VERSION ""

NS_ :

BS_:

BU_: VDM CMR_DSMC SOBDMC_HPCM_FD1 IPMA_ADAS PSCM ABS_ESC TCCM TCM_DSL PCM_HEV PCM ECM_Diesel GENERIC_GWMWakeup GWM _delete TSTR
VAL_TABLE_ DcacRdy_D_Stat 7 "NotUsed_2" 6 "NotUsed_1" 5 "Faulted" 4 "ProtectionTempearture" 3 "ProtectionOverload" 2 "ProtectionGfci" 1 "Active" 0 "Idle" ;
VAL_TABLE_ HvacCmprLim_D_Stat 7 "NotUsed_2" 6 "NotUsed_1" 5 "CompressorHeadPressure" 4 "AvailableTorque" 3 "PedalPosition" 2 "RPM" 1 "ECT" 0 "NoLimit" ;
VAL_TABLE_ AdvStrt_D_Stat 15 "NotUsed_15" 14 "NotUsed_14" 13 "NotUsed_13" 12 "NotUsed_12" 11 "NotUsed_11" 10 "NotUsed_10" 9 "NotUsed_9" 8 "NotUsed_8" 7 "NotUsed_7" 6 "NotUsed_6" 5 "NotUsed_5" 4 "NotUsed_4" 3 "NotUsed_3" 2 "NotUsed_2" 1 "NotUsed_1" 0 "NoAction" ;
VAL_TABLE_ VehOnSrc_D_Stat 15 "NotUsed_11" 14 "NotUsed_10" 13 "NotUsed_9" 12 "NotUsed_8" 11 "NotUsed_7" 10 "NotUsed_6" 9 "NotUsed_5" 8 "NotUsed_4" 7 "NotUsed_3" 6 "NotUsed_2" 5 "NotUsed_1" 4 "OverTheAir" 3 "RemoteParkAssist" 2 "RemoteStart" 1 "Manual" 0 "Off" ;
VAL_TABLE_ NoMessage_Msg1_63 31 "Message31" 30 "Message30" 29 "Message29" 28 "Message28" 27 "Message27" 26 "Message26" 25 "Message25" 24 "Message24" 23 "Message23" 22 "Message22" 21 "Message21" 20 "Message20" 19 "Message19" 18 "Message18" 17 "Message17" 16 "Message16" 15 "Message15" 14 "Message14" 13 "Message13" 12 "Message12" 11 "Message11" 10 "Message10" 9 "Message9" 8 "Message8" 7 "Message7" 6 "Message6" 5 "Message5" 4 "Message4" 3 "Message3" 2 "Message2" 1 "Message1" 0 "NoMessage" ;
VAL_TABLE_ TrlrRvrseEnbl_D2_Stat 7 "NotUsed" 6 "TbaActiveExpertActive" 5 "TbaActiveExpertAvail" 4 "TbaOffTrgActive" 3 "TbaOffTrgSetup" 2 "TbaSetup" 1 "TbaActive" 0 "Inactive" ;
VAL_TABLE_ Off_On_FlashChime 7 "NotUsed_5" 6 "NotUsed_4" 5 "NotUsed_3" 4 "NotUsed_2" 3 "NotUsed_1" 2 "FlashChime" 1 "On" 0 "Off" ;
VAL_TABLE_ DieslPrtcWarn_D_Rq 15 "NotUsed_4" 14 "NotUsed_3" 13 "NotUsed_2" 12 "NotUsed_1" 11 "OCR_ExhFilterClean_Stopped" 10 "OCR_ExhFilterCleaned" 9 "RgnOff_AtLimit" 8 "RgnOff_OverLoaded" 7 "RgnOff_Loaded" 6 "Exhaust_Filter_Full" 5 "DPF_OverLimit" 4 "DPF_AtLimit" 3 "ExhFilter_Drive_Completed" 2 "Cleaning_Exhaust_Filter" 1 "DPF_OverLoaded" 0 "DPF_Normal_Operation" ;
VAL_TABLE_ StrtrMtrCtlMsgTxt_D2_Rq 3 "NotUsed" 2 "ShiftToNeutralToStart" 1 "ShiftToParkToStart" 0 "NoRequest" ;
VAL_TABLE_ PaakMyKey_D_Rq 3 "NotUsed" 2 "ConfirmNewPaakMyKey" 1 "RequestNewPaakMyKey" 0 "None" ;
VAL_TABLE_ PaakMyKeySearch_D_Stat 7 "PhoneErased" 6 "LockButtonTimeOut" 5 "PressLockButton" 4 "ConfirmHmi" 3 "MyKeyPaakFound" 2 "StandardPaakFound" 1 "NoValidPaakFound" 0 "Null" ;
VAL_TABLE_ TrlrIdType_D_Stat 3 "Gooseneck" 2 "FifthWheel" 1 "Conventional" 0 "Null" ;
VAL_TABLE_ TrlrAidSetup_D2_Rq 15 "NotUsed_9" 14 "NotUsed_8" 13 "NotUsed_7" 12 "NotUsed_6" 11 "NotUsed_5" 10 "NotUsed_4" 9 "NotUsed_3" 8 "NotUsed_2" 7 "NotUsed_1" 6 "CompleteSetup" 5 "ReturnToSetup" 4 "StickerNotCircled" 3 "ConfirmSetup" 2 "EndSetup" 1 "BeginSetup" 0 "Inactive" ;
VAL_TABLE_ TrlrAidEnbl_D2_Rq 7 "NotUsed_4" 6 "NotUsed_3" 5 "NotUsed_2" 4 "NotUsed_1" 3 "Deactivate" 2 "ActivateTrg" 1 "ActivateTba" 0 "Inactive" ;
VAL_TABLE_ BattChrgMde_D_Actl 3 "NotUsed" 2 "ConstantCurrent" 1 "ConstantVoltage" 0 "NotCharging" ;
VAL_TABLE_ LcwaLeft_D_Stat 7 "Faulty" 6 "NotUsed_3" 5 "NotUsed_2" 4 "NotUsed_1" 3 "Disabled" 2 "TemporaryUnavailable" 1 "SensorBlocked" 0 "Available" ;
VAL_TABLE_ LcwaMsgTxt_D_Stat 3 "SodXFaulty" 2 "SodXBlocked" 1 "TrailerConnected" 0 "NoMessage" ;
VAL_TABLE_ Level_0_3 3 "Level_3" 2 "Level_2" 1 "Level_1" 0 "Level_0" ;
VAL_TABLE_ SteWhlSwtchMde_D_Stat 3 "NotUsed_2" 2 "NotUsed_1" 1 "Dialog" 0 "Domain" ;
VAL_TABLE_ TrlrRvrse_D_Stat 3 "Faulty" 2 "TrailerReverseGuidanceLite" 1 "On" 0 "Off" ;
VAL_TABLE_ TrlrAid_D2_Stat 15 "Faulty" 14 "NotUsed_4" 13 "NotUsed_3" 12 "NotUsed_2" 11 "NotUsed_1" 10 "DirtyCamera" 9 "IncorrectLighting" 8 "TrackingLost" 7 "TrackingUnknownConfidence" 6 "TrackingHighConfidence" 5 "TrackingMediumConfidence" 4 "TrackingLowConfidence" 3 "TurnRequested" 2 "DriveStraighRequested" 1 "Initializing" 0 "NotTracking" ;
VAL_TABLE_ AwdDrvMde_D2 15 "Faulty" 14 "NotUsed_7" 13 "NotUsed_6" 12 "NotUsed_5" 11 "NotUsed_4" 10 "NotUsed_3" 9 "NotUsed_2" 8 "NotUsed_1" 7 "NotAvailable" 6 "TowHaul" 5 "RockCrawl" 4 "Baja" 3 "MudAndSand" 2 "Weather" 1 "Sport" 0 "Normal" ;
VAL_TABLE_ TrlrAidSetup_D2_Stat 7 "NotUsed_2" 6 "NotUsed_1" 5 "SetupAcquisitionSuccess" 4 "TbaTadMonitor" 3 "SetupStartAcquisition" 2 "SetupPrepForAcquisition" 1 "TbaActive" 0 "Null" ;
VAL_TABLE_ CamraRearOn_D2_Stat2 7 "Faulty" 6 "NotUsed_3" 5 "NotUsed_2" 4 "NotUsed_1" 3 "Decommission" 2 "Activate" 1 "Deactivate" 0 "Null" ;
VAL_TABLE_ AirCondClu_D_Stat 7 "NotUsed" 6 "FetLifeLimitReached" 5 "FetOpenCircuit" 4 "FetOutputShortToPower" 3 "FetOutputShortToGround" 2 "FetNotControlled" 1 "OnPowerToLoad" 0 "OffNoPowerToLoad" ;
VAL_TABLE_ BattChrgTrgtSoC_D_Rq 7 "Percent_50" 6 "Percent_60" 5 "Percent_70" 4 "Percent_80" 3 "Percent_85" 2 "Percent_90" 1 "Percent_95" 0 "Percent_100" ;
VAL_TABLE_ OffNormalSoft 3 "NotUsed" 2 "Soft" 1 "Normal" 0 "Off" ;
VAL_TABLE_ OffOnDisabledInhibited 3 "Inhibited" 2 "Disabled" 1 "On" 0 "Off" ;
VAL_TABLE_ DgtlCommGtwyMde_D_Rq 15 "NotUsed_10" 14 "NotUsed_9" 13 "NotUsed_8" 12 "NotUsed_7" 11 "NotUsed_6" 10 "NotUsed_5" 9 "NotUsed_4" 8 "NotUsed_3" 7 "NotUsed_2" 6 "NotUsed_1" 5 "AcPnC" 4 "AcEIM" 3 "DcPnC" 2 "DcEIM" 1 "AttemptDgtlComm" 0 "NoDgtlComm" ;
VAL_TABLE_ BattDcCnnct_D_Cmd 7 "NotUsed_3" 6 "NotUsed_2" 5 "NotUsed_1" 4 "WeldCheck" 3 "OkToDischarge" 2 "Closed" 1 "Precharge" 0 "Open" ;
VAL_TABLE_ Null_NoFault_Fault 3 "NotUsed" 2 "Fault" 1 "NoFault" 0 "Null" ;
VAL_TABLE_ ModemReset_D_Rq 15 "NotUsed_11" 14 "NotUsed_10" 13 "NotUsed_9" 12 "NotUsed_8" 11 "NotUsed_7" 10 "NotUsed_6" 9 "NotUsed_5" 8 "NotUsed_4" 7 "NotUsed_3" 6 "BrandConnectReset2" 5 "BrandConnectReset1" 4 "CcsReset" 3 "OnlineTrafficReset" 2 "PaakReset" 1 "WifiHotspotReset" 0 "Null" ;
VAL_TABLE_ PrkAsstSlotId_D_Stat 7 "Faulty" 6 "Slot6" 5 "Slot5" 4 "Slot4" 3 "Slot3" 2 "Slot2" 1 "Slot1" 0 "NoSlotFound" ;
VAL_TABLE_ RstrnOnPsngr_D_RqMnu 15 "Faulty" 14 "NotUsed_11" 13 "NotUsed_10" 12 "ConfiguredOff" 11 "NotUsed_9" 10 "On" 9 "NotUsed_8" 8 "NotUsed_7" 7 "NotUsed_6" 6 "NotUsed_5" 5 "Off" 4 "NotUsed_4" 3 "NotUsed_3" 2 "NotUsed_2" 1 "NotUsed_1" 0 "NoAction" ;
VAL_TABLE_ BalrInnrLeft_D_Stat 3 "Reporting" 2 "NotReporting" 1 "SystemStandby" 0 "Initialization" ;
VAL_TABLE_ Zero_1_2_4 3 "Four" 2 "Two" 1 "One" 0 "Zero" ;
VAL_TABLE_ NoReq_AutoUp_Stop 3 "NotUsed" 2 "Stop" 1 "AutoUp" 0 "NoRequest" ;
VAL_TABLE_ BalrSnsLeft_D_Falt 3 "Invalid" 2 "SystemFailure" 1 "Blocked" 0 "Clear" ;
VAL_TABLE_ Null_Low_Med_High 3 "High" 2 "Medium" 1 "Low" 0 "Null" ;
VAL_TABLE_ Null_NotPressed_Pressed 3 "NotUsed" 2 "Pressed" 1 "NotPressed" 0 "Null" ;
VAL_TABLE_ Low_Med_High 3 "NotUsed" 2 "High" 1 "Medium" 0 "Low" ;
VAL_TABLE_ Null_NotAvail_Avail 3 "NotUsed" 2 "Available" 1 "NotAvailable" 0 "Null" ;
VAL_TABLE_ ChrgGoTMnte_D_Stat 15 "NotUsed_4" 14 "NotUsed_3" 13 "NotUsed_2" 12 "NotUsed_1" 11 "Minute_55" 10 "Minute_50" 9 "Minute_45" 8 "Minute_40" 7 "Minute_35" 6 "Minute_30" 5 "Minute_25" 4 "Minute_20" 3 "Minute_15" 2 "Minute_10" 1 "Minute_5" 0 "Minute_0" ;
VAL_TABLE_ NoData_Faulty_1E_1F 31 "Faulty" 30 "NoDataExists" ;
VAL_TABLE_ PwFlwBatt_D_Dsply 15 "NotUsed_8" 14 "NotUsed_7" 13 "NotUsed_6" 12 "NotUsed_5" 11 "NotUsed_4" 10 "NotUsed_3" 9 "NotUsed_2" 8 "NotUsed_1" 7 "FlwFromWallToBatt" 6 "FlwFromAllWhlsToBatt" 5 "FlwFromBattToAllWhls" 4 "FlwFromFrontWhlsToBatt" 3 "FlwFromBattToFrontWhls" 2 "FlwFromRearWhlsToBatt" 1 "FlwFromBattToRearWhls" 0 "NoFlow" ;
VAL_TABLE_ PwFlwFuelDrv_D_Dsply 7 "NotUsed_4" 6 "NotUsed_3" 5 "NotUsed_2" 4 "NotUsed_1" 3 "FlwFromFuelToAllWhls" 2 "FlwFromFuelToFrontWhls" 1 "FlwFromFuelToRearWhls" 0 "NoFlow" ;
VAL_TABLE_ TrlrAidMsgTxt_D2_Rq 63 "Message63" 62 "Message62" 61 "Message61" 60 "Message60" 55 "Message55" 50 "Message50" 45 "Message45" 40 "Message40" 35 "Message35" 31 "Message31" 30 "Message30" 29 "Message29" 28 "Message28" 27 "Message27" 26 "Message26" 25 "Message25" 24 "Message24" 23 "Message23" 22 "Message22" 21 "Message21" 20 "Message20" 19 "Message19" 18 "Message18" 17 "Message17" 16 "Message16" 15 "Message15" 14 "Message14" 13 "Message13" 12 "Message12" 11 "Message11" 10 "Message10" 9 "Message9" 8 "Message8" 7 "Message7" 6 "Message6" 5 "Message5" 4 "Message4" 3 "Message3" 2 "Message2" 1 "Message1" 0 "NoMessage" ;
VAL_TABLE_ TrlrAidEnbl_D2_Stat 7 "NotUsed_1" 6 "TbaActiveExpertActive" 5 "TbaActiveExpertAvail" 4 "TbaOffTrgActive" 3 "TbaOffTrgSetup" 2 "TbaSetup" 1 "TbaActive" 0 "Inactive" ;
VAL_TABLE_ RbaCta_D_Stat 7 "Faulty" 6 "NotUsed_2" 5 "NotUsed_1" 4 "Invalid" 3 "Disabled" 2 "On" 1 "Trailer_Tow_Off" 0 "Off" ;
VAL_TABLE_ NoRequest_Mode1_2_3 3 "Mode_3" 2 "Mode_2" 1 "Mode_1" 0 "NoRequest" ;
VAL_TABLE_ RvltnMatchAllw_D_Stat 3 "RevolutionMatchDisabled" 2 "RevolutionMatchEnabled" 1 "ChangeWithDriveMode" 0 "NoSelection" ;
VAL_TABLE_ BattTracCnnct_D_Cmd 7 "NotUsed_3" 6 "NotUsed_2" 5 "NotUsed_1" 4 "WeldCheck" 3 "OkToDischarge" 2 "Closed" 1 "Precharge" 0 "Open" ;
VAL_TABLE_ NotDiagnose_FailPass 3 "NotUsed" 2 "Pass" 1 "Fail" 0 "Not_Diagnose_Yet" ;
VAL_TABLE_ Null_Off_UnavailFaulty 3 "Faulty" 2 "Unavailable" 1 "Off" 0 "Null" ;
VAL_TABLE_ OffOnDisabledNotUsed 3 "NotUsed" 2 "Disabled" 1 "On" 0 "Off" ;
VAL_TABLE_ OffGraphicTextBoth 3 "Both" 2 "Text" 1 "Graphic" 0 "Off" ;
VAL_TABLE_ NoneInactiveActive_NotUsed 3 "NotUsed" 2 "Active" 1 "Inactive" 0 "None" ;
VAL_TABLE_ Off_On_NotUsed 3 "NotUsed_2" 2 "NotUsed_1" 1 "On" 0 "Off" ;
VAL_TABLE_ RbaSys_D_Stat 3 "Faulty" 2 "Available" 1 "Suspended" 0 "Disabled" ;
VAL_TABLE_ BrkAppl_D_RqPt 3 "BrakesSlowRelease" 2 "BrakesFastRelease" 1 "BrakesEngage" 0 "NotActive" ;
VAL_TABLE_ Mtr2State_D_ActlMntr 7 "Faulty" 6 "NoDataExists" 5 "NotUsed_1" 4 "ReadinessState" 3 "DeactivationState" 2 "PowerGeneration" 1 "PowerConsumption" 0 "Null" ;
VAL_TABLE_ HybVehMde_D_ActlMntr 7 "Faulty" 6 "NoDataExists" 5 "NotUsed_2" 4 "NotUsed_1" 3 "Fuel" 2 "HybridElectric" 1 "AllElectric" 0 "Null" ;
VAL_TABLE_ ChrgStat_D_ActlMntr 7 "Faulty" 6 "NoDataExists" 5 "NotUsed" 4 "ChargingCompleted" 3 "NotCharging" 2 "ChargingInDrivingState" 1 "ChargingInParkingState" 0 "Null" ;
VAL_TABLE_ Null_HiPower_Low_Med 3 "MediumPower" 2 "LowPower" 1 "HighPower" 0 "Null" ;
VAL_TABLE_ Inactive_Enable_Disable_NotUsed 0 "Inactive" 2 "Disable" 1 "Enable" ;
VAL_TABLE_ Inactive_OffOn_NotUsed 0 "Inactive" 1 "On" 2 "Off" 3 "NotUsed" ;
VAL_TABLE_ Null_NotPressed_Faulty 3 "Faulty" 2 "Pressed" 1 "NotPressed" 0 "Null" ;
VAL_TABLE_ TrailCtl_D_Stat 7 "Faulty" 6 "DescentOnly" 5 "EnabledDeny" 4 "StandbyOverThreshold" 3 "StandbyOverride" 2 "Active" 1 "EnabledDescent" 0 "Off" ;
VAL_TABLE_ Faulty_3F 63 "Faulty" ;
VAL_TABLE_ ChrgOvrdExitScrn_D_Rq 3 "NotUsed_1" 2 "Request_override" 1 "Do_not_request_override" 0 "Inactive" ;
VAL_TABLE_ Quality_Data_Faulty 3 "OK" 2 "Not_Within_Specifications" 1 "Eval_In_Progress" 0 "Faulty" ;
VAL_TABLE_ TrlrHitchYaw_D_Stat 15 "Faulty" 14 "NotUsed_4" 13 "NotUsed_3" 12 "NotUsed_2" 11 "NotUsed_1" 10 "FaultyYrsuConnection" 9 "FaultyYrsu" 8 "HiConfdLrndAngle" 7 "LowConfdLrndAngle" 6 "HiConfdAngleMem" 5 "LowConfdAngleMem" 4 "InitNoTadAngle" 3 "InitInputs" 2 "TadTrlrDataOutOfRange" 1 "TadNotWithinSpecification" 0 "NoConnectionWithYrsu" ;
VAL_TABLE_ NoData_Faulty_FFFFFFFFFFFE_FF -1 "Faulty_FFFFFFFFFFFF" -2 "NoDataExists_FFFFFFFFFFFE" ;
VAL_TABLE_ NoFault_Fault 1 "Fault" 0 "No_Fault" ;
VAL_TABLE_ OtaTrg_D_Stat 3 "NotUsed_1" 2 "Accepted" 1 "NotAccepted" 0 "Null" ;
VAL_TABLE_ EdmMsgTxt_D_Rq 15 "NotUsed_4" 14 "NotUsed_3" 13 "NotUsed_2" 12 "NotUsed_1" 11 "OverallGoodScore" 10 "WorkOnCompliance" 9 "GoodCompliance" 8 "WorkOnGearShifting" 7 "GoodGearShifting" 6 "WorkOnEfficientSpeed" 5 "GoodEfficientSpeed" 4 "WorkOnDeceleration" 3 "GoodDeceleration" 2 "WorkOnAcceleration" 1 "GoodAcceleration" 0 "NoMessage" ;
VAL_TABLE_ EdmLamp_D_Dsply 15 "NotUsed_7" 14 "NotUsed_6" 13 "NotUsed_5" 12 "NotUsed_4" 11 "NotUsed_3" 10 "NotUsed_2" 9 "NotUsed_1" 8 "CoastingEngineBrake" 7 "CoastingShiftToNeutral" 6 "FreewayJunction" 5 "Curve2" 4 "Curve1" 3 "SpeedLimit" 2 "Crossing" 1 "FreewayExit" 0 "NoRecommendation" ;
VAL_TABLE_ AwdCnnct_D_Stat 3 "Connecting" 2 "Disconnecting" 1 "Connected" 0 "Disconnected" ;
VAL_TABLE_ EngAirFiltMsgTxt_D_Rq 7 "NotUsed_2" 6 "NotUsed_1" 5 "EngineAirFilterMonitorFalt" 4 "ResetComplete" 3 "Clogged" 2 "ReplaceNow" 1 "ReplaceSoon" 0 "NoMessage" ;
VAL_TABLE_ ElPwPoint_D_Rq 3 "On" 2 "Off2" 1 "Off1" 0 "Null" ;
VAL_TABLE_ EngExhMdeQuiet_D2_Rq 7 "NotUsed_3" 6 "NotUsed_2" 5 "NotUsed_1" 4 "Track" 3 "Sport" 2 "Normal" 1 "Stealth" 0 "Null" ;
VAL_TABLE_ RearDiffThrml_D_Stat 3 "NotUsed_1" 2 "AboveThermalLimit" 1 "ThermalLimit" 0 "Normal" ;
VAL_TABLE_ NoInhibit_Inhibit 1 "Inhibit" 0 "NoInhibit" ;
VAL_TABLE_ PersRecallSrc_D_Actl 7 "NotUsed_3" 6 "NotUsed_2" 5 "NotUsed_1" 4 "MemorySwitch" 3 "RemoteStart" 2 "KeyFob" 1 "CenterStack" 0 "Null" ;
VAL_TABLE_ BattTracChiller_D_Stat 3 "NotUsed" 2 "ChillerNotAvailable" 1 "ChillerBrieflyAvailable" 0 "ChillerAvailable" ;
VAL_TABLE_ SelDrvMdeChassis2_D_Rq 31 "Faulty" 30 "NotUsed17" 29 "NotUsed16" 28 "NotUsed15" 27 "NotUsed14" 26 "NotUsed13" 25 "NotUsed12" 24 "NotUsed11" 23 "NotUsed10" 22 "NotUsed9" 21 "NotUsed8" 20 "NotUsed7" 19 "NotUsed6" 18 "NotUsed5" 17 "NotUsed4" 16 "NotUsed3" 15 "NotUsed2" 14 "RoughRoadMode" 13 "TrackMode" 12 "HighSpeedDesertMode" 11 "TowHaulMode" 10 "RockCrawlMode" 9 "SandMode" 8 "MudAndRutsMode" 7 "LowMuMode" 6 "ComfortAdaptiveMode" 5 "ComfortMode" 4 "SportAdaptiveMode" 3 "SportMode" 2 "EconomyMode" 1 "NormalAdaptiveMode" 0 "NormalMode" ;
VAL_TABLE_ TrnFaltOpenClu_B_Stat 1 "MayOpenClutch" 0 "Normal" ;
VAL_TABLE_ UrbanAreaDetct_D_Stat 3 "NotUsed_1" 2 "City" 1 "Subdivision" 0 "None" ;
VAL_TABLE_ Closed_Open 1 "Open" 0 "Closed" ;
VAL_TABLE_ AdbBrdrDist 15 "DistGreater800m" 14 "Dist700mTo800m" 13 "Dist600mTo700m" 12 "Dist500mTo600m" 11 "Dist400mTo500m" 10 "Dist300mTo400m" 9 "Dist200mTo300m" 8 "Dist175mTo200m" 7 "Dist150mTo175m" 6 "Dist125mTo150m" 5 "Dist100mTo125m" 4 "Dist75mTo100m" 3 "Dist50mTo75m" 2 "Dist25mTo50m" 1 "Dist15mTo25m" 0 "Dist0mTo15m" ;
VAL_TABLE_ TCU_ESN_D_Rq 3 "NotUsed" 2 "TCU_ESN_Request" 1 "NoRequest" 0 "Inactive" ;
VAL_TABLE_ FactoryReset_Rq 1 "ResetFactoryDefaults" 0 "Inactive" ;
VAL_TABLE_ TCU_Init_Actvtn_St 3 "NotUsed" 2 "InitialActivateDeny" 1 "InitialActivateAccept" 0 "Invalid" ;
VAL_TABLE_ TCU_Final_Actvtn_St 3 "NotUsed" 2 "FinalActivateDeny" 1 "FinalActivateAccept" 0 "Invalid" ;
VAL_TABLE_ WaitToStartLamp_D_Falt 3 "NotUsed" 2 "Wait_to_start_lamp_failed" 1 "Diagnosis_not_ready" 0 "Wait_to_start_lamp_OK" ;
VAL_TABLE_ BattTracCoolLvl_D_Rq 7 "Faulty" 6 "NotUsed" 5 "ChillerCoolingBattFirst" 4 "ChillerCoolingCabinFirst" 3 "ForcedCoolingRadiator" 2 "OpportunisticCoolingRad" 1 "CoolantFlowBypassLine" 0 "Off" ;
VAL_TABLE_ BattClntVlvOvrrd_D_Rq 3 "NotUsed" 2 "OverrideTbcvToChiller" 1 "OverrideTbcvToRadiator" 0 "NoOverrideToTbcvCLogic" ;
VAL_TABLE_ NonMagnetic_Magnetic 1 "Magnetic" 0 "NonMagnetic" ;
VAL_TABLE_ RideHghtMde_D_Stat 15 "Faulty" 14 "NotUsed_5" 13 "NotUsed_4" 12 "NotUsed_3" 11 "NotUsed_2" 10 "NotUsed_1" 9 "AdjUpAero" 8 "AdjUpOffRoad" 7 "AdjUpNormal" 6 "AdjDownKneel" 5 "AdjDownAero" 4 "AdjDownNormal" 3 "OffRoad" 2 "Kneel" 1 "Aero" 0 "Normal" ;
VAL_TABLE_ AutoTowAllw_D_StatMnu 3 "TowHaulCommandedOn" 2 "AutoTowHaulEnabled" 1 "AutoTowHaulDisabled" 0 "NoSelection" ;
VAL_TABLE_ SrpEventRight_D_Stat 3 "Faulty" 2 "Bump" 1 "Pothole" 0 "NoEvent" ;
VAL_TABLE_ RearDiff_D_Stat 15 "NotUsed_7" 14 "NotUsed_6" 13 "NotUsed_5" 12 "NotUsed_4" 11 "NotUsed_3" 10 "NotUsed_2" 9 "NotUsed_1" 8 "TorqueReqNotHonored" 7 "MissingSignal" 6 "ModuleFault" 5 "HydroTempSensorFault" 4 "ClutchPressSensorFault" 3 "AccumPressSensorFault" 2 "ControlValveFault" 1 "MotorFault" 0 "Normal" ;
VAL_TABLE_ NotAllowed_Allowed 1 "Allowed" 0 "NotAllowed" ;
VAL_TABLE_ EngTrlrCnnct_D_Stat 3 "NotUsed_1" 2 "UnverifiedTrailer" 1 "HeavyTrailer" 0 "NoTrailer" ;
VAL_TABLE_ Faulty_FFFF 65535 "Faulty" ;
VAL_TABLE_ NoData_Faulty_3FFE_3FFF 16383 "Faulty" 16382 "NoDataExists" ;
VAL_TABLE_ Faulty_3FFF 16383 "Faulty" ;
VAL_TABLE_ NotExceeded_Exceeded 1 "Exceeded" 0 "NotExceeded" ;
VAL_TABLE_ EmgcyCall_D_Stat 7 "NotUsed_3" 6 "NotUsed_2" 5 "NotUsed_1" 4 "ManualEmergencyCall" 3 "AutoEmergencyCall" 2 "NoEvent" 1 "EmergencyCallNotSupported" 0 "Null" ;
VAL_TABLE_ NotAsserted_Asserted 1 "Asserted" 0 "NotAsserted" ;
VAL_TABLE_ AirSprngRate_D_Stat 3 "Faulty" 2 "Firm" 1 "Medium" 0 "Soft" ;
VAL_TABLE_ AirSprngRate_D_Rq 3 "NoRequest" 2 "Firm" 1 "Medium" 0 "Soft" ;
VAL_TABLE_ GearLvr_D_ActlDrv 15 "Fault" 14 "Unknown_Position" 13 "NotUsed_2" 12 "NotUsed_1" 11 "Range6" 10 "Range5" 9 "Range4" 8 "Range3_M3_L3" 7 "Range2_M2_L2" 6 "Range1_M1_L1" 5 "Low" 4 "Sport_DriveSport_Mposition" 3 "Drive" 2 "Neutral" 1 "Reverse" 0 "Park" ;
VAL_TABLE_ ChrgrInPwMde_D_Actl 15 "NotUsed_9" 14 "NotUsed_8" 13 "NotUsed_7" 12 "NotUsed_6" 11 "NotUsed_5" 10 "NotUsed_4" 9 "NotUsed_3" 8 "EvseFault" 7 "EvseNotCompatible" 6 "IcCharging" 5 "DcCharging" 4 "AcDigital" 3 "AcBasic" 2 "DigitalCommDetected" 1 "EvsePaused" 0 "EvseNotDetected" ;
VAL_TABLE_ ChrgCordLck_D_Stat 7 "Faulty" 6 "LockFail" 5 "UnlockFail" 4 "LockInProgress" 3 "UnlockInProgress" 2 "Lock" 1 "Unlock" 0 "Retain" ;
VAL_TABLE_ LkaActvStats_D2_Req 7 "NotUsed" 6 "LkaIncrIntervRight" 5 "LkaSupprRight" 4 "LkaStandIntervRight" 3 "LkaSupprLeft" 2 "LkaStandIntervLeft" 1 "LkaIncrIntervLeft" 0 "LkaNoInterv" ;
VAL_TABLE_ OffOnNoDataFaulty 3 "Faulty" 2 "No_Data_Exists" 1 "On" 0 "Off" ;
VAL_TABLE_ NoMessage_Msg1_3 3 "Message3" 2 "Message2" 1 "Message1" 0 "NoMessage" ;
VAL_TABLE_ TrnRng_D_RqGsm 15 "Fault" 14 "UnknownPosition" 13 "Undefined_2" 12 "Undefined_1" 11 "_6" 10 "_5" 9 "_4" 8 "_3" 7 "_2" 6 "_1" 5 "Low" 4 "Sport_DriveSport" 3 "Drive" 2 "Neutral" 1 "Reverse" 0 "Park" ;
VAL_TABLE_ PrkBrkActv_D_RqGsmGear 3 "NotUsed" 2 "RequestParkBrakeEngage" 1 "NoRequest" 0 "Null" ;
VAL_TABLE_ TrnPrkSys_D_Actl 15 "Faulty" 14 "NotUsed_5" 13 "NotUsed_4" 12 "NotUsed_3" 11 "NotUsed_2" 10 "NotUsed_1" 9 "FrequencyError" 8 "OutOfRangeHigh" 7 "OutOfRangeLow" 6 "Override" 5 "OutOfPark" 4 "TransitionCloseToOutOfPark" 3 "AtNoSpring" 2 "TransitionCloseToPark" 1 "Park" 0 "NotKnown" ;
VAL_TABLE_ OKLowUnknownInvalid 3 "Invalid" 2 "Unknown" 1 "Low" 0 "OK" ;
VAL_TABLE_ Dsp_RotAddrBtnEv_St 15 "NotUsed_1" 14 "Pos_7Steps" 13 "Pos_6Steps" 12 "Pos_5Steps" 11 "Pos_4Steps" 10 "Pos_3Steps" 9 "Pos_2Steps" 8 "Pos_1Step" 7 "NotPressed" 6 "Neg_1Steps" 5 "Neg_2Steps" 4 "Neg_3Steps" 3 "Neg_4Steps" 2 "Neg_5Steps" 1 "Neg_6Steps" 0 "Neg_7Steps" ;
VAL_TABLE_ PrkAidDrvDir_D_Stat 7 "NotUsed_2" 6 "NotUsed_1" 5 "BackwardNegative" 4 "ForwardNegative" 3 "BackwardPositive" 2 "ForwardPositive" 1 "NoMotion" 0 "DirectionNotKnown" ;
VAL_TABLE_ EngExhMdeQuiet_D2_Stat 7 "Faulty" 6 "NotUsed_2" 5 "NotUsed_1" 4 "Track" 3 "Sport" 2 "Normal" 1 "Stealth" 0 "Null" ;
VAL_TABLE_ GasPrtc_D_RqDsply 7 "NotUsed_5" 6 "NotUsed_4" 5 "NotUsed_3" 4 "NotUsed_2" 3 "NotUsed_1" 2 "GpfOverLimit" 1 "GpfAtLimit" 0 "NormalOperation" ;
VAL_TABLE_ TjaWarn_D_Rq 7 "NotUsed_4" 6 "NotUsed_3" 5 "NotUsed_2" 4 "NotUsed_1" 3 "HardTakeOverLevel2" 2 "HardTakeOverLevel1" 1 "TrafficJamAssistCancel" 0 "NoWarning" ;
VAL_TABLE_ Faulty_7FF 2047 "Faulty" ;
VAL_TABLE_ Tja_D_Stat 7 "NotUsed_1" 6 "ActiveWarningRight" 5 "ActiveWarningLeft" 4 "ActiveInterventionRight" 3 "ActiveInterventionLeft" 2 "Active" 1 "Standby" 0 "Off" ;
VAL_TABLE_ TjaMsgTxt_D_Dsply 7 "NotUsed_4" 6 "NotUsed_3" 5 "NotUsed_2" 4 "NotUsed_1" 3 "TurnOnAdaptCruiseControl" 2 "TrafficJamAssistSelected" 1 "TrafficJamAssistUnavailabl" 0 "NoMessage" ;
VAL_TABLE_ PwSrcULowMde_D_Actl 3 "NotUsed_1" 2 "ReverseBoost" 1 "ForwardBuck" 0 "Standby" ;
VAL_TABLE_ ApaTrgtDist_D_Stat 15 "Step15" 14 "Step14" 13 "Step13" 12 "Step12" 11 "Step11" 10 "Step10" 9 "Step9" 8 "Step8" 7 "Step7" 6 "Step6" 5 "Step5" 4 "Step4" 3 "Step3" 2 "Step2" 1 "Step1" 0 "Off" ;
VAL_TABLE_ Memory_2_SwPsngr_Stat 1 "Pressed" 0 "Null" ;
VAL_TABLE_ Pers3Key_D_Stat 3 "NotUsed_1" 2 "KeyUnAssociated" 1 "KeyAssociated" 0 "Null" ;
VAL_TABLE_ PwSrcULoMde_D_Rq 3 "NotUsed_1" 2 "ReverseBoost" 1 "ForwardBuck" 0 "Standby" ;
VAL_TABLE_ AccMsgTxt_D2_Rq 15 "NotUsed_1" 14 "NCC_Enabled_Warning" 13 "IACC_TJA_Selected" 12 "ACC_TJA_Selected" 11 "IACC_Selected" 10 "Press_Brake_To_Hold" 9 "Only_Following_In_Low_Spd" 8 "TJA_Unavailable" 7 "Shift_Down" 6 "IACC_Unavailable" 5 "ACC_Selected" 4 "ACC_Overridden" 3 "Brake_Capacity_Warning" 2 "ACC_Cancelled" 1 "ACC_Unavailable" 0 "No_Text" ;
VAL_TABLE_ WakeAlarm0_B_Typ 1 "CanAndEcuDriveCircuit" 0 "CanOnly" ;
VAL_TABLE_ WakeAlarm0_D_Stat 3 "PublisherReset" 2 "Wake" 1 "AlarmRunning" 0 "AlarmOff" ;
VAL_TABLE_ EmPrflNo_D_Rq 7 "NotUsed_3" 6 "NotUsed_2" 5 "NotUsed_1" 4 "Pers4" 3 "Pers3" 2 "Pers2" 1 "Pers1" 0 "Null" ;
VAL_TABLE_ EmPrflKeyAssoc_D_Rq 7 "NotUsed_3" 6 "DisassociatePhone" 5 "EnterPhoneAssociation" 4 "OverwriteKey" 3 "DisassociateKey" 2 "ExitKeyAssociation" 1 "EnterKeyAssociation" 0 "Null" ;
VAL_TABLE_ Em_D_Stat 3 "NotSupported" 2 "ProfilesOff" 1 "ProfilesOn" 0 "Null" ;
VAL_TABLE_ EmPrflButtnAssoc_D_Rq 3 "NotUsed" 2 "ExitButtonAssociation" 1 "EnterButtonAssociation" 0 "Null" ;
VAL_TABLE_ EmPrflNo_D_Stat 7 "NotUsed_3" 6 "NotUsed_2" 5 "NotUsed_1" 4 "Pers4" 3 "Pers3" 2 "Pers2" 1 "Pers1" 0 "Null" ;
VAL_TABLE_ EmPrflKeyAssoc_D_Stat 7 "WrongDevice" 6 "KeyAssociateFailed" 5 "KeyAssociateSuccess" 4 "KeyAlreadyInUse" 3 "KeyDisassociated" 2 "KeyAssociationExited" 1 "KeyAssociationEntered" 0 "Null" ;
VAL_TABLE_ EsaEnbl_D2_Rq 3 "NotConfigured" 2 "Enabled" 1 "Pending" 0 "Disabled" ;
VAL_TABLE_ PersNo_D_Actl 7 "Unused_3" 6 "Unused_2" 5 "NotDetermined" 4 "Vehicle" 3 "PERS_4" 2 "PERS_3" 1 "PERS_2" 0 "PERS_1" ;
VAL_TABLE_ WiprFront_D_Stat2 15 "NO_DATA_EXISTS" 14 "STALLED" 13 "NotUsed" 12 "AUTO_ADJUST" 11 "COURTESYWIPE" 10 "AUTO_HIGH" 9 "AUTO_LOW" 8 "WASH" 7 "MIST_FLICK" 6 "MAN_HIGH" 5 "MAN_LOW" 4 "MAN_INT_ON" 3 "MAN_INT_OFF" 2 "OFF_MOVING" 1 "AUTO_OFF" 0 "OFF" ;
VAL_TABLE_ TurnLghtSwtch_D_Stat2 3 "NotUsed" 2 "Right" 1 "Left" 0 "Off" ;
VAL_TABLE_ CcButtnOnOffCnclPress3 1 "Pressed" 0 "Not pressed" ;
VAL_TABLE_ SelDrvMdePos01_B_Avail 1 "Available" 0 "NotAvailable" ;
VAL_TABLE_ SelDrvMdePos01_D_Stat 31 "Faulty" 30 "SelDrvMde31" 29 "SelDrvMde30" 28 "SelDrvMde29" 27 "SelDrvMde28" 26 "SelDrvMde27" 25 "SelDrvMde26" 24 "SelDrvMde25" 23 "SelDrvMde24" 22 "SelDrvMde23" 21 "SelDrvMde22" 20 "SelDrvMde21" 19 "SelDrvMde20" 18 "SelDrvMde19" 17 "SelDrvMde18" 16 "SelDrvMde17" 15 "SelDrvMde16" 14 "SelDrvMde15" 13 "SelDrvMde14" 12 "SelDrvMde13" 11 "SelDrvMde12" 10 "SelDrvMde11" 9 "SelDrvMde10" 8 "SelDrvMde09" 7 "SelDrvMde08" 6 "SelDrvMde07" 5 "SelDrvMde06" 4 "SelDrvMde05" 3 "SelDrvMde04" 2 "SelDrvMde03" 1 "SelDrvMde02" 0 "SelDrvMde01" ;
VAL_TABLE_ ImmedFastMediumSlow 3 "Slow" 2 "Medium" 1 "Fast" 0 "Immediately" ;
VAL_TABLE_ AdbHiBeamKeepOff_D_Rq 3 "KeepBothOff" 2 "KeepLeftOff" 1 "KeepRightOff" 0 "BothFreeRunning" ;
VAL_TABLE_ AdbLampOnOff_D_Rq 3 "BothOn" 2 "LeftOnRightOff" 1 "RightOnLeftOff" 0 "BothOff" ;
VAL_TABLE_ AdbMde1_D_Rq 3 "MarkerLightFlashing" 2 "MarkerLightConstant" 1 "Spot" 0 "None" ;
VAL_TABLE_ Closed_Open_Active_Denied 3 "Denied" 2 "Active" 1 "Open" 0 "Closed" ;
VAL_TABLE_ OffLowMedMax 3 "Maximum" 2 "Medium" 1 "Low" 0 "Off" ;
VAL_TABLE_ IaccLamp_D_Rq 3 "NotUsed_2" 2 "NotUsed_1" 1 "DisplayIaccIcon" 0 "DoNotDisplayIaccIcon" ;
VAL_TABLE_ Low_High_Confidence 1 "High_Confidence" 0 "Low_Confidence" ;
VAL_TABLE_ Fault_Occupied_Empty_Un 3 "Unknown" 2 "Empty" 1 "Occupied" 0 "Fault" ;
VAL_TABLE_ Off_On_Flash_Triggered 3 "Triggered" 2 "Flash" 1 "On" 0 "Off" ;
VAL_TABLE_ IaccVLim_D_Rq 252 "NotUsed_2" 250 "LimitSpeed_250" 240 "LimitSpeed_240" 230 "LimitSpeed_230" 220 "LimitSpeed_220" 210 "LimitSpeed_210" 200 "LimitSpeed_200" 190 "LimitSpeed_190" 150 "LimitSpeed_150" 140 "LimitSpeed_140" 130 "LimitSpeed_130" 120 "LimitSpeed_120" 110 "LimitSpeed_110" 100 "LimitSpeed_100" 90 "LimitSpeed_90" 80 "LimitSpeed_80" 70 "LimitSpeed_70" 60 "LimitSpeed_60" 50 "LimitSpeed_50" 40 "LimitSpeed_40" 30 "LimitSpeed_30" 20 "LimtSpeed_20" 251 "NotUsed_1" 255 "Faulty" 254 "NoDataExists" 253 "NotUsed_3" 180 "LimitSpeed_180" 179 "LimitSpeed_179" 178 "LimitSpeed_178" 177 "LimitSpeed_177" 176 "LimitSpeed_176" 175 "LimitSpeed_175" 174 "LimitSpeed_174" 173 "LimitSpeed_173" 172 "LimitSpeed_172" 171 "LimitSpeed_171" 170 "LimitSpeed_170" 169 "LimitSpeed_169" 168 "LimitSpeed_168" 167 "LimitSpeed_167" 166 "LimitSpeed_166" 165 "LimitSpeed_165" 164 "LimitSpeed_164" 163 "LimitSpeed_163" 162 "LimitSpeed_162" 161 "LimitSpeed_161" 160 "LimitSpeed_160" 15 "LimitSpeed_15" 14 "LimitSpeed_14" 13 "LimitSpeed_13" 12 "LimitSpeed_12" 11 "LimitSpeed_11" 10 "LimitSpeed_10" 9 "LimitSpeed_9" 8 "LimitSpeed_8" 7 "LimitSpeed_7" 6 "LimitSpeed_6" 5 "LimitSpeed_5" 4 "LimitSpeed_4" 3 "LimitSpeed_3" 2 "LimitSpeed_2" 1 "LimitSpeed_1" 0 "LimitSpeed_0" ;
VAL_TABLE_ IaccVLimUnit_D_Rq 3 "NoDataExists" 2 "Mph" 1 "Kph" 0 "Null" ;
VAL_TABLE_ SelDrvMdeAwd_D_Rq 31 "Faulty" 30 "NotUsed_17" 29 "NotUsed_16" 28 "NotUsed_15" 27 "NotUsed_14" 26 "NotUsed_13" 25 "NotUsed_12" 24 "NotUsed_11" 23 "NotUsed_10" 22 "NotUsed_9" 21 "NotUsed_8" 20 "NotUsed_7" 19 "NotUsed_6" 18 "NotUsed_5" 17 "EvLaterChargeMode" 16 "EvNowMode" 15 "TrackMode" 14 "RoughRoadMode" 13 "NotAvailable" 12 "HighSpeedDesertMode_Baja" 11 "SportAdaptiveMode" 10 "RockCrawlMode" 9 "MudRutsMode" 8 "SandMode" 7 "EconomyMode" 6 "GrassGravelSnow" 5 "TowHaulMode" 4 "SportMode" 3 "Normal_4L" 2 "Normal_4A" 1 "Normal_2H" 0 "NormalMode" ;
VAL_TABLE_ SelDrvMdeAwd_D_Stat 0 "NotAvailable" 1 "Available" 2 "TemporarilyNotAvailable" 3 "Faulty" ;
VAL_TABLE_ SelDrvMdeAwd2_D_Stat 31 "Faulty" 30 "NotUsed_17" 29 "NotUsed_16" 28 "NotUsed_15" 27 "NotUsed_14" 26 "NotUsed_13" 25 "NotUsed_12" 24 "NotUsed_11" 23 "NotUsed_10" 22 "NotUsed_9" 21 "NotUsed_8" 20 "NotUsed_7" 19 "NotUsed_6" 18 "NotUsed_5" 17 "EvLaterChargeMode" 16 "EvNowMode" 15 "TrackMode" 14 "RoughRoadMode" 13 "NotAvailable" 12 "HighSpeedDesertMode_Baja" 11 "SportAdaptiveMode" 10 "RockCrawlMode" 9 "MudRutsMode" 8 "SandMode" 7 "EconomyMode" 6 "GrassGravelSnow" 5 "TowHaulMode" 4 "SportMode" 3 "Normal_4L" 2 "Normal_4A" 1 "Normal_2H" 0 "NormalMode" ;
VAL_TABLE_ RearDiffLckMsg2_D_Rq 15 "NotUsed_3" 14 "NotUsed_2" 13 "NotUsed_1" 12 "ElsdReduced" 11 "LockingFeatureNotAvailable" 10 "EsldOff" 9 "ElsdRestored" 8 "ElsdOverheated" 7 "Locker_Disabled" 6 "Locker_Enabled" 5 "LockerSpeed5" 4 "LockerSpeed4" 3 "LockerSpeed3" 2 "LockerSpeed2" 1 "LockerSpeed1" 0 "NormalNoMessage " ;
VAL_TABLE_ Counts_ZeroToSeven 4 "FourCounts" 3 "ThreeCounts" 2 "TwoCounts" 1 "OneCount" 0 "ZeroCounts" 7 "SevenOrMoreCounts" 6 "SixCounts" 5 "FiveCounts" ;
VAL_TABLE_ HeadLghtHiPrmsn_D_Stat 3 "CancelAndSuppress" 2 "Cancel" 1 "Hold" 0 "AllowChange" ;
VAL_TABLE_ SelDrvMdeSwtch 3 "Faulty" 2 "SwitchState2" 1 "SwitchState1" 0 "NotPressed" ;
VAL_TABLE_ NotAvail_Temp_Faulty 3 "Faulty" 2 "TemporarilyNotAvailable" 1 "Available" 0 "NotAvailable" ;
VAL_TABLE_ AwdDrvMde 7 "Faulty" 6 "NotAvailable" 5 "RockCrawl" 4 "Baja" 3 "MudAndSand" 2 "Weather" 1 "Sport" 0 "Normal" ;
VAL_TABLE_ SelDrvMdePt_D_Rq 31 "Faulty" 30 "NotUsed15" 29 "NotUsed14" 28 "NotUsed13" 27 "NotUsed12" 26 "NotUsed11" 25 "NotUsed10" 24 "NotUsed9" 23 "NotUsed8" 22 "NotUsed7" 21 "NotUsed6" 20 "NotUsed5" 19 "NotUsed4" 18 "EvLaterChargerMode" 17 "EvNowMode" 16 "DragMode" 15 "HighSpeedDesertMode_Baja" 14 "SportAdaptiveMode" 13 "NotAvailable_13" 12 "NotAvailable_12" 11 "NotAvailable_11" 10 "NotAvailable_10" 9 "RockCrawlMode" 8 "MudRutsMode" 7 "SandMode" 6 "EconomyMode" 5 "GrassGravelSnow" 4 "NotAvailable_04" 3 "TowHaulMode" 2 "NotAvailable_02" 1 "SportMode" 0 "NormalMode" ;
VAL_TABLE_ SelDrvMde_D_Stat 3 "NotUsed" 2 "DriveModeChangeRequest" 1 "DriveModeChangeSelection" 0 "NoDriveModeChangeRequest" ;
VAL_TABLE_ NoMessage_Msg1_15 15 "Message15" 14 "Message14" 13 "Message13" 12 "Message12" 11 "Message11" 10 "Message10" 9 "Message9" 8 "Message8" 7 "Message7" 6 "Message6" 5 "Message5" 4 "Message4" 3 "Message3" 2 "Message2" 1 "Message1" 0 "NoMessage" ;
VAL_TABLE_ SelDrvMdeChassis_D_Rq 31 "Faulty" 30 "NotUsed17" 29 "NotUsed16" 28 "NotUsed15" 27 "NotUsed14" 26 "NotUsed13" 25 "NotUsed12" 24 "NotUsed11" 23 "NotUsed10" 22 "NotUsed9" 21 "NotUsed8" 20 "NotUsed7" 19 "NotUsed6" 18 "NotUsed5" 17 "NotUsed4" 16 "NotUsed3" 15 "NotUsed2" 14 "NotUsed1" 13 "TrackMode" 12 "HighSpeedDesertMode" 11 "TowHaulMode" 10 "RockCrawlMode" 9 "SandMode" 8 "MudAndRutsMode" 7 "LowMuMode" 6 "ComfortAdaptiveMode" 5 "ComfortMode" 4 "SportAdaptiveMode" 3 "SportMode" 2 "EconomyMode" 1 "NormalAdaptiveMode" 0 "NormalMode" ;
VAL_TABLE_ NotAvailable_Available 1 "Available" 0 "NotAvailable" ;
VAL_TABLE_ PwStep_D_Stat 3 "PositionNotKnown" 2 "StepsNotStowed" 1 "StepsStowed" 0 "Off" ;
VAL_TABLE_ PwStep_D_DrvInhbt 3 "NotUsed" 2 "DriveInhibitMalfunction" 1 "DriveInhibited" 0 "DriveNotInhibited" ;
VAL_TABLE_ NoMessage_Msg1_31 31 "Message31" 30 "Message30" 29 "Message29" 28 "Message28" 27 "Message27" 26 "Message26" 25 "Message25" 24 "Message24" 23 "Message23" 22 "Message22" 21 "Message21" 20 "Message20" 19 "Message19" 18 "Message18" 17 "Message17" 16 "Message16" 15 "Message15" 14 "Message14" 13 "Message13" 12 "Message12" 11 "Message11" 10 "Message10" 9 "Message9" 8 "Message8" 7 "Message7" 6 "Message6" 5 "Message5" 4 "Message4" 3 "Message3" 2 "Message2" 1 "Message1" 0 "NoMessage" ;
VAL_TABLE_ VehTrvlDir_D_Stat 7 "Faulty" 6 "NoDataExists" 5 "NotUsed2" 4 "NotUsed1" 3 "Reverse" 2 "LikelyReverse" 1 "Forward" 0 "LikelyForward" ;
VAL_TABLE_ TrnRng_D_RqFap 7 "NotUsed3" 6 "NotUsed2" 5 "NotUsed1" 4 "Backwards" 3 "Forwards" 2 "NoMotion" 1 "Immobilize" 0 "NoRequest" ;
VAL_TABLE_ SelDrvMdeSusp_D_Stat 3 "Faulty" 2 "TemporarilyNotAvailable" 1 "Available" 0 "NotAvailable" ;
VAL_TABLE_ OffOnNoReqFaulty 3 "Faulty" 2 "NoRequest" 1 "On" 0 "Off" ;
VAL_TABLE_ LatCtl_D_Rq 7 "NotUsed4" 6 "NotUsed3" 5 "NotUsed2" 4 "NotUsed1" 3 "InterventionRight" 2 "InterventionLeft" 1 "ContinuousPathFollowing" 0 "NoLateralControl" ;
VAL_TABLE_ LatCtlSte_D_Stat 7 "NotUsed3" 6 "NotUsed2" 5 "NotUsed1" 4 "Denied" 3 "RampOut" 2 "ContLatControlInProgress" 1 "Available" 0 "Unavailable" ;
VAL_TABLE_ SlowMedFastImmed 3 "Immediately" 2 "Fast" 1 "Medium" 0 "Slow" ;
VAL_TABLE_ ComfortablePreciseNotUsed 3 "NotUsed2" 2 "NotUsed1" 1 "Precise" 0 "Comfortable" ;
VAL_TABLE_ LatCtlLim_D_Stat 3 "LimitWithDriverActive" 2 "LimitReached" 1 "LimitClose" 0 "LimitNotReached" ;
VAL_TABLE_ FuelLvlWarn_D_ActlEng 7 "DteLevel5Lowest" 6 "DteLevel4" 5 "DteLevel3" 4 "DteLevel2NonMyKey" 3 "DteLevel1MyKey" 2 "VeryLow" 1 "Low" 0 "OK" ;
VAL_TABLE_ AwdMde_D_RqDrv 7 "Faulty" 6 "NotUsed2" 5 "NoRequest" 4 "Neutral" 3 "FourByFourLow" 2 "FourByFourHigh" 1 "FourByFourAuto" 0 "FourByTwo" ;
VAL_TABLE_ ApaBrk_D_Stat 3 "Denied" 2 "Active" 1 "Open" 0 "Closed" ;
VAL_TABLE_ AdptDrvMdePt_D_Rq 7 "Faulty" 6 "NotUsed3" 5 "NotUsed2" 4 "NotUsed1" 3 "Powertrain2Sport" 2 "Powertrain2Normal" 1 "Powertrain2Comfort" 0 "AdaptiveNotActive" ;
VAL_TABLE_ AdptDrvMdeChassis_D_Rq 7 "Faulty" 6 "NotUsed3" 5 "NotUsed2" 4 "NotUsed1" 3 "Chassis2Sport" 2 "Chassis2Normal" 1 "Chassis2Comfort" 0 "AdaptiveNotActive" ;
VAL_TABLE_ PwStepMsgTxt_D_Rq 1 "DriveInhibited" 0 "NoMessage" 3 "NotUsed" 2 "Malfunction" ;
VAL_TABLE_ OffLowMedHigh 3 "High" 2 "Medium" 1 "Low" 0 "Off" ;
VAL_TABLE_ NotDeterminedLowMedHigh 3 "High" 2 "Medium" 1 "Low" 0 "NotDetermined" ;
VAL_TABLE_ CmbbObjClass_D_Stat 15 "NotUsed_9" 14 "NotUsed_8" 13 "NotUsed_7" 12 "NotUsed_6" 11 "NotUsed_5" 10 "NotUsed_4" 9 "NotUsed_3" 8 "NotUsed_2" 7 "NotUsed_1" 6 "Unclassified_Vehicle" 5 "Bicycle" 4 "Pedestrian" 3 "Truck" 2 "Motorcycle" 1 "Vehicle" 0 "Undetermined" ;
VAL_TABLE_ HeadLghtHiCtrl_D_RqAhb 7 "NotUsed2" 6 "NotUsed1" 5 "Auto_HiBeam" 4 "Auto_LoBeam" 3 "Flash" 2 "Man_HiBeam" 1 "Man_LoBeam" 0 "Null" ;
VAL_TABLE_ AhbHiBeam_D_Rq 3 "NotUsed" 2 "HighBeamRecommended" 1 "LowBeamRecommended" 0 "DeactivatedUnavailable" ;
VAL_TABLE_ AhbStatGfhbFdbk_D_Actl 3 "GfhbHighBeamFullyOn" 2 "GfhbHighBeamPartlyOn" 1 "GfhbHighBeamOff" 0 "GfhbUnavailable" ;
VAL_TABLE_ AhbcRampingV_D_Rq 3 "Slow" 2 "Medium" 1 "Fast" 0 "Immediately" ;
VAL_TABLE_ ApaGearShif_D_RqDrv 7 "NotUSed2" 6 "NotUsed1" 5 "ShiftToP" 4 "ShiftToN" 3 "ShiftToD" 2 "ShiftToR" 1 "NoRequest" 0 "Null" ;
VAL_TABLE_ ApaLongCtl_D_RqDrv 7 "NotUsed3" 6 "NotUsed2" 5 "ReleaseBrake" 4 "DriveBackward" 3 "DriveForward" 2 "Stop" 1 "NoRequest" 0 "Null" ;
VAL_TABLE_ ApaActvSide2_D_Stat 3 "NoSide" 2 "Right" 1 "Left" 0 "Null" ;
VAL_TABLE_ ApaScan_D_Stat 3 "ParkSlotReady" 2 "ParkSlotFound" 1 "NoParkSlot" 0 "Null" ;
VAL_TABLE_ ApaSelSapp_D_Stat 3 "NotConfigured" 2 "NotSelectable" 1 "Selectable" 0 "Null" ;
VAL_TABLE_ ApaSys_D_Stat 7 "Faulty" 6 "Finished" 5 "NotAccessible" 4 "ApaCancelled" 3 "Overspeed" 2 "On" 1 "Off" 0 "Null" ;
VAL_TABLE_ ApaSteScanMde_D_Stat 3 "Steering" 2 "Scanning" 1 "NotScanning" 0 "Null" ;
VAL_TABLE_ ApaAcsy_D_RqDrv 7 "CloseDoor" 6 "SelectSideRight" 5 "SelectSideLeft" 4 "CheckForObject" 3 "PressApaButton" 2 "SelectSide" 1 "NoRequest" 0 "Null" ;
VAL_TABLE_ ApaSteWhl_D_RqDrv 3 "TakeControl" 2 "RemoveHands" 1 "NoRequest" 0 "Null" ;
VAL_TABLE_ WiprFrontSwtch_D_Stat 15 "NotUsed6" 14 "NotUsed5" 13 "NotUsed4" 12 "NotUsed3" 11 "NotUsed2" 10 "NotUsed1" 9 "PositionNotDetermined" 8 "High" 7 "Low" 6 "Position6" 5 "Position5" 4 "Position4" 3 "Position3" 2 "Position2" 1 "Position1" 0 "Off" ;
VAL_TABLE_ Off_On_Unknown_Invalid 3 "Invalid" 2 "Unknown" 1 "On" 0 "Off" ;
VAL_TABLE_ Unknown_7FFE_Invalid_7FFF 32767 "Invalid" 32766 "Unknown" ;
VAL_TABLE_ OffOnNotUsedFaulty 3 "Faulty" 2 "NotUsed" 1 "On" 0 "Off" ;
VAL_TABLE_ BrkBstrVac_D_Stat 3 "NotUsed" 2 "BoosterVacEstimator" 1 "BoosterVacSensor" 0 "NoBoosterVacuumMonitor" ;
VAL_TABLE_ AwdMde_D_RqArb 7 "Faulty" 6 "NotUsed2" 5 "NoRequest" 4 "Neutral" 3 "FourByFourLow" 2 "FourByFourHigh" 1 "FourByFourAuto" 0 "FourByTwo" ;
VAL_TABLE_ CtaAlrt2_D_Stat 7 "NotUsed3" 6 "NotUsed2" 5 "NotUsed1" 4 "AlertZone4" 3 "AlertZone3" 2 "AlertZone2" 1 "AlertZone1" 0 "Off" ;
VAL_TABLE_ BttRightLeft_D_Stat 7 "NotUsed" 6 "Disabled" 5 "Off" 4 "OffTemp" 3 "NotConnected" 2 "Pending" 1 "Connected" 0 "NotDetermined" ;
VAL_TABLE_ Null_NoRequest_Request 3 "NotUsed" 2 "Request" 1 "NoRequest" 0 "Null" ;
VAL_TABLE_ PoliceIdlMde_D_Stat 15 "NotUsed_7" 14 "NotUsed_6" 13 "NotUsed_5" 12 "NotUsed_4" 11 "NotUsed_3" 10 "NotUsed_2" 9 "PepsActive" 8 "Decommissioned" 7 "ActiveFault" 6 "ArmFault" 5 "PrearmedFault" 4 "OffFault" 3 "Active" 2 "Arm" 1 "Prearmed" 0 "Off" ;
VAL_TABLE_ TripComputerMetricImperial 0 "TripComputer_metric" 1 "TripComputer_imperial" ;
VAL_TABLE_ GrdAsstAllw_D_DsplyPt 3 "NotUsed" 2 "On" 1 "Off" 0 "NoModeSelected" ;
VAL_TABLE_ PrkBrkMsgTxt_D_Rq 15 "Message15" 14 "Message14" 13 "Message13" 12 "Message12" 11 "Message11" 10 "Message10" 9 "Message9" 8 "Message8" 7 "Message7" 6 "Message6" 5 "Message5" 4 "Message4" 3 "Message3" 2 "Message2" 1 "Message1" 0 "No_Message" ;
VAL_TABLE_ AutoHoldMsgTxt_D_Rq 15 "Message15" 14 "Message14" 13 "Message13" 12 "Message12" 11 "Message11" 10 "Message10" 9 "Message9" 8 "Message8" 7 "Message7" 6 "Message6" 5 "Message5" 4 "Message4" 3 "Message3" 2 "Message2" 1 "Message1" 0 "NoMessage" ;
VAL_TABLE_ AutoHoldMde_D_Ind 3 "Indication_3" 2 "Indication_2" 1 "Indication_1" 0 "Off" ;
VAL_TABLE_ AutoRgenTxt_B_RqDsply 1 "AutExhFilterCleanOFF" 0 "AutExhFilterCleanON" ;
VAL_TABLE_ TrnMsgTxt2_D_Rq 7 "NotUsed3" 6 "NotUsed2" 5 "NotUsed1" 4 "TransTooHot_LoudChime" 3 "PressBrake_LoudChime" 2 "PressBrake_SoftChime" 1 "PressBrake_NoChime" 0 "NoText_NoChime" ;
VAL_TABLE_ TrnGearMsgTxt_D_Rq 15 "Message_15" 14 "Message_14" 13 "Message_13" 12 "Message_12" 11 "Message_11" 10 "Message_10" 9 "Message_9" 8 "Message_8" 7 "Message_7" 6 "Message_6" 5 "Message_5" 4 "Message_4" 3 "Message_3" 2 "Message_2" 1 "Message_1" 0 "NoMessage" ;
VAL_TABLE_ ChargeProfIDPref_Rq 3 "NotUsed" 2 "Value" 1 "ChargeNow" 0 "Inactive" ;
VAL_TABLE_ EngExhMdeQuiet_D_Stat 3 "Faulty" 2 "QuietExhaust" 1 "LoudExhaust" 0 "Null" ;
VAL_TABLE_ ConsAvgTrip_No_Dsply 4095 "Faulty" 4094 "No_Data_Exists" ;
VAL_TABLE_ ElTrip_L_Dsply 65535 "Fault" 65534 "No_Data_Exists" ;
VAL_TABLE_ ElLongTerm_L_Dsply 16777215 "Fault" 16777214 "No_Data_Exists" ;
VAL_TABLE_ GearSelLck_D_Rq 3 "PreventionBlocker" 2 "Unlock" 1 "Lock" 0 "Null" ;
VAL_TABLE_ BrkPadMsgTxt_D_Rq 3 "Faulty" 2 "PadsOk" 1 "ReplacePads" 0 "Null" ;
VAL_TABLE_ BrkAutoHold_D_Stat 7 "Faulty" 6 "NotUsed" 5 "Releasing" 4 "HeldSecondary" 3 "HeldSecure" 2 "Held" 1 "Inactive" 0 "Off" ;
VAL_TABLE_ SuspDrvMde_D_Rq 7 "Faulty" 6 "NotUsed2" 5 "NotUsed1" 4 "Drag" 3 "Track" 2 "Snow_Wet" 1 "Sport" 0 "Normal" ;
VAL_TABLE_ NotPressed_PressedNotUsed 3 "NotUsed2" 2 "NotUsed1" 1 "Pressed" 0 "Not_Pressed" ;
VAL_TABLE_ WhlRearDual_D_Stat 3 "NotUsed" 2 "Dual" 1 "Single" 0 "NoDataExists" ;
VAL_TABLE_ TracKeyMde_D_Stat 3 "NotUsed" 2 "NotActive" 1 "Active" 0 "ModeNotDetermined" ;
VAL_TABLE_ HudMde_D_Stat 7 "NotUsed3" 6 "NotUsed2" 5 "NotUsed1" 4 "Manual" 3 "Drag" 2 "RoadCourse" 1 "Tach" 0 "Off" ;
VAL_TABLE_ TrnManShifGear_D_IndDrv 7 "Indicate_Reverse_Gear" 6 "Indicate_Gear6" 5 "Indicate_Gear5" 4 "Indicate_Gear4" 3 "Indicate_Gear3" 2 "Indicate_Gear2" 1 "Indicate_Gear1" 0 "No_Indication" ;
VAL_TABLE_ TrnStrtStop_D_Stat 3 "NotUsed_2" 2 "NotUsed_1" 1 "LowTransmissionTemperature" 0 "NoDriverIndicationRequired" ;
VAL_TABLE_ LsmcBrkDecel_D_Stat 7 "NotUsed_3" 6 "NotUsed_2" 5 "NotUsed_1" 4 "Denied" 3 "FaultDegraded" 2 "FaultExt" 1 "On" 0 "Off" ;
VAL_TABLE_ StePinOffst_D_Stat 3 "FineOffset" 2 "CoarseOffset" 1 "StoredOffset" 0 "OffsetNotCalculated" ;
VAL_TABLE_ NoMessage_Override_Faulty 3 "NotUsed" 2 "Faulty" 1 "Override" 0 "NoMessage" ;
VAL_TABLE_ TrnIpcDsplyRng2_D_Actl 15 "No_Range_Selected" 14 "Range_14" 13 "Range_13" 12 "Range_12" 11 "Range_11" 10 "Range_10" 9 "Range_9" 8 "Range_8" 7 "Range_7" 6 "Range_6" 5 "Range_5" 4 "Range_4" 3 "Range_3" 2 "Range_2" 1 "Range_1" 0 "NotUsed" ;
VAL_TABLE_ OffOn_RampUpDown 3 "Ramp_Down" 2 "Ramp_Up" 1 "On" 0 "Off" ;
VAL_TABLE_ DieslMsgTxt_D_Rq 3 "NotUsed2" 2 "NotUsed1" 1 "ReducedEnginePower" 0 "NoMessage" ;
VAL_TABLE_ NoMessage_Msg1_7 7 "Message7" 6 "Message6" 5 "Message5" 4 "Message4" 3 "Message3" 2 "Message2" 1 "Message1" 0 "NoMessage" ;
VAL_TABLE_ TrnAltShifMde_D_Rdy 3 "Faulty" 2 "NotUsed" 1 "UnavailDueToDynCond" 0 "ModeChangeAvailable" ;
VAL_TABLE_ LnchCtl 3 "NotUsed2" 2 "NotUsed1" 1 "LC_On" 0 "LC_Off" ;
VAL_TABLE_ BrkLineLck_D_Rq 3 "Off" 2 "Engage" 1 "Initiate" 0 "NoRequest" ;
VAL_TABLE_ BrkLineLck_D_Stat 7 "NotUsed_3" 6 "NotUsed_2" 5 "NotUsed_1" 4 "NotAvailable" 3 "Off" 2 "Engaged" 1 "Initiated" 0 "Available" ;
VAL_TABLE_ LnchCtlSys_D_Stat 7 "NotUsed3" 6 "NotUsed2" 5 "NotUsed1" 4 "On_LC_Unavailable_TC_On" 3 "On_LC_Unavailable" 2 "On_LC_Available" 1 "On_LC_Active" 0 "LC_OFF" ;
VAL_TABLE_ ActvFrontSteLck_D_Stat 3 "Test_passed" 2 "Test_failed" 1 "Test_cannot_run" 0 "Test_incomplete" ;
VAL_TABLE_ Rght_Lefthand_Traffic 1 "Left_Hand_Traffic" 0 "Right_Hand_Traffic" ;
VAL_TABLE_ NotPressed_Pressed_Faulty 3 "Faulty" 2 "NotUsed" 1 "Pressed" 0 "Not_Pressed" ;
VAL_TABLE_ TrlrTrgtAcquire_D_Rq 7 "NotUsed_2" 6 "NotUsed_1" 5 "ActivateRVCforTBA" 4 "CancelAcquisition" 3 "RetryAcquisition" 2 "AcquisitionSuccessful" 1 "StartAcquisition" 0 "Inactive" ;
VAL_TABLE_ TrlrTrgtAcquire_D_Stat 7 "Faulty" 6 "NotUsed_2" 5 "NotUsed_1" 4 "RVCforTBA_Activated" 3 "Processing" 2 "TargetNotAcquired" 1 "TargetAcquired" 0 "Null" ;
VAL_TABLE_ TrlrAidSetup_D_Rq 3 "ConfirmSetup" 2 "EndSetup" 1 "BeginSetup" 0 "Inactive" ;
VAL_TABLE_ TrlBrkInitOut 3 "Heavy" 2 "Medium" 1 "Light" 0 "Null" ;
VAL_TABLE_ IsaOffst_D_Stat 15 "Faulty" 14 "Null" 13 "Thirteen" 12 "Twelve" 11 "Eleven" 10 "Ten" 9 "Nine" 8 "Eight" 7 "Seven" 6 "Six" 5 "Five" 4 "Four" 3 "Three" 2 "Two" 1 "One" 0 "Zero" ;
VAL_TABLE_ IsaVLimUnit_D_Rq 3 "NoDataExists" 2 "Mph" 1 "Kph" 0 "Null" ;
VAL_TABLE_ ApaChime_D_Rq 7 "NotUsed2" 6 "NotUsed1" 5 "Warning_Chime" 4 "Finish_Chime" 3 "Stop_Now_Chime" 2 "Spot_Ready_Chime" 1 "Spot_Found_Chime" 0 "No_Chime" ;
VAL_TABLE_ SlMde_D_RqDsply 3 "NotUsed" 2 "ManualSpeed_LimiterSymbol" 1 "AutoSpeed_LimiterSymbol" 0 "NoSpeed_LimiterSymbol" ;
VAL_TABLE_ SlMde_D_Rq 3 "IsaNotConfigured" 2 "Manual_Mode" 1 "Auto_Mode" 0 "Null" ;
VAL_TABLE_ NotSupported_Supported 1 "Supported" 0 "NotSupported" ;
VAL_TABLE_ OffOn_NotUsed_NoData 3 "No_Data_Present" 2 "NotUsed" 1 "On" 0 "Off" ;
VAL_TABLE_ Faulty_FF 255 "Faulty" ;
VAL_TABLE_ BrkDrvMde_D_Rq 7 "Faulty" 6 "RockCrawl" 5 "Baja" 4 "DragOrMudAndSand" 3 "Track" 2 "Snow_Wet" 1 "Sport" 0 "Normal" ;
VAL_TABLE_ TrnIpcDsplyRng_D_Stat 3 "NotUsed" 2 "Flash" 1 "On" 0 "Blank_No_Display" ;
VAL_TABLE_ NoYesNoDataFaulty 3 "Faulty" 2 "NoDataExists" 1 "Yes" 0 "No" ;
VAL_TABLE_ SidePrkSnsR4_D_Stat 15 "NotUsed" 14 "NotFullyScannedYet" 13 "NoObjectInSector" 12 "Zone12" 11 "Zone11" 10 "Zone10" 9 "Zone9" 8 "Zone8" 7 "Zone7" 6 "Zone6" 5 "Zone5" 4 "Zone4" 3 "Zone3" 2 "Zone2" 1 "Zone1" 0 "Off" ;
VAL_TABLE_ TsrVlPrmntMsgTxt_D_Rq 3 "NotUsed" 2 "ShowPermanentlyWithSupp" 1 "ShowPermanentlyWithoutSupp" 0 "DoNotShowSignPermanent" ;
VAL_TABLE_ TsrVl1RstrcMsgTxt2_D_Rq 7 "NotUsed" 6 "Time" 5 "Trailer" 4 "Snow" 3 "RainWet" 2 "NoRecognizableRestrictn" 1 "NoSpeedLimitRestrictn" 0 "Null" ;
VAL_TABLE_ PtDrvMde_D_Rq 15 "Faulty" 14 "NotUsed11" 13 "NotUsed10" 12 "NotUsed9" 11 "NotUsed8" 10 "NotUsed7" 9 "NotUsed6" 8 "NotUsed5" 7 "Drag" 6 "Rock" 5 "Baja" 4 "Sand" 3 "TowHaulGradeAssist" 2 "SnowWet" 1 "Sport" 0 "Normal" ;
VAL_TABLE_ SteEffort_D_Stat 7 "NotUsed_3" 6 "NotUsed_2" 5 "NotUsed_1" 4 "SpecialMode_2" 3 "SpecialMode_1" 2 "Comfort" 1 "Sport" 0 "Normal" ;
VAL_TABLE_ TsrOvtkMsgTxt2_D_Rq 15 "NotUsed5" 14 "NotUsed4" 13 "NotUsed3" 12 "NotUsed2" 11 "NotUsed1" 10 "LimForTrucksCancelled" 9 "LimForTrucksWoQlfdRstrc" 8 "LimForTrucksWithoutRstrc" 7 "LimAllCancelled" 6 "LimAllWithRstrcTime" 5 "LimAllWithRstrcTrailer" 4 "LimAllWithRstrcSnow" 3 "LimAllWithRstrcRain" 2 "LimAllWithoutQlfdRstrc" 1 "LimAllWithoutRestriction" 0 "OvertakingAllowed" ;
VAL_TABLE_ TrlrAnOffstDir 3 "NotUSed" 2 "Right" 1 "Left_or_Center" 0 "Null" ;
VAL_TABLE_ Null_Off_On 3 "NotUsed" 2 "On" 1 "Off" 0 "Null" ;
VAL_TABLE_ TrlrBrkMde_D_Rq 1 "ElectricOverHydraulic" 0 "Electric" ;
VAL_TABLE_ TrlrAidSetup_D_Stat 7 "Faulty" 6 "NotUsed_3" 5 "NotUsed_2" 4 "NotUsed_1" 3 "EnterParameters" 2 "EndSetup" 1 "BeginSetup" 0 "Null" ;
VAL_TABLE_ TrlrAidMsgTxt_D_Rq 31 "Message31" 30 "Message30" 29 "Message29" 28 "Message28" 27 "Message27" 26 "Message26" 25 "Message25" 24 "Message24" 23 "Message23" 22 "Message22" 21 "Message21" 20 "Message20" 19 "Message19" 18 "Message18" 17 "Message17" 16 "Message16" 15 "Message15" 14 "Message14" 13 "Message13" 12 "Message12" 11 "Message11" 10 "Message10" 9 "Message9" 8 "Message8" 7 "Message7" 6 "Message6" 5 "Message5" 4 "Message4" 3 "Message3" 2 "Message2" 1 "Message1" 0 "NoMessage" ;
VAL_TABLE_ Invalid_7F 127 "Invalid" ;
VAL_TABLE_ Faulty_1FFF 8191 "Faulty" ;
VAL_TABLE_ VehStab_D_Stat 15 "Faulty" 14 "No_Data_Exists" 13 "NotUsed6" 12 "NotUsed5" 11 "NotUsed4" 10 "NotUsed3" 9 "NotUsed2" 8 "NotUsed1" 7 "High_SSRA_no_OS" 6 "Straight" 5 "Post_Oversteer" 4 "Post_Transition" 3 "Countersteer" 2 "Understeer" 1 "Oversteer" 0 "Linear" ;
VAL_TABLE_ NoData_Faulty_1FF_1FE 511 "Faulty" 510 "NoDataExists" ;
VAL_TABLE_ TrlrAidEnbl_D_Rq 3 "NotAvailable" 2 "DeactivateTba" 1 "ActivateTba" 0 "Inactive" ;
VAL_TABLE_ FohEng_D_Rq 3 "AutoEnable_ParkEnable" 2 "AutoDisable_ParkEnable" 1 "AutoEnable_ParkDisable" 0 "Disable_Stop" ;
VAL_TABLE_ Null_Hi_NotUsed_Low 3 "Low" 2 "Not_Used" 1 "High" 0 "Null" ;
VAL_TABLE_ Current_Color 15 "NotUsed7" 14 "NotUsed6" 13 "NotUsed5" 12 "NotUsed4" 11 "NotUsed3" 10 "NotUsed2" 9 "NotUsed1" 8 "Null" 7 "Color7" 6 "Color6" 5 "Color5" 4 "Color4" 3 "Color3" 2 "Color2" 1 "Color1" 0 "Off" ;
VAL_TABLE_ Blended_Color 15 "NotUsed10" 14 "NotUsed9" 13 "NotUsed8" 12 "NotUsed7" 11 "NotUsed6" 10 "NotUsed5" 9 "NotUsed4" 8 "NotUsed3" 7 "NotUsed2" 6 "NotUsed1" 5 "_5" 4 "_4" 3 "_3" 2 "_2" 1 "_1" 0 "Null" ;
VAL_TABLE_ OffOn_Null_NotUsed 3 "NotUsed" 2 "Null" 1 "On" 0 "Off" ;
VAL_TABLE_ DieslPrtc2_D_RqDsply 15 "NotUsed4" 14 "NotUsed3" 13 "NotUsed2" 12 "NotUsed1" 11 "OCR_ExhFilterClean_Stopped" 10 "OCR_ExhFilterCleaned" 9 "RgnOff_AtLimit" 8 "RgnOff_Overloaded" 7 "RgnOff_Loaded" 6 "Exhaust_Filter_Full" 5 "DPF_Overlimit" 4 "DPF_AtLimit" 3 "ExhFilter_Drive_Completed" 2 "Cleaning_Exhaust_Filter" 1 "DPF_Overloaded" 0 "DPF_Normal_Operation" ;
VAL_TABLE_ Null_Pers1_4_Vehicle 7 "Unused_2" 6 "Unused_1" 5 "Vehicle" 4 "PERS_4" 3 "PERS_3" 2 "PERS_2" 1 "PERS_1" 0 "Null" ;
VAL_TABLE_ PrkLckCtlEnbl_D_RqIpc 3 "Rq_Towing" 2 "Rq_Enable" 1 "Rq_Disable" 0 "Null" ;
VAL_TABLE_ PrkLckCtlUnlck_D_Stat 3 "Trans_And_Steer_Unlckd" 2 "Steering_Unlckd" 1 "Transmission_Unlckd" 0 "Null" ;
VAL_TABLE_ VehKeyActv_D_Stat 15 "NotUsed7" 14 "NotUsed6" 13 "NotUsed5" 12 "NotUsed4" 11 "NotUsed3" 10 "NotUsed2" 9 "NotUsed1" 8 "Key8Active" 7 "Key7Active" 6 "Key6Active" 5 "Key5Active" 4 "Key4Active" 3 "Key3Active" 2 "Key2Active" 1 "Key1Active" 0 "NoKeyActive" ;
VAL_TABLE_ VehLckInd_D_Rq 3 "NotUsed" 2 "On_Day" 1 "On_Night" 0 "Off" ;
VAL_TABLE_ PrkBrkDynmc_D_Allw 3 "NotUsed" 2 "EPB_ECD_NotPossible" 1 "EPB_ECD_Possible" 0 "Used_at_Start_Up" ;
VAL_TABLE_ TowBarMsgTxt_D_Rq 7 "NotUsed3" 6 "NotUsed2" 5 "NotUsed1" 4 "TowBar_Ext_No_Trlr" 3 "Error_Dealer_Fix" 2 "Start_Engine_Swivel" 1 "Check_Tow_Bar" 0 "Null" ;
VAL_TABLE_ PrkBrk_D_Stat 7 "Gen_Faults_or_Maint_Mode" 6 "ECD_by_Brake_ECU_Active" 5 "EPB_Limphome_Active" 4 "Rear_Caliper_Open" 3 "RWU_by_EPB_Active" 2 "Rear_Caliper_Transition" 1 "Rear_Caliper_Closed" 0 "Not_Supported" ;
VAL_TABLE_ NoData_Faulty_3E_3F 63 "Faulty" 62 "NoDataExists" ;
VAL_TABLE_ Unknown_Invalid_1FE_1FF 511 "Invalid" 510 "Unknown" ;
VAL_TABLE_ Invalid_0x0 0 "Invalid" ;
VAL_TABLE_ Unknown_Invalid_3E_3F 63 "Invalid" 62 "Unknown" ;
VAL_TABLE_ Faulty_1FF 511 "Faulty" ;
VAL_TABLE_ NoData_Faulty_1FFF_1FFE 8191 "Faulty" 8190 "NoDataExists" ;
VAL_TABLE_ Null_Off_On_Faulty 3 "Faulty" 2 "On" 1 "Off" 0 "Null" ;
VAL_TABLE_ EngOilSrvcMsgTxt_D_Rq 7 "NotUsed3" 6 "NotUsed2" 5 "NotUsed1" 4 "ResetComplete" 3 "ResetInProgress" 2 "ChangeOilNow" 1 "ChangeOilSoon" 0 "NoText" ;
VAL_TABLE_ AirSusp_D_RqDrv 3 "NotUsed" 2 "On" 1 "Off" 0 "NoModeSelected" ;
VAL_TABLE_ AwdSys_D_Stat 3 "Faulty" 2 "NotUsed" 1 "_4x4_L_H_Active" 0 "_4x4_L_H_Inactive" ;
VAL_TABLE_ EmotiveType_D_Dsply 3 "EmotiveDisplay_3" 2 "EmotiveDisplay_2" 1 "EmotiveDisplay_1" 0 "Null" ;
VAL_TABLE_ AutoRgen_D_Rq 3 "NotUsed" 2 "AutExhFilterCleanOFF" 1 "AutExhFilterCleanON" 0 "No_Mode_Selected" ;
VAL_TABLE_ TrnSrvcRqd_B_Rq 1 "On" 0 "Off" ;
VAL_TABLE_ PlgOvrrdStrt_D_Cmd 3 "NotUsed" 2 "Override_Plug_Status" 1 "Dont_Override_Plug_Status" 0 "Null_State" ;
VAL_TABLE_ immoSecureIdleMode 3 "NotUsed2" 2 "NotUsed1" 1 "Active" 0 "Inactive" ;
VAL_TABLE_ SteWhlOffstRq_D_Stat 3 "Faulty" 2 "NoDataExists" 1 "Allow_External_Angle_Req" 0 "Deny_External_Angle_Req" ;
VAL_TABLE_ SteMdule_D_Stat 7 "NotUsed" 6 "EPAS_Failure3" 5 "EPAS_Failure2" 4 "System_Failure" 3 "EPAS_Shutdown" 2 "Normal_Op_Full_Assist" 1 "Normal_Op_Limited_Assist" 0 "EPAS_Initialization" ;
VAL_TABLE_ Faulty_FFF 4095 "Faulty" ;
VAL_TABLE_ Faulty_3FF 1023 "Faulty" ;
VAL_TABLE_ NoData_Faulty_FE_FF 255 "Faulty" 254 "NoDataExists" ;
VAL_TABLE_ ChkPlgtoStrt_D_Dsply 3 "NotUsed" 2 "Is_VehicleUnplugged_Prompt" 1 "Check_Plug_to_Start" 0 "No_Message_Display" ;
VAL_TABLE_ PwrFlowTxt_D_Dsply 15 "NotUsed7" 14 "NotUsed6" 13 "NotUsed5" 12 "NotUsed4" 11 "Disply_Rgen_Chrg_Txt" 10 "Disp_Fast_Charge_Txt" 9 "Disp_Fast_Charge_Cmplt_Txt" 8 "Disp_Charge_Cmplt_Txt" 7 "Disp_Remote_Start_Txt" 6 "Disp_Eng_Drv_Txt" 5 "Disp_Elec_Drv_Txt" 4 "Disp_Idle_with_Chrg_Txt" 3 "Disp_Idle_Txt" 2 "Disp_Charg_HV_Batt_Txt" 1 "Disp_Hyb_Drive_Txt" 0 "No_Text" ;
VAL_TABLE_ EngOnMsg_D_Dsply 14 "_0xE_to_1F_NotUsed" 12 "Battery_Temperature" 11 "Hill_Decent_Control" 10 "Fuel_Maintenance" 9 "Oil_Maintenance" 8 "Normal_Operation" 7 "Low_Gear" 6 "Batt_Charging" 5 "Engine_Cold" 4 "Neutral_Gear" 3 "Heater_Setting" 2 "High_Speed" 1 "Acceleration" 0 "No_Display" 13 "Drive_Mode_Selection" ;
VAL_TABLE_ PtDataKeyId_D_Stat 15 "NotUsed5" 14 "NotUsed4" 13 "NotUsed3" 12 "NotUsed2" 11 "NotUsed1" 10 "Tot_Veh_NUT" 9 "Cust_4_NUT" 8 "Cust_3_NUT" 7 "Cust_2_NUT" 6 "Cust_1_NUT" 5 "Tot_Veh_Stat" 4 "Cust_4_Stat" 3 "Cust_3_Stat" 2 "Cust_2_Stat" 1 "Cust_1_Stat" 0 "Null" ;
VAL_TABLE_ ChrgStat_D_Dsply 7 "NotUsed" 6 "Complete" 5 "Scheduled" 4 "In_Progress" 3 "Fault_Outside_Car" 2 "Fault_Inside_Car" 1 "Fault_Unknown_Location" 0 "Not_Ready" ;
VAL_TABLE_ TrnLvrV_D_Rq 3 "Full_Speed" 2 "Aggressive" 1 "Normal" 0 "Quiet" ;
VAL_TABLE_ EngStrtStop_B_SrcOil 1 "Eng_start_stop_for_oilmnt" 0 "Not_Requested" ;
VAL_TABLE_ FuelMaintMde_D_Rq 3 "Feature_Not_Present" 2 "Fuel_Maint_Req_Now" 1 "Fuel_Maint_Req_Soon" 0 "NoRequest" ;
VAL_TABLE_ FuelMaintMde_D_Dsply 3 "Feature_Not_Present" 2 "In_Fuel_Maint_Mode" 1 "Close_to_Fuel_Maint" 0 "OK" ;
VAL_TABLE_ DynoMde_B_Cmd 1 "Two_Wheel_Dyno" 0 "Normal_Operation" ;
VAL_TABLE_ HvacPrecondRecirc_D_Rq 3 "Last_User_Setting" 2 "Auto" 1 "Recirc" 0 "Outside" ;
VAL_TABLE_ HvacPrecondAC_D_Rq 3 "Last_User_Setting" 2 "Auto" 1 "On" 0 "Off" ;
VAL_TABLE_ HybMdeStat_D_Dsply 7 "NotUsed2" 6 "EV_Charge" 5 "EV_Override" 4 "Forced_EV_Mode" 3 "Forced_Charge_Sustain_Mode" 2 "Auto_Charge_Sustain_Mode" 1 "Auto_Charge_Deplete_Mode" 0 "Null_State" ;
VAL_TABLE_ PwFlowPlgBatt_D_Dsply 3 "NotUsed" 2 "Flow_from_Plug_to_Batt" 1 "Flow_from_Batt_to_Plug" 0 "No_Flow" ;
VAL_TABLE_ PwFlowEngMtr_D_Dsply 3 "NotUsed" 2 "Flow_from_Eng_to_Mtr" 1 "Flow_from_Mtr_to_Eng" 0 "No_Flow" ;
VAL_TABLE_ PwFlowEngFuel_D_Dsply 3 "NotUsed" 2 "Flow_from_Eng_to_Fuel" 1 "Flow_from_Fuel_to_Eng" 0 "No_Flow" ;
VAL_TABLE_ PwFlowMtrDrv_D_Dsply 3 "NotUsed" 2 "Flow_from_Mtr_to_Axle" 1 "Flow_from_Axle_to_Mtr" 0 "No_FLow" ;
VAL_TABLE_ PwFlowEngDrv_D_Dsply 3 "NotUsed" 2 "Flow_from_Eng_to_Axle" 1 "Flow_from_Axle_to_Eng" 0 "No_Flow" ;
VAL_TABLE_ PwFlowBattMtr_D_Dsply 3 "NotUsed" 2 "Flow_from_Batt_to_Mtr" 1 "Flow_from_Mtr_to_Batt" 0 "No_Flow" ;
VAL_TABLE_ Null_Override_Invalid 3 "NotUsed" 2 "Invalid" 1 "Override" 0 "Null" ;
VAL_TABLE_ HybMdeMsgTxt_D_Rq 7 "NotUsed2" 6 "NotUsed1" 5 "EV_Not_Avail_Message" 4 "EV_Mode_Message" 3 "Delayed_Discharge_Message" 2 "Override_Available_Message" 1 "AutoMode_Message" 0 "Null_NoMessage_Request" ;
VAL_TABLE_ HybMdeLimMsgTxt_D_Rq 3 "Limited_Req_Full_Defrost" 2 "Limited_Climate_Defrost" 1 "Limited_System_Performance" 0 "Null" ;
VAL_TABLE_ CenterStackRing_D_Actl 3 "LimitedOn" 2 "On" 1 "Off" 0 "Null" ;
VAL_TABLE_ NoData_Faulty_FFFE_FFFF 65535 "Faulty" 65534 "NoDataExists" ;
VAL_TABLE_ NoData_Faulty_FFE_FFF 4095 "Faulty" 4094 "NoDataExists" ;
VAL_TABLE_ NoData_Faulty_7FFE_7FFF 32767 "Faulty" 32766 "NoDataExists" ;
VAL_TABLE_ NoData_Faulty_3FE_3FF 1023 "Faulty" 1022 "NoDataExists" ;
VAL_TABLE_ ReFuelSysStat_D_Dsply 7 "NotUsed3" 6 "NotUsed2" 5 "NotUsed1" 4 "Refuel_Err" 3 "Close_Fuel_Door" 2 "Refuel_Ready" 1 "Wait_To_Fuel" 0 "Null" ;
VAL_TABLE_ OffOn_NotUsed 3 "NotUsed2" 2 "NotUsed1" 1 "On" 0 "Off" ;
VAL_TABLE_ DrQltyDrv_D_StatGsm 7 "Faulty" 6 "NoDataExists" 5 "NotUsed2" 4 "NotUsed1" 3 "ClosedDegraded" 2 "OpenDegraded" 1 "ClosedOkay" 0 "OpenOkay" ;
VAL_TABLE_ ChrgrInPwType_D_Actl 6 "NotUsed3" 5 "NotUsed2" 4 "NotUsed1" 3 "DC_Fast_Charging" 2 "AC_Level2_240v" 1 "AC_Level1_120v" 0 "EVSE_Not_Detected" ;
VAL_TABLE_ ChrgCrdLck_D_Falt 3 "NotUsed" 2 "HardwareFault" 1 "CsiFault" 0 "NoFault" ;
VAL_TABLE_ ChrgStat_D2_Dsply 15 "NotUsed_2" 14 "NotUsed_1" 13 "ChargeTargetReached" 12 "DriveConditioning" 11 "CabinPreconditioning" 10 "ChargingSystemMaintain" 9 "ChargingInductive" 8 "ChargingDCFastChange" 7 "ChargingAC" 6 "ChargeScheduled" 5 "EvsePaused" 4 "EvseNotDetected" 3 "EvseNotCompatible" 2 "FaultOutsideCar" 1 "FaultInsideCar" 0 "NotReady" ;
VAL_TABLE_ EngMdeMsgTxt_D_Rq 7 "NotUsed_3" 6 "NotUsed_2" 5 "NotUsed_1" 4 "Charge" 3 "GlowingCharge" 2 "Hybrid" 1 "Ev" 0 "NoMessage" ;
VAL_TABLE_ BattRgenLoStat_D_Qlty 3 "OK" 2 "Not_Within_Spec" 1 "Eval_In_Progress" 0 "Faulty" ;
VAL_TABLE_ OpenClosedRetainDisable 3 "Disable" 2 "Retain" 1 "Closed" 0 "Open" ;
VAL_TABLE_ OpenClosedStuckOpenClosed 3 "StuckClosed" 2 "StuckOpen" 1 "Closed" 0 "Open" ;
VAL_TABLE_ NoData_Faulty_7FE_7FF 2047 "Faulty" 2046 "NoDataExists" ;
VAL_TABLE_ DrTgateChime2_D_Rq 7 "NotUsed3" 6 "NotUsed2" 5 "NotUsed1" 4 "Long_Repeated" 3 "Fast" 2 "Short" 1 "Long" 0 "Off" ;
VAL_TABLE_ EngIdlShutDwnTxt_D_Rq 3 "NotUsed" 2 "EngineShutdownOnPrevDrive" 1 "FeatureDisabledDueToFault" 0 "NoMessage" ;
VAL_TABLE_ DrvPerfMde 3 "Sport" 2 "Normal" 1 "NotUsed" 0 "NoModeSelected" ;
VAL_TABLE_ NoData_Fault_1FF_1FE 511 "Fault" 510 "NoDataExists" ;
VAL_TABLE_ NoData_Fault_FFE_FFF 4095 "Fault" 4094 "NoDataExists" ;
VAL_TABLE_ WeekdayEndHR_St 31 "Invalid" 30 "Unknown" 29 "Reserved_29" 28 "Reserved_28" 27 "Reserved_27" 26 "Reserved_26" 25 "Reserved_25" 24 "Reserved_24" ;
VAL_TABLE_ WeekdayEndMin_St 63 "Faulty" 62 "No_data_exists" 61 "Reserverd" 60 "Reserverd" ;
VAL_TABLE_ WeekdayStartHR_St 31 "Invalid" 30 "Unknown" 29 "Reserved_29" 28 "Reserved_28" 27 "Reserved_27" 26 "Reserved_26" 25 "Reserved_25" 24 "Reserved_24" ;
VAL_TABLE_ WeekdayStartMin_St 63 "Faulty" 62 "No_data_exists" 61 "Reserverd" 60 "Reserverd" ;
VAL_TABLE_ EngIdlShutDown_D_Stat 3 "Not_used" 2 "Engine_Shutdown" 1 "Initiated_Countdown" 0 "Normal_Operation" ;
VAL_TABLE_ StopStrtDrvMde_D_Indic 3 "NotUsed" 2 "StartStop_IndirectDeselect" 1 "StopStart_Deselected" 0 "StopStart_Selected" ;
VAL_TABLE_ StopStrtDrvMde_D_RqMnu 3 "NotUsed2" 2 "NotUsed1" 1 "StopStart_Deselected" 0 "StopStart_Selected" ;
VAL_TABLE_ StopStrtStdby_D_Indic 6 "NotUsed2" 5 "Telltale_Struck_Out" 4 "Telltale_Flashing_Amber" 3 "Telltale_On_Amber" 2 "Telltale_Flashing_Green" 1 "Telltale_On_Green" 0 "Telltale_Off" 7 "NotUsed3" ;
VAL_TABLE_ Quality_Faulty 3 "OK" 2 "Degraded" 1 "No_Data_Exists" 0 "Faulty" ;
VAL_TABLE_ TrnDtpCmd_D_Actl 7 "NotUsed4" 6 "NotUsed3" 5 "NotUsed2" 4 "Relatch" 3 "Deploy" 2 "Self_Test" 1 "No_Command" 0 "NotUsed1" ;
VAL_TABLE_ TrnGsmNtmState_D_Actl 3 "Faulty" 2 "Neutral_Tow_Mode" 1 "Car_Wash_Mode" 0 "None" ;
VAL_TABLE_ TrnTrcmPwmSig_D_Actl 15 "Faulty" 14 "NoDataExists" 13 "NotUsed5" 12 "NotUsed4" 11 "NotUsed3" 10 "NotUsed2" 9 "NotUsed1" 8 "Default_To_Park" 7 "Neutral_Tow" 6 "Car_Wash_Mode" 5 "Manual" 4 "Drive" 3 "Neutral" 2 "Reverse" 1 "Park" 0 "No_Gear" ;
VAL_TABLE_ RgenBrkDynoMde_B_Actl 1 "TwoWheelDyno" 0 "NormalOperation" ;
VAL_TABLE_ Fault_3FFF 16383 "Fault" ;
VAL_TABLE_ CtaInnr_D_Stat 3 "Reporting" 2 "Not_Reporting" 1 "System_Standby" 0 "Initialization" ;
VAL_TABLE_ PrkBrkActv_D_RqTrnGear 3 "NotUsed2" 2 "RequestParkBrakeEngage" 1 "NoRequest" 0 "NotUsed1" ;
VAL_TABLE_ NoRequest_Request 1 "Request" 0 "NoRequest" ;
VAL_TABLE_ Fault_FFF_NoData 4094 "NoDataExists" 4095 "Fault" ;
VAL_TABLE_ Fault_3FF_NoData 1022 "NoDataExists" 1023 "Fault" ;
VAL_TABLE_ Foh_D_Stat 7 "Unused3" 6 "Unused2" 5 "Unused1" 4 "Stopping" 3 "Running" 2 "Starting" 1 "Prestart" 0 "Off" ;
VAL_TABLE_ OffOnNoDataUnused 3 "Unused" 2 "NoDataExists" 1 "On" 0 "Off" ;
VAL_TABLE_ FohFalt_D_Stat 15 "NotUsed4" 14 "NotUsed3" 13 "NotUsed2" 12 "NotUsed1" 11 "FuelTypeDoesNotMatchFOH" 10 "Lifecycle_ModeNotSet" 9 "AuxElectricCoolantPumpInop" 8 "TimeDelayAvoidExcessCycl" 7 "Fuel_Level_OutofRange" 6 "External_Fault" 5 "Internal_Fault" 4 "Voltage_limitation" 3 "Impact_Event" 2 "CoolantTemp_OutofRange" 1 "AmbientTemp_OutofRange" 0 "No_Disable" ;
VAL_TABLE_ FohRqRun_B_Rq 1 "SubmitRequest_toRun" 0 "DoesNotSubmitRequest_toRun" ;
VAL_TABLE_ OKLowVeryLow 3 "NotUsed" 2 "VeryLow" 1 "Low" 0 "OK" ;
VAL_TABLE_ Fault_1FF 511 "Fault" ;
VAL_TABLE_ SteWhlHeat 15 "NotUsed6" 14 "NotUsed5" 13 "NotUsed4" 12 "NotUsed3" 11 "NotUsed2" 10 "NotUsed1" 9 "Reserved_3" 8 "Reserved_2" 7 "Reserved_1" 6 "Level_3_Heating" 5 "Level_3_Heating_LS" 4 "Level_2_Heating" 3 "Level_2_Heating_LS" 2 "Level_1_Heating" 1 "Level_1_Heating_LS" 0 "Off" ;
VAL_TABLE_ OffOnUnusedFault 3 "Fault" 2 "Unused" 1 "On" 0 "Off" ;
VAL_TABLE_ NullKphMph 3 "NoDataExists" 2 "Mph" 1 "Kph" 0 "Null" ;
VAL_TABLE_ TsrVLim1MsgTxt_D_Rq 255 "NoLimit" 254 "NotUsed2" 253 "NotUsed1" 252 "NotToBeDisplayed" 251 "LimitCancelled" 31 "1F_FA_Message31_250" 30 "Message30" 29 "Message29" 28 "Message28" 27 "Message27" 26 "Message26" 25 "Message25" 24 "Message24" 23 "Message23" 22 "Message22" 21 "Message21" 20 "Message20" 19 "Message19" 18 "Message18" 17 "Message17" 16 "Message16" 15 "Message15" 14 "Message14" 13 "Message13" 12 "Message12" 11 "Message11" 10 "Message10" 9 "Message9" 8 "Message8" 7 "Message7" 6 "Message6" 5 "Message5" 4 "Message4" 3 "Message3" 2 "Message2" 1 "Message1" 0 "Null" ;
VAL_TABLE_ TsrVl1RstrcMsgTxt_D_Rq 3 "NotUsed" 2 "NoRecognizableRestriction" 1 "NoSpeedLimitRestriction" 0 "Null" ;
VAL_TABLE_ TsrMsgTxt_D_Rq 15 "NotUsed6" 14 "NotUsed5" 13 "NotUsed4" 12 "NotUsed3" 11 "NotUsed2" 10 "NotUsed1" 9 "RecgnzdSignNotUsblForDsply" 8 "LimitedSystemPerformance" 7 "OffRoad" 6 "RegionNotSupported" 5 "CountryNotSupported" 4 "WrngNavDatIncompDatCarrier" 3 "NoNavDataAvailable" 2 "NoNavAvailableSwitchedOff" 1 "NoInformationAllOK" 0 "Null" ;
VAL_TABLE_ TsrOvtkTypeMsgTxt_D_Rq 3 "NotUsed" 2 "Explicit" 1 "Implicit" 0 "Null" ;
VAL_TABLE_ TsrOvtkStatMsgTxt_D_Rq 3 "LimitOutdated" 2 "LimitReiable" 1 "LimitChanged" 0 "Null" ;
VAL_TABLE_ TsrOvtkMsgTxt_D_Rq 7 "LimForTrucksCancelled" 6 "LimForTrucksWoQlfdRstrc" 5 "LimForTrucksWithoutRstrc" 4 "LimAllCancelled" 3 "LimAllWithoutQlfdRstrc" 2 "LimAllWithoutRestriction" 1 "OvertakingAllowed" 0 "Null" ;
VAL_TABLE_ Null_False_True 3 "NotUsed" 2 "True" 1 "False" 0 "Null" ;
VAL_TABLE_ TsrStatMsgTxt_D_Rq 7 "NotUsed" 6 "NoDataExists" 5 "TSR_Error" 4 "Available_NavigationOnly" 3 "Available_CameraOnly" 2 "Available_FusionMode" 1 "TSR_Off" 0 "Null" ;
VAL_TABLE_ NoMessage_DisplayMessage 1 "DisplayMessage" 0 "NoMessage" ;
VAL_TABLE_ FdsmTrgRight 1 "Object_in_Right_Lobe" 0 "No_Object" ;
VAL_TABLE_ FdsmTrgCntr 1 "Object_in_Center_Lobe" 0 "No_Object" ;
VAL_TABLE_ FdsmTrgLeft 1 "Object_in_Left_Lobe" 0 "No_Object" ;
VAL_TABLE_ EngineBrakeOff_Active 1 "Engine_Braking_Activated" 0 "Engine_Braking_Off" ;
VAL_TABLE_ NoEngineBrake_Brake 1 "Engine_Braking" 0 "No_Engine_Braking" ;
VAL_TABLE_ PlgActv_D_ActlChrgr 3 "Faulty" 2 "Not used_2" 1 "On_Plug__Connected_" 0 "Off_Plug__Disconnected_" ;
VAL_TABLE_ EngSrvcRqd_B_Rq 1 "Engine_Service_Required" 0 "No_engine_service_required" ;
VAL_TABLE_ WeekendEndHR_St 31 "Invalid" 30 "Unknown" 29 "Reserved_29" 28 "Reserved_28" 27 "Reserved_27" 26 "Reserved_26" 25 "Reserved_25" 24 "Reserved_24" ;
VAL_TABLE_ WeekendEndMin_St 63 "Faulty" 62 "No_data_exists" 61 "Reserverd" 60 "Reserverd" ;
VAL_TABLE_ WeekendStartHR_St 31 "Invalid" 30 "Unknown" 29 "Reserved_29" 28 "Reserved_28" 27 "Reserved_27" 26 "Reserved_26" 25 "Reserved_25" 24 "Reserved_24" ;
VAL_TABLE_ WeekendStartMin_St 63 "Faulty" 62 "No_data_exists" 61 "Reserverd" 60 "Reserverd" ;
VAL_TABLE_ LscmbbBaSens_D_Rq 3 "Level3_EBA" 2 "Level2_EBA" 1 "Level1_EBA" 0 "Norman_EBA" ;
VAL_TABLE_ Allowed_Denied 1 "Denied" 0 "Allowed" ;
VAL_TABLE_ LscmbbBrkPrchg_D_Rq 3 "NotUsed" 2 "Level2_PreCharge" 1 "Level1_PreCharge" 0 "No_Precharge" ;
VAL_TABLE_ LscmbbBrkDecel_B_Enabl 1 "ConductLSCMbBDecelReq" 0 "DoNotConductLSCMbBDecelReq" ;
VAL_TABLE_ PrkAidMsgTxt_D_Rq 15 "All_Sns_Blk" 14 "R_Sns_ON_F_Sns_Blk" 13 "R_Sns_Blk_F_Sns_ON" 12 "R_Sns_Inactive_Trlr_atch" 11 "Not_Avail_Trlr_attchd" 10 "Fail_Mode_no_Chime" 9 "Fail_Mode_with_Chime" 8 "R_Sns_Trlr_F_Sns_Blk" 7 "NotUsed3" 6 "Park_Sys_Alternate_Mode" 5 "R_Snsrs_On_F_Snsrs_On" 4 "NotUsed2" 3 "Reset_Message_Warn" 2 "R_Snsrs_Off_F_Snsrs_On" 1 "R_Snsrs_On_F_Snsrs_Off" 0 "All_Park_Sensors_Off" ;
VAL_TABLE_ PrkAidSns_D_Stat 15 "Zone_15" 14 "Zone_14" 13 "Zone_13" 12 "Zone_12" 11 "Zone_11" 10 "Zone_10" 9 "Zone_9" 8 "Zone_8" 7 "Zone_7" 6 "Zone_6" 5 "Zone_5" 4 "Zone_4" 3 "Zone_3" 2 "Zone_2" 1 "Zone_1" 0 "Off" ;
VAL_TABLE_ PrkAid_D_Falt 7 "NotUsed2" 6 "NotUsed1" 5 "Failure_Front_PSM_Sensors" 4 "No_Data_Exists" 3 "Failure_Rear_Sensors" 2 "Speaker_Fault" 1 "ECU_Fault" 0 "No_Fault" ;
VAL_TABLE_ OffOnNoDataFault 3 "Fault" 2 "No_Data_Exists" 1 "On" 0 "Off" ;
VAL_TABLE_ ApaActvSd_D_Actl 3 "Dirver_Side" 2 "Passenger_Side" 1 "No_Side" 0 "Null" ;
VAL_TABLE_ ApaMdeStat_D_RqDrv 7 "Faulty" 6 "Off" 5 "NotUsed2" 4 "NotUsed1" 3 "POA" 2 "PPA" 1 "SAPP" 0 "Inactive" ;
VAL_TABLE_ ApaMde_D_Avail 15 "NotUsed7" 14 "NotUsed6" 13 "NotUsed5" 12 "NotUsed4" 11 "NotUsed3" 10 "NotUsed2" 9 "NotUsed1" 8 "PPA_POA" 7 "SAPP_POA" 6 "POA" 5 "PPA" 4 "SAPP" 3 "SAPP_PPA_POA" 2 "SAPP_PPA" 1 "None" 0 "Null" ;
VAL_TABLE_ ApaMde_D_Stat 7 "NotUsed3" 6 "NotUsed2" 5 "NotUsed1" 4 "POA" 3 "PPA" 2 "SAPP" 1 "Off" 0 "Null" ;
VAL_TABLE_ FrostWarn_D_Stat 3 "NotUsed" 2 "On_Amber" 1 "On_Red" 0 "Off" ;
VAL_TABLE_ SteWhlLckMsgTxt_D_Rq 3 "NotUsed" 2 "Message_2" 1 "Message_1" 0 "No_Message" ;
VAL_TABLE_ GearRvrse_D_Actl 7 "Fault" 6 "NotUsed_3" 5 "NotUsed_2" 4 "NotUsed_1" 3 "Active_confirmed" 2 "Active_not_confirmed" 1 "Inactive_confirmed" 0 "Inactive_not_confirmed" ;
VAL_TABLE_ SideDetect_SnStat_Invalid 3 "Invalid" 2 "System_Failure" 1 "Blocked" 0 "Clear" ;
VAL_TABLE_ SideDetect_OpStat 7 "NotUsed_3" 6 "NotUsed_2" 5 "NotUsed_1" 4 "Invalid" 3 "Disabled" 2 "On" 1 "Trailer_Tow_Off" 0 "Off" ;
VAL_TABLE_ SideDetect_Present 4 "Sensor_Blocked" 3 "Sensor_Fault" 2 "Flash_On" 1 "Alert_On" 0 "AlertOff_FlashOff_SensrClr" ;
VAL_TABLE_ Off_On_Flash_BulbProveout 3 "Bulb_Proveout" 2 "Flash" 1 "On" 0 "Off" ;
VAL_TABLE_ SideDetect_BLIS_Off_On 2 "BLIS_On_Second_Warning_ON" 1 "BLIS_On_Second_Warning_OFF" 0 "Off" ;
VAL_TABLE_ SideDetect_report 3 "Reporting" 2 "Not_Reporting" 1 "System_Standby" 0 "Initialization" ;
VAL_TABLE_ DrTGate_D_Rq 3 "NotUsed" 2 "Closing" 1 "Opening" 0 "Not_Moving" ;
VAL_TABLE_ WndwSide_D_Stat 3 "BothWindow_Operating" 2 "RearWindow_Operating" 1 "FrontWindow_Operating" 0 "NoWindows_Operating" ;
VAL_TABLE_ DcacElPw_D_Rq 3 "NotUsed" 2 "AC_HighPower_Requested" 1 "AC_LowPower_Requested" 0 "AC_Power_NotRequested" ;
VAL_TABLE_ False_True 1 "True" 0 "False" ;
VAL_TABLE_ Null_Reset 1 "Reset" 0 "Null" ;
VAL_TABLE_ HvacBlwrFront_D_Stat 31 "Not_Used" 20 "Full_On" 19 "95_Percent" 18 "90_Percent" 17 "85_Percent" 16 "80_Percent" 15 "75_Percent" 14 "70_Percent" 13 "65_Percent" 12 "60_Percent" 11 "55_Percent" 10 "50_Percent" 9 "45_Percent" 8 "40_Percent" 7 "35_Percent" 6 "30_Percent" 5 "25_Percent" 4 "20_Percent" 3 "15_Percent" 2 "10_Percent" 1 "5_Percent" 0 "Off" ;
VAL_TABLE_ immoMsgTxt_D_Rq 15 "Immo_Msg_15" 14 "Immo_Msg_14" 13 "Immo_Msg_13" 12 "Immo_Msg_12" 11 "Immo_Msg_11" 10 "Immo_Msg_10" 9 "Immo_Msg_9" 8 "Immo_Msg_8" 7 "Immo_Msg_7" 6 "Immo_Msg_6" 5 "Immo_Msg_5" 4 "Immo_Msg_4" 3 "Immo_Msg_3" 2 "Immo_Msg_2" 1 "Immo_Msg_1" 0 "Immo_Msg_0_Null" ;
VAL_TABLE_ BattTracWarnLamp_B_Rq 1 "On" 0 "Off" ;
VAL_TABLE_ BattTracSrvcRqd_B_Rq 1 "On" 0 "Off" ;
VAL_TABLE_ HtrnWarnLamp_B_Dsply 1 "On" 0 "Off" ;
VAL_TABLE_ HtrnSrvcRqd_B_Dsply 1 "On" 0 "Off" ;
VAL_TABLE_ NoData_Faulty_7E_7F 127 "Faulty" 126 "NoDataExists" ;
VAL_TABLE_ PreCondACSet_D_Actl 3 "Last_User_Setting" 2 "Auto" 1 "On" 0 "Off" ;
VAL_TABLE_ PreCondFanSet_D_Actl 15 "Not_used" 14 "Not_used" 13 "Not_used" 12 "Not_used" 11 "Not_used" 10 "Not_used" 9 "Last_user_setting" 8 "Auto" 7 "Speed_7" 6 "Speed_6" 5 "Speed_5" 4 "Speed_4" 3 "Speed_3" 2 "Speed_2" 1 "Speed_1" 0 "OFF" ;
VAL_TABLE_ PreCondID_No_Actl 0 "Invalid" ;
VAL_TABLE_ PreCondRecrcSet_D_Actl 3 "Last_User_Setting" 2 "Auto" 1 "Recirc" 0 "Outside/Fresh" ;
VAL_TABLE_ PreCondTeSet_Te_Actl 31 "HI" 1 "LO" 0 "Last_driver_setting" ;
VAL_TABLE_ PreCondTPRDef_D_Actl 3 "NotUsed" 2 "On" 1 "Off" 0 "Null" ;
VAL_TABLE_ PreCondModeSet_D_Actl 15 "Not_used" 14 "Not_used" 13 "Not_used" 12 "Not_used" 11 "LastUserSetting" 10 "Auto" 9 "Max_Defrost" 8 "Windshield_Panel_Floor" 7 "Windshield_Panel" 6 "Windshield_(Defrost)" 5 "Windshield_Floor" 4 "Floor" 3 "Panel_Floor" 2 "Panel_(Vent)" 1 "Max_A/C" 0 "Off" ;
VAL_TABLE_ ChargePortPwr_St 2 "LowPower" 1 "HighPower" 0 "Null" ;
VAL_TABLE_ ChargeProfIDPref_St 3 "NotUsed" 2 "Value" 1 "ChargeNow" 0 "Null" ;
VAL_TABLE_ ChrgGlobSched_D_Actl 3 "NotUsed" 2 "On" 1 "Off" 0 "Null" ;
VAL_TABLE_ ChrgLocEndHr_No_Actl 31 "Invalid" 30 "Unknown" ;
VAL_TABLE_ ChrgLocEndMin_No_Actl 63 "Invalid" 62 "Unknown" ;
VAL_TABLE_ ChrgLocProgram_D_Actl 7 "Not_used" 6 "Not_used" 5 "Not_used" 4 "Manual" 3 "TimeofUse" 2 "SmMet" 1 "ChargeImm" 0 "Null" ;
VAL_TABLE_ ChrgLocSchedCat_D_Actl 11 "Reserved" 10 "Window_10" 9 "Window_9" 8 "Window_8" 7 "Window_7" 6 "Window_6" 5 "Window_5" 4 "Window_4" 3 "Window_3" 2 "Window_2" 1 "Window_1" 0 "Null" ;
VAL_TABLE_ ChrgLocHsphs_D_Actl 7 "NotUsed3" 6 "NotUsed2" 5 "NotUsed1" 4 "SouthEast_Lat-_Long+" 3 "SouthWest_Lat-_Long-" 2 "NorthEast_Lat+_Long+" 1 "NorthWest_Lat+_Long-" 0 "NoDataExists" ;
VAL_TABLE_ FuelPumpPwr_D_Stat 7 "NotUsed3" 6 "NotUsed2" 5 "NotUsed1" 4 "Power_Off_Default" 3 "Power_Off_Command" 2 "Power_Off_Service" 1 "Power_Off_Impact" 0 "Power_On" ;
VAL_TABLE_ ChrgrRdyStat_D_Actl 7 "NotUsed4" 6 "NotUsed3" 5 "NotUsed2" 4 "NotUsed1" 3 "Charging" 2 "ChargerFault" 1 "ChargerReady" 0 "NotReady" ;
VAL_TABLE_ PrmtrAlrmEvnt_D_Stat 15 "Diag_Tamper" 14 "Trailer" 13 "Shock_Sensor" 12 "Post_Crash" 11 "Panic" 10 "Intrusion" 9 "Inclination" 8 "Ign_Tamper" 7 "LG_Door" 6 "Decklid" 5 "Hood" 4 "PR_Door" 3 "PF_Door" 2 "DR_Door" 1 "DF_Door" 0 "Null" ;
VAL_TABLE_ SecurityMsgTxt_D_Rq 3 "Message3" 2 "Message2" 1 "Message1" 0 "NoMessage" ;
VAL_TABLE_ BattChrgRdyStat_D_Actl 7 "NotUsed2" 6 "NotUsed1" 5 "Faulted" 4 "ChargeComplete" 3 "Charging" 2 "BatteryChargeReady" 1 "ChargeWait" 0 "NotReady" ;
VAL_TABLE_ BattChrgInhbt_D_Rq 3 "MaintainTargetSoc" 2 "NotUsed" 1 "InhibitChargingThermal" 0 "Enable_Charging" ;
VAL_TABLE_ Fault_7FF_NoData 2047 "Fault" 2046 "NoDataExists" ;
VAL_TABLE_ Deactivate_Activate 1 "Activate" 0 "Deactivate" ;
VAL_TABLE_ PtcHtr_D_Stat 3 "Faulty" 2 "NotUsed" 1 "On" 0 "Off" ;
VAL_TABLE_ PtcHtr_D_Cmd 3 "TurnOn" 2 "AutoMode" 1 "TurnOff" 0 "NoDecision_Initializing" ;
VAL_TABLE_ Fault_FFFFFF 16777215 "Fault" ;
VAL_TABLE_ NoData_Fault_FFFE_FFFF 65535 "Fault" 65534 "NoDataExists" ;
VAL_TABLE_ EngOffTe_B_Dsply 1 "Eng_warm_engh_for_pd" 0 "Eng_not_warm_engh_for_pd" ;
VAL_TABLE_ Fault_FFFF_NoData_FFFE 65535 "Fault" 65534 "NoDataExists" ;
VAL_TABLE_ Fault_1FFF 8191 "Fault" ;
VAL_TABLE_ TrlrBattChrg_D_Stat 3 "Reverse" 2 "Normal" 1 "Low" 0 "Null" ;
VAL_TABLE_ TrlrLampCtl_D_Stat 3 "NotUsed" 2 "TrlrLampCnnctDrvFailure" 1 "TrlrLampNotCnnctDrvFailure" 0 "Null" ;
VAL_TABLE_ ElPw_D_StatStrtStop 15 "NotUsed6" 14 "NotUsed5" 13 "NotUsed4" 12 "NotUsed3" 11 "NotUsed2" 10 "NotUsed1" 9 "Supported_Level_4" 8 "Supported_Level_3" 7 "Supported_Level_2" 6 "Supported_Level_1" 5 "Limited_Support" 4 "Fault_Limited" 3 "LV_Event_in_Progress" 2 "Not_Supported_Imminent" 1 "Supported_All" 0 "Not_Supported" ;
VAL_TABLE_ ImpactEvntFdbck_D_Stat 3 "NotUsed" 2 "EventComplete" 1 "EventInProgress" 0 "Normal" ;
VAL_TABLE_ StopStrtIODTxt_D_Rq 31 "Message31" 30 "Message30" 29 "Message29" 28 "Message28" 27 "Message27" 26 "Message26" 25 "Message25" 24 "Message24" 23 "Message23" 22 "Message22" 21 "Message21" 20 "Message20" 19 "Message19" 18 "Message18" 17 "Message17" 16 "Message16" 15 "Message15" 14 "Message14" 13 "Message13" 12 "Message12" 11 "Message11" 10 "Message10" 9 "Message9" 8 "Message8" 7 "Message7" 6 "Message6" 5 "Message5" 4 "Message4" 3 "Message3" 2 "Message2" 1 "Message1" 0 "NoMessage" ;
VAL_TABLE_ NoData_Fault_7FFE_7FFF 32767 "Fault" 32766 "NoDataExists" ;
VAL_TABLE_ NoData_Fault_3E_3F 63 "Fault" 62 "NoDataExists" ;
VAL_TABLE_ DrvSte_D_Stat 15 "NotUsed10" 14 "NotUsed9" 13 "NotUsed8" 12 "NotUsed7" 11 "NotUsed6" 10 "NotUsed5" 9 "NotUsed4" 8 "NotUsed3" 7 "NotUsed2" 6 "NotUsed1" 5 "Request_Active" 4 "Ignition_Off" 3 "DSR_in_Normal_Idle_Mode" 2 "EPAS_Comm_Disturbed" 1 "DSR_Request_Not_Applicable" 0 "DSR_Deactivated" ;
VAL_TABLE_ StrtrMtrCtlMsgTxt_D_Rq 7 "Start_In_Gear_Allowed" 6 "Pending_Start_Cancelled" 5 "Start_Pending_Please_Wait" 4 "Cranking_Limit_Exceeded" 3 "Press_Brk_and_Shift_to_P_N" 2 "Press_Clutch_and_Brake" 1 "Press_Clutch_To_Start" 0 "No_Display" ;
VAL_TABLE_ Null_Open 1 "Open" 0 "Null" ;
VAL_TABLE_ Invalid_OffOn 0 "Invalid" 1 "Off" 2 "On" ;
VAL_TABLE_ TempDegreesC_DegreesF 0 "Temperature_deg_c" 1 "Temperature_deg_f" ;
VAL_TABLE_ BeltminderAudioMute 2 "On" 1 "Off" 0 "Invalid" ;
VAL_TABLE_ Chime_Source 2 "Cluster" 1 "Infotainment_Sys" 0 "Invalid" ;
VAL_TABLE_ Invalid_DayNight 2 "Night" 1 "Day" 0 "Invalid" ;
VAL_TABLE_ Invalid_12h_24h 2 "24h_mode" 1 "12h_mode" 0 "Invalid" ;
VAL_TABLE_ Invalid_Theme1_2 2 "Theme_2" 1 "Theme_1" 0 "Invalid" ;
VAL_TABLE_ LanguageSelect_St 30 "Slovak" 29 "Arabic" 28 "Cantonese" 27 "Mandarin_Chinese" 26 "Korean" 25 "Japanese_Kanji" 24 "Japanese_Katakana" 23 "Braz_Portuguese" 22 "EU_Portuguese" 21 "Finish" 20 "Norwegian" 19 "Danish" 18 "Swedish" 17 "Hungarian" 16 "Greek" 15 "Czech" 14 "Polish" 13 "Flemish" 12 "Dutch" 11 "Russian" 10 "Turkish" 9 "Mex_Spanish" 8 "EU_Spanish" 7 "Cana_French" 6 "EU_French" 5 "Italian" 4 "German" 3 "NA_English" 2 "UK_English" 1 "Unknown" 0 "Invalid" ;
VAL_TABLE_ Blower_Indicate 15 "Display_Blank" 14 "14_Indicators_On" 13 "13_Indicators_On" 12 "12_Indicators_On" 11 "11_Indicators_On" 10 "10_Indicators_On" 9 "9_Indicators_On" 8 "8_Indicators_On" 7 "7_Indicators_On" 6 "6_Indicators_On" 5 "5_Indicators_On" 4 "4_Indicators_On" 3 "3_Indicators_On" 2 "2_Indicators_On" 1 "1_Indicator_On" 0 "Indicators_Off" ;
VAL_TABLE_ CC_Fr_Stat_User_Adj 7 "Unused4" 6 "Unused3" 5 "Unused2" 4 "Unused1" 3 "Fr_Blwr_Spd_Selection" 2 "FRHS_SetPt_Selection" 1 "FLHS_SetPt_Selection" 0 "None" ;
VAL_TABLE_ HeadLghtHiFdbck_D_Stat 3 "NotUsed" 2 "Cancel" 1 "Hold" 0 "Allow_Change" ;
VAL_TABLE_ Backlit_LED_Status 15 "Unused3" 14 "Unused2" 13 "Unused1" 12 "Night_12" 11 "Night_11" 10 "Night_10" 9 "Night_9" 8 "Night_8" 7 "Night_7" 6 "Night_6" 5 "Night_5" 4 "Night_4" 3 "Night_3" 2 "Night_2" 1 "Night_1" 0 "Off" ;
VAL_TABLE_ Veh_Lock_Status 3 "UNLOCK_DRV" 2 "UNLOCK_ALL" 1 "LOCK_ALL" 0 "LOCK_DBL" ;
VAL_TABLE_ PrkLckCtlMsgTxt_D_Rq 3 "BTSI_DI_3" 2 "BTSI_DI_2" 1 "BTSI_DI_1" 0 "Null_BTSI_DI" ;
VAL_TABLE_ NoShift_Shift 1 "Shift" 0 "NoShift" ;
VAL_TABLE_ CcdMsgTxt_D_RqDsply 15 "Unused8" 14 "Unused7" 13 "Unused6" 12 "Unused5" 11 "Unused4" 10 "Unused3" 9 "Unused2" 8 "StationaryMode" 7 "Mode_Change_Unavailable" 6 "CCD_Temporarily_Off" 5 "CCD_Service_Required" 4 "Faulty" 3 "Sport" 2 "Normal" 1 "Comfort" 0 "No_Mode_Selected" ;
VAL_TABLE_ CrashEvnt_D_Stat 3 "Invalid" 2 "Fuel_Cutoff_Event" 1 "Deploy_Event" 0 "No_Event" ;
VAL_TABLE_ ReducedGuard_D_Stat 3 "NotUsed" 2 "Alarm_On" 1 "Alarm_Off_Previously_On" 0 "Alarm_Off" ;
VAL_TABLE_ HvacPrecondBlwr_D_Rq 15 "NotUsed6" 14 "NotUsed5" 13 "NotUsed4" 12 "NotUsed3" 11 "NotUsed2" 10 "NotUsed1" 9 "Last_User_Setting" 8 "Auto" 7 "Speed7" 6 "Speed6" 5 "Speed5" 4 "Speed4" 3 "Speed3" 2 "Speed2" 1 "Speed1" 0 "Off" ;
VAL_TABLE_ HvacPrecondMode_D_Rq 15 "NotUsed4" 14 "NotUsed3" 13 "NotUsed2" 12 "NotUsed1" 11 "Last_User_Settings" 10 "Auto" 9 "Max_Defrost" 8 "Windshield_Panel_Floor" 7 "Windshield_Panel" 6 "Windshield" 5 "Windshield_Floor" 4 "Floor" 3 "Panel_Floor" 2 "Panel" 1 "MAX_AC" 0 "Off" ;
VAL_TABLE_ ButtonNotPressed 1 "Button_Pressed" 0 "Button_Not_Pressed" ;
VAL_TABLE_ Null_Pressed 1 "Pressed" 0 "Null" ;
VAL_TABLE_ FobComm_D_Stat 3 "NotUsed" 2 "RemEngStartOK" 1 "RemEngStartFail" 0 "Null" ;
VAL_TABLE_ PudLamp_D_Rq 3 "RAMP_DOWN" 2 "RAMP_UP" 1 "ON" 0 "OFF" ;
VAL_TABLE_ WndwGlbl_D_Cmd 7 "NotUsed3" 6 "NotUsed2" 5 "NotUsed1" 4 "GLEARN" 3 "GCLOSE" 2 "GOPEN" 1 "GSTOP" 0 "Null" ;
VAL_TABLE_ LockMsg 7 "MSG7" 6 "MSG6" 5 "MSG5" 4 "MSG4" 3 "MSG3" 2 "MSG2" 1 "MSG1" 0 "NO_WARNING" ;
VAL_TABLE_ ChildLockDisplay 3 "NOT_SUPPORTED" 2 "ERROR" 1 "CHILD_UNLOCK" 0 "CHILD_LOCK" ;
VAL_TABLE_ Null_Lock_Unlock 3 "NotUsed" 2 "Unlock" 1 "Lock" 0 "Null" ;
VAL_TABLE_ Wiper 15 "NO_DATA_EXISTS" 14 "STALLED" 13 "RESERVED" 12 "AUTO_ADJUST" 11 "COURTESYWIPE" 10 "AUTO_HIGH" 9 "AUTO_LOW" 8 "WASH" 7 "MIST_FLICK" 6 "MAN_HIGH" 5 "MAN_LOW" 4 "MAN_INT_ON" 3 "MAN_INT_OFF" 2 "OFF_MOVING" 1 "AUTO_OFF" 0 "OFF" ;
VAL_TABLE_ Turn_switch 3 "Unused_Treat_As_Off" 2 "Right" 1 "Left" 0 "Off" ;
VAL_TABLE_ PrkLght_D_Stat 3 "Park_Both" 2 "Park_Right" 1 "Park_Left" 0 "Off" ;
VAL_TABLE_ LghtAmb_D_Sns 7 "No_Data_Exists" 6 "Unused2" 5 "Unused1" 4 "Tunnel_Off" 3 "Tunnel_On" 2 "Twilight" 1 "Light" 0 "Dark" ;
VAL_TABLE_ HeadLghtSwtch_D_Stat 3 "Autolamp" 2 "Headlamp" 1 "Parklamp" 0 "Off" ;
VAL_TABLE_ EmgcyBrkLamp_D_Rq 3 "NotUsed" 2 "Active_at_standstill" 1 "Active_at_speed" 0 "Inactive" ;
VAL_TABLE_ GearLvrPos_D_Unfilt 7 "Invalid" 6 "NotUsed" 5 "In_between" 4 "Low" 3 "Drive" 2 "Neutral" 1 "Reverse" 0 "Park" ;
VAL_TABLE_ EDrvTqMntrRconfg_D_Cmd 7 "OK" 6 "Disable_Cruise" 5 "NotUsed4" 4 "Supercreep" 3 "NotUsed3" 2 "NotUsed2" 1 "Engine_shutdown" 0 "NotUsed" ;
VAL_TABLE_ OpenPressedFault 3 "Fault" 2 "Unused" 1 "Pressed" 0 "Open" ;
VAL_TABLE_ LaHandsOff_D_Dsply 3 "Suppressed" 2 "Level2" 1 "Level1" 0 "HandsOn" ;
VAL_TABLE_ Avail_Unavail 1 "Unavailable" 0 "Available" ;
VAL_TABLE_ LaActvStats_D_Dsply 31 "Unused7" 30 "LA_Off" 29 "Unused5" 28 "Unused4" 27 "Unused3" 26 "Unused2" 25 "Unused1" 24 "InerveneLeft_InterveneRght" 23 "WarnLeft_InterveneRight" 22 "SuppressLeft_InterveneRght" 21 "AvailLeft_InterveneRhtt" 20 "NoLeft_InterveneRight" 19 "InterveneLeft_WarnRight" 18 "WarnLeft_WarnRight" 17 "SuppressLeft_WarnRight" 16 "AvailableLeft_WarnRight" 15 "NoLeft_WarnRight" 14 "InterveneLeft_SuppressRght" 13 "WarnLeft_SuppressRight" 12 "SuppressLeft_SuppressRight" 11 "AvailLeft_SuppressRight" 10 "NoLeft_SuppressRight" 9 "InterveneLeft_AvailRight" 8 "WarnLeft_AvailRight" 7 "SuppressLeft_AvailRight" 6 "AvailableLeft_AvailRight" 5 "NoLeft_AvailableRight" 4 "InterveneLeft_NoRight" 3 "WarnLeft_NoRight" 2 "SuppressLeft_NoRight" 1 "AvailableLeft_NoRight" 0 "NoLeft_NoRight" ;
VAL_TABLE_ AhbcHiBeam_D_Rq 3 "Deactivated_Unavailabl" 2 "Unused" 1 "Main_HighBeamRecommend" 0 "Dipped_LowBeamRecommend" ;
VAL_TABLE_ GrllShtrPos_D_Cmd 15 "Fully_Open" 14 "Position14" 13 "Position13" 12 "Position12" 11 "Position11" 10 "Position10" 9 "Position9" 8 "Position8" 7 "Position7" 6 "Position6" 5 "Position5" 4 "Position4" 3 "Position3" 2 "Position2" 1 "Position1" 0 "Fully_Closed" ;
VAL_TABLE_ LifeCycMde_D_Actl 3 "Transport" 2 "NotUsed" 1 "Factory" 0 "Normal" ;
VAL_TABLE_ TrnMsgTxt_D_Rq 15 "Message_15" 14 "Message_14" 13 "Message_13" 12 "Message_12" 11 "Message_11" 10 "Message_10" 9 "Message_9" 8 "Message_8" 7 "Message_7" 6 "Message_6" 5 "Message_5" 4 "Message_4" 3 "Message_3" 2 "Message_2" 1 "Message_1" 0 "NoMessage" ;
VAL_TABLE_ DieslPrtcRgen_D_Rq 7 "Unused_2" 6 "Unused_1" 5 "Full_Regen_2" 4 "Full_Regen_1" 3 "HeatUp_3" 2 "HeatUp_2" 1 "HeatUp_1" 0 "Normal_Mode_NoRegen" ;
VAL_TABLE_ ClimtHeat_D_Rq 7 "NotUsed4" 6 "NotUsed3" 5 "NotUsed2" 4 "PtcHtrTestMde" 3 "Defrost_Defog" 2 "FastTempPullDownHeatingReq" 1 "OpportunisticHeatingReq" 0 "NoHeatingRequest" ;
VAL_TABLE_ TrnCapHlth_Actl 3 "Capacitor_OK" 2 "Degraded_Capacitor" 1 "Capacitor_State_Unknown" 0 "Capacitor_Fault" ;
VAL_TABLE_ TrnSecPrkStat_D_Actl 7 "Faulty" 6 "Fault_Released" 5 "Fault_Latched" 4 "Recouple_in_Progress" 3 "Mechanism_Released" 2 "RTP_in_Progress" 1 "Pending" 0 "Latched" ;
VAL_TABLE_ TrnGear_D_Actl 7 "Fault" 6 "NotUsed" 5 "Manual" 4 "Drive" 3 "Neutral" 2 "Reverse" 1 "Park" 0 "Transition_State" ;
VAL_TABLE_ TrnNtrlTowCmd_D_Actl 3 "NotUsed" 2 "Neutral_Tow_Entry" 1 "Car_Wash_Mode" 0 "Normal_Mode" ;
VAL_TABLE_ TrnValidGear_D_Cnfm 3 "Accept" 2 "Reject" 1 "Internal_Request" 0 "No_Command" ;
VAL_TABLE_ TrnGear_D_RqPt 7 "Fault" 6 "NotUsed" 5 "Manual" 4 "Drive" 3 "Neutral" 2 "Reverse" 1 "Park" 0 "No_Gear" ;
VAL_TABLE_ TrnValidGearRq_D_Stat 3 "Valid_Request" 2 "Valid_Degraded_Request" 1 "Invalid_Request" 0 "No_Request" ;
VAL_TABLE_ NoData_Fault_3FE_3FF 1023 "Fault" 1022 "NoDataExists" ;
VAL_TABLE_ ClimtCool_D_Rq 7 "NotUsed4" 6 "NotUsed3" 5 "NotUsed2" 4 "ElACTestMde" 3 "Defrost_Defog" 2 "FastTempPullDownCoolReq" 1 "OpportunisticCoolingReq" 0 "NoCoolingRequest" ;
VAL_TABLE_ HtrnHvilOpen_B_Actl 1 "HVIL_is_Open" 0 "Normal_Operation" ;
VAL_TABLE_ EngTeHi_B_Actl 1 "EngineTempHigh" 0 "Normal" ;
VAL_TABLE_ Eng_D_StatPwPck 7 "NotUsed3" 6 "NotUsed2" 5 "Engine_Start_Cold_Cat" 4 "Engine_Disabled" 3 "Engine_Running" 2 "Engine_Run_CSER" 1 "Engine_Start" 0 "Off" ;
VAL_TABLE_ EngFuelCutFull_B_Inhbt 1 "Inhibit_DFSO" 0 "Normal" ;
VAL_TABLE_ EngFuelCutFull_B_Rq 1 "FuelCutRequest" 0 "NormalOperation" ;
VAL_TABLE_ Fault_7FF 2047 "Fault" ;
VAL_TABLE_ EngStopFst_B_Rq 1 "FastEngineShutdown" 0 "NormalOperation" ;
VAL_TABLE_ EngStrtCold_B_Rq 1 "ExtremeColdStart" 0 "NormalStart" ;
VAL_TABLE_ EngStrtSmooth_D_Rq 7 "NotUsed" 6 "Smooth_NoPedal" 5 "Smooth_LightPedal" 4 "Smooth_MediumPedal" 3 "Smooth_HeavyPedal" 2 "Smooth_WOP" 1 "Smooth_Cold" 0 "Smooth_ExtremeCold" ;
VAL_TABLE_ Fault_FFF 4095 "Fault" ;
VAL_TABLE_ VehStrtStop_D_Rq 3 "NotUsed" 2 "Vehicle_Start_Request" 1 "Vehicle_Stop_Request" 0 "NoRequest" ;
VAL_TABLE_ HvacRec_D_RqMxBatt 15 "NotUsed5" 14 "NotUsed4" 13 "NotUsed3" 12 "NotUsed2" 11 "NotUsed1" 10 "No_Override" 9 "90Percent_RecircMax" 8 "80Percent_RecircMax" 7 "70Percent_RecircMax" 6 "60Percent_RecircMax" 5 "50Percent_RecircMax" 4 "40Percent_RecircMax" 3 "30Percent_RecircMax" 2 "20Percent_RecircMax" 1 "10Percent_RecircMax" 0 "0Percent_RecircFullOpen" ;
VAL_TABLE_ FuelCtlOpenLp_B_Inhbt 1 " Inhibit_FullPedal_Actions" 0 "Normal_Operation" ;
VAL_TABLE_ EngStrtStop_B_SrcSrvc 1 "Eng_StartStop_for_Service" 0 "Not_Requested" ;
VAL_TABLE_ EngStrtStop_B_SrcCat 1 "Eng_StartStop_for_Catalyst" 0 "Not_Requested" ;
VAL_TABLE_ PrkBrkStatus 7 "GeneralFault_MaintenceMode" 6 "ECD_by_Brake_ECU_Active" 5 "EPB_Limphome_Active" 4 "Rear_Caliper_Open" 3 "RWU_By_EPB_Active" 2 "Rear_Caliper_Transition" 1 "Rear_Caliper_Closed" 0 "Not_Supported" ;
VAL_TABLE_ ElLoadCtl_D_Rq 7 "Unused3" 6 "Unused2" 5 "Unused1" 4 "HoldAllDrvrInvisibleLoads" 3 "StdDriverInvisibleLoadsOn" 2 "AllDriverInvisibleLoadsOn" 1 "All_Possible_Loads_Off" 0 "No_Request" ;
VAL_TABLE_ BattTracCool 3 "NotUsed" 2 "DCDC_Overtemperature" 1 "CoolingRequiredbyDCDC" 0 "NoCoolingRequiredbyDCDC" ;
VAL_TABLE_ NotReady_Active_Fault 3 "Fault" 2 "Active" 1 "Ready" 0 "Not_Ready" ;
VAL_TABLE_ Quality_Data 3 "OK" 2 "Not_Within_Specifications" 1 "Eval_In_Progress" 0 "Fault" ;
VAL_TABLE_ PwSrcULoFalt_D_Stat 3 "Fault_No_Output" 2 "Fault_Reduced_Output" 1 "Fault_NonSpecific" 0 "No_Fault" ;
VAL_TABLE_ Connect_Discon_Loose 1 "Loose_or_Disconnected" 0 "Connected" ;
VAL_TABLE_ DontCare_StartInhibit 1 "Start_Inhibit" 0 "Dont_Care" ;
VAL_TABLE_ BattULoChrg_D_Rq 3 "Low_Battery_Temperature" 2 "Charging_Requested" 1 "Chrg_Requested_HighCurrent" 0 "No_Request" ;
VAL_TABLE_ PwSysULoFalt_D_Stat 15 "Not_Used_6" 14 "LowBatterySOC" 13 "PSS_Shed2_Contin" 12 "Not_Used_4" 11 "Not_Used_3" 10 "Not_Used_2" 9 "BattMonitoringSensorFault" 8 "LowBattVoltDuringPwSrcOn" 7 "LowBatt2_PowerSaveMode" 6 "LowBatt1_Warning" 5 "Overvoltage" 4 "Fault_NoOutput" 3 "Fault_ReducedOutput" 2 "Fault_Nonspecific" 1 "Cluster_Proveout" 0 "No_Fault" ;
VAL_TABLE_ AccStopMde_D_Rq 3 "Stop_Mode_Active" 2 "EPBApplyOrBrakeReleaseWarn" 1 "Limit_Rolling_Speed" 0 "Stop_Mode_Not_Active" ;
VAL_TABLE_ EngFuelCutFull_B_Sched 1 "DFSO_Event_Scheduled" 0 "Normal" ;
VAL_TABLE_ Eng_D_Stat 3 "NotUsed" 2 "EngAutoStopped" 1 "EngOn" 0 "EngOff" ;
VAL_TABLE_ ElPw_D_Stat 7 "NotUsed_3" 6 "NotUsed_2" 5 "NotUsed_1" 4 "Fault_Limited" 3 "LV_Event_In_Progress" 2 "Not_Supported_Imminent" 1 "Supported" 0 "Not_Supported" ;
VAL_TABLE_ PwPckTq_D_Stat 3 "PwPckOn_TqAvailable" 2 "StartInPrgrss_TqNotAvail" 1 "PwPckOn_TqNotAvailable" 0 "PwPckOff_TqNotAvailable" ;
VAL_TABLE_ BattTracCool_D_Falt 3 "NotUsed" 2 "CoolSysPartialyOperational" 1 "Cooling_System_Faulted" 0 "Cooling_System_Operational" ;
VAL_TABLE_ Fault_FF 255 "Fault" ;
VAL_TABLE_ ElCmprOverTe_D_Stat 3 "OverTempStop" 2 "OverTempWarning" 1 "Normal" 0 "Undefined" ;
VAL_TABLE_ ElCmprUHi_D_Stat 3 "Overvoltage" 2 "Undervoltage" 1 "InRange" 0 "Undetermined" ;
VAL_TABLE_ ElCmpr_D_Stat 7 "Signal_Invalid" 6 "Comp_Off_ActlSpd_Abnormal" 5 "Comp_Off_TrgtSpd_OutRange" 4 "Comp_Shutdown" 3 "Comp_Stopped_Self_Protect" 2 "Comp_Degraded" 1 "Comp_On" 0 "Comp_Off" ;
VAL_TABLE_ Southern_Northern 3 "Fault" 2 "Northern" 1 "Southern" 0 "Invalid" ;
VAL_TABLE_ PsngrFrntDetct_D_Actl 3 "Unknown" 2 "Empty" 0 "Faulty" 1 "Occupied" ;
VAL_TABLE_ Normal_Mode1_2 3 "Undefined" 2 "Mode2" 1 "Mode1" 0 "Normal_Mode" ;
VAL_TABLE_ LaActvAvail 3 "LKA_LCA_LDW_Avail" 2 "LCA_LKA_Avail_LDW_Suppress" 1 "LCA_LKA_Suppress_LDW_Avail" 0 "LCA_LKA_LDW_Suppress" ;
VAL_TABLE_ LA_NotDenied 1 "LA_Denied" 0 "LA_Not_Denied" ;
VAL_TABLE_ HandsOn_Off 1 "Hands_Off" 0 "Hands_On" ;
VAL_TABLE_ Smooth_Quick 1 "Quick" 0 "Smooth" ;
VAL_TABLE_ None_Low_Med_High 3 "High" 2 "Medium" 1 "Low" 0 "None" ;
VAL_TABLE_ LdwActvStats 7 "LDW_Suppress_Right_Left" 6 "Not_Used2" 5 "LDW_Suppress_Right" 4 "LDW_Warning_Right" 3 "LDW_Suppress_Left" 2 "LDW_Warning_Left" 1 "LDW_DemoVibration" 0 "LDW_Idle" ;
VAL_TABLE_ Fault_3FF 1023 "Fault" ;
VAL_TABLE_ EngStrtStop 15 "Unused_7" 14 "Unused_6" 13 "Unused_5" 12 "Unused_4" 11 "Unused_3" 10 "Unused_2" 9 "Unused_1" 8 "Force_Pull_Down" 7 "Force_Pull_Up" 6 "Pull_Down_Inhibit_Pull_Up" 5 "Inhibit_Change" 4 "Inhibit_Pull_Up" 3 "Pull_Down" 2 "Inhibit_Pull_Down" 1 "Pull_Up" 0 "No_Request" ;
VAL_TABLE_ TrnMde_D_Rq 15 "Unused_4" 14 "Unused_3" 13 "Unused_2" 12 "Unused_1" 11 "InOutLckedHydStandby" 10 "InputOutputLocked" 9 "OutputLockedHydStandby" 8 "OutputLocked" 7 "ReducedOutTqHydStandby" 6 "Reduced_Output_Torque" 5 "TransInTqHydStandby" 4 "Transmit_Input_Torque" 3 "ActNeutralHydStandby" 2 "Active_Neutral" 1 "NeutralHydraulicStdby" 0 "Neutral" ;
VAL_TABLE_ Fault_F 15 "Fault" ;
VAL_TABLE_ Fault_1F 31 "Fault" ;
VAL_TABLE_ TmsStatRqDsply 15 "Reserved4" 14 "Reserved3" 13 "Reserved2" 12 "Crawl_Mode_4LOW_Reqd" 11 "Economy_Mode_Select" 10 "ModeChangeNotAvailable" 9 "Terrain_Sys_Not_Avail" 8 "Terrain_System_Fault" 7 "Mode_Change_InProgress" 6 "Dynamics_Mode_Select" 5 "Rock_Crawl_Mode_Select" 4 "Sand_Mode_Select" 3 "Mud_Ruts_Mode_Select" 2 "Low_Mu_Mode_Select" 1 "Special_Modes_Off" 0 "No_Message" ;
VAL_TABLE_ LockInhibit 1 "Inhibit" 0 "No_Inhibit" ;
VAL_TABLE_ DieslFuelBio_B_ActlDrv 1 "Biodiesel_User" 0 "Non_Biodiesel_User" ;
VAL_TABLE_ Invalid_FFF 4095 "Invalid" ;
VAL_TABLE_ ParkAid_Chime 15 "Zone15_Chime" 14 "Zone14_Chime" 13 "Zone13_Chime" 12 "Zone12_Chime" 11 "Zone11_Chime" 10 "Zone10_Chime" 9 "Zone9_Chime" 8 "Zone8_Chime" 7 "Zone7_Chime" 6 "Zone6_Chime" 5 "Zone5_Chime" 4 "Zone4_Chime" 3 "Zone3_Chime" 2 "Zone2_Chime" 1 "Zone1_Chime" 0 "No_Chime" ;
VAL_TABLE_ Shed_Feature_Group_ID 16 "PtcHeater" 14 "HtdMirr" 13 "HvacRearBlwr_Third" 12 "HvacRearBlwr_Second" 11 "HvacRearBlwr_First" 31 "All LSHED1 Features" 10 "Htd_Windscrn" 9 "SpltHtdBcklight_HtdMirr" 8 "HtdBcklight_HtdMirr" 7 "HtdCoolSeat_FrtDriver" 6 "HtdCoolSeat_FrtPass" 5 "HtdCoolSeat_RearPass" 4 "HtdCoolSeat_RearDriver" 3 "SmartTrlrTowBattCharge" 2 "Htd_StrWhl" 1 "Htd_Washer_Fluid" 0 "No_LSHED1_Features" 15 "Engine_Coolant_Fan" ;
VAL_TABLE_ CoolantFanStepAct 31 "Unused7" 30 "Unused6" 29 "Unused5" 28 "Unused4" 27 "Unused3" 26 "Unused2" 25 "Unused1" 23 "Step23" 22 "Step22" 21 "Step21" 20 "Step20" 19 "Step19" 18 "Step18" 17 "Step17" 16 "Step16" 15 "Step15" 14 "Step14" 13 "Step13" 12 "Step12" 11 "Step11" 10 "Step10" 9 "Step9" 8 "Step8" 7 "Step7" 6 "Step6" 5 "Step5" 4 "Step4" 3 "Step3" 2 "Step2" 1 "Step1" 24 "Max_Fan_Speed_Req" 0 "Fan_Cmd_Off" ;
VAL_TABLE_ Null_Cancel 1 "Cancel" 0 "Null" ;
VAL_TABLE_ Veh_Lock_Requestor 31 "Unused8" 30 "Unused7" 29 "Unused6" 28 "Rgtm_Shutlock_Switch" 27 "Boundary_Alert" 26 "Transit_Vehicle_Relock" 25 "Transit_Cargo_Relock" 24 "Transit_Ajar_Lock" 23 "Diagnostics" 22 "Console_Lock" 21 "Child_Lock" 20 "Double_Lock" 19 "Passive_Pasenger" 18 "Passive_Driver" 17 "Slam_Lock_Protect" 16 "SYNC" 15 "Passport" 14 "Passive_Smart_Unlock" 13 "Autorelock" 12 "RemoteStart" 0 "Null" 1 "Autolock" 11 "Smart_Unlock" 10 "Sliding_Door" 9 "Passive" 8 "Remote" 7 "Programming" 6 "Powerslide" 5 "Keypad" 4 "Key_Cylinder" 3 "Interior" 2 "Auto_Unlock" ;
VAL_TABLE_ EPAS_FAILURE 3 "SERVICE_POWER_STEERING_NOW" 2 "SERVICE_POWER_STEERING" 1 "POWER_STRG_ASSIST_FAULT" 0 "EPAS_OK_NO_MESSAGE" ;
VAL_TABLE_ Perimeter_Alarm_Mode 3 "Activated" 2 "Armed" 1 "Prearmed" 0 "Disarmed" ;
VAL_TABLE_ Invalid_FFFF 65535 "Invalid" ;
VAL_TABLE_ FdaStat_D_Dsply 7 "Undefined_3" 6 "Undefined_2" 5 "Undefined_1" 4 "Distance_Alert_Unavailable" 3 "DistanceAlertUnavail_Low" 2 "DistanceAlertUnavailActive" 1 "Distance_Alert_Available" 0 "Distance_Alert_Off" ;
VAL_TABLE_ OilPressureWarning 1 "Low_Pressure_Lamp_On" 0 "Normal_Pressure_Lamp_Off" ;
VAL_TABLE_ MyKey_KeyTypeChangeReq 3 "Search_PE_BackupSlot" 2 "Clear_All_MyKeys" 1 "Request_New_MyKey" 0 "None" ;
VAL_TABLE_ MyKey_Key_Count 13 "Thirteen" 12 "Twelve" 11 "Eleven" 10 "Ten" 9 "Nine" 8 "Eight" 7 "Seven" 6 "Six" 5 "Five" 4 "Four" 3 "Three" 2 "Two" 1 "One" 0 "Zero" 15 "Invalid" 14 "Unlimited" ;
VAL_TABLE_ GearEngag_D_Actl 7 "Undefined" 6 "Fwd_Clutch_Fully_Engaged" 5 "Neutral_Idle" 4 "Disengaged_to_Neutral_Idle" 3 "Disengaged_to_Neutral_Park" 2 "Engagement_in_Progress" 1 "InitializeFwdClutchEngagmt" 0 "Park_Neutral" ;
VAL_TABLE_ Shed_Level_Req 7 "Unused_2" 6 "Loads_On" 5 "SHED_ENG_OFF" 4 "SOON_ENG_OFF" 3 "SHED2_CONTIN" 2 "SHED2_TRANS" 1 "SHED1" 0 "NO_SHED" ;
VAL_TABLE_ BpedMove_D_Actl 3 "Unknown" 2 "DriverApplyingBrakePedal" 1 "NoAutonomousBrkPdlMovement" 0 "AutonomousBrkPedalMove" ;
VAL_TABLE_ Eastern_Western 0 "Invalid" 1 "Eastern" 2 "Western" 3 "Fault" ;
VAL_TABLE_ EATC_Temp_Digit3 2 "_5" 1 "_0" 0 "OFF" ;
VAL_TABLE_ EATC_Units 2 "Fahrenheit" 1 "Celsius" 0 "Off" ;
VAL_TABLE_ BattTracOffFst_D_Actl 3 "Unexpected_Contactor_Open" 2 "Restraints_Impact_Event" 1 "Interlock_Open" 0 "Normal" ;
VAL_TABLE_ Invalid_1FF 511 "Invalid" ;
VAL_TABLE_ ChargeMode 7 "Undefined_2" 6 "Undefined_1" 5 "Battery_Identify" 4 "Battery_Refresh" 3 "SlowRegenAllowNoDischarge" 2 "Fast_Regen_Allowed" 1 "Slow_Regen_Allowed" 0 "Conventional_Charging" ;
VAL_TABLE_ Unknown_FFFE_Invalid_FFFF 65535 "Invalid" 65534 "Unknown" ;
VAL_TABLE_ SAPPAngleControlStat5 1 "StrgColTorqueExceed_EAROn" 0 "ExternalSigContentOKforEAC" ;
VAL_TABLE_ Closed_Open_Active_Fault 3 "Fault" 2 "Active" 1 "Open" 0 "Closed" ;
VAL_TABLE_ SAPPAngleControlStat2 1 "Rel_ExtSteeringAngleReqx" 0 "NoRel_ExtSteeringAngleReqx" ;
VAL_TABLE_ SAPPAngleControlStat3 1 "EARactiveNoReverseEngage" 0 "ExternalSigContentOKforEAC" ;
VAL_TABLE_ RstrnImpactEvntStatus 7 "Invalid" 6 "Not_Used_4" 5 "Threshold_2_Exceeded" 4 "Not_Used_3" 3 "Threshold_1_Exceeded" 2 "Not_Used_2" 1 "Not_Used_1" 0 "Normal" ;
VAL_TABLE_ EDRTriggerEvntSync 1 "Threshold_Exceeded" 0 "Normal" ;
VAL_TABLE_ EngTeColdPrtct_D_Stats 3 "Engine_Warm_RdcPwr" 2 "OK_to_Drive" 1 "Engine_Warm_PlsWait" 0 "Normal_Operation" ;
VAL_TABLE_ HILL_DESC_MC 7 "Fault_Detected" 6 "Cooling_Down" 5 "Abort_Apply_Brakes" 4 "Active" 3 "Disabled" 2 "Enabled" 1 "Off_Road" 0 "Normal" ;
VAL_TABLE_ Closed_Ajar 1 "Ajar" 0 "Closed" ;
VAL_TABLE_ CADS_Autio_Mute 7 "Unknown" 6 "Attenuation_6" 5 "Attenuation_5" 4 "Attenuation_4" 3 "Attenuation_3" 2 "Attenuation_2" 1 "Attenuation_1" 0 "No_Attenuation_of_Audio" ;
VAL_TABLE_ Quality_Factor 3 "OK" 2 "Not_Within_Specifications" 1 "No_Data_Exists" 0 "Faulty" ;
VAL_TABLE_ Null_Day_Night 3 "NotUsed" 2 "Night" 1 "Day" 0 "Null" ;
VAL_TABLE_ Null_Flash_High 3 "NotUsed" 2 "High" 1 "Flash_to_Pass" 0 "Null" ;
VAL_TABLE_ GearPos_D_Actl 15 "Unknown" 14 "Reverse" 13 "Undefined_5" 12 "Undefined_4" 11 "Undefined_3" 10 "Tenth" 9 "Ninth" 8 "Eighth" 7 "Seventh" 6 "Sixth" 5 "Fifth" 4 "Fourth" 3 "Third" 2 "Second" 1 "First" 0 "Neutral" ;
VAL_TABLE_ OffOn_SlowFast_Flash 3 "Fast_Flash" 2 "Slow_Flash" 1 "On" 0 "Off" ;
VAL_TABLE_ AwdStat_D_RqDsply 31 "NotUsed9" 30 "NotUsed8" 29 "NotUsed7" 28 "To_Engage_4x4_Release_Aped" 27 "To_Engage_4x4_Slow_To_3MPH" 26 "Shift_To_Neutral" 25 "Lkr_Mode_Unavail_TMS" 24 " _4x4_Mode_Unavail_TMS" 23 "Out_of_4Low_Crawl" 22 "AWD_PTU_Oil_Changed" 21 "Change_AWD_PTU_Oil" 20 "Neutral_Tow_Disabled" 19 "Neutral_Tow_Enabled" 18 "AWD_OFF" 17 "_4x4_Off_Road_Speed" 16 "_4x4_Extreme_Off_Road_Mode" 15 "_4x4_Exiting_Off_Road" 14 "_4x4_Off_Road_Mode" 10 "_4x4_Locked_Temporarily" 9 "Shift_In_Progress" 13 "Blocked_Shift_Assist" 12 "_4x4_Auto_Restored" 11 "_4x4_Disabled_Temporarily" 7 "Out_of_4Low__Neutral" 6 "Out_of_4Low__Brake" 5 "Out_of_4Low__Speed" 4 "Into_4Low__Clutch" 3 "Into_4Low__Neutral" 2 "Into_4Low__Brake" 1 "Into_4Low__Speed" 0 "Normal__No_Message" 8 "Out_of_4Low__Clutch" ;
VAL_TABLE_ AngleReached 1 "RequestedAngleNotReached" 0 "RequestedAngleCanBeReached" ;
VAL_TABLE_ WhlDir 3 "Failed" 2 "Unknown" 1 "Backward" 0 "Forward" ;
VAL_TABLE_ VehVLimStat_D_Actl 7 "Undefined_3" 6 "Undefined_2" 5 "Undefined_1" 4 "ASL_Fault_Condition" 3 "Active_and_Limiting" 2 "Active_but_Not_Limiting" 1 "Standby" 0 "Off" ;
VAL_TABLE_ Unknown_Fault_1FE_1FF 511 "Fault" 510 "Unknown" ;
VAL_TABLE_ Fault_NoFault 1 "Fault" 0 "No_Fault" ;
VAL_TABLE_ TrnIpcDsplyMde_D_Actl 7 "Manual_3" 6 "Manual_2" 5 "Manual_1_Low" 4 "Sport" 3 "Drive" 2 "Neutral" 1 "Reverse" 0 "Park" ;
VAL_TABLE_ TrnIpcDsplyMde_D_Stat 3 "Reserved_Blank_No_Display" 2 "Flash" 1 "On" 0 "Blank_No_Display" ;
VAL_TABLE_ TrnIpcDsplyGear_D_Actl 15 "No_Gear_Selected" 14 "_14th_Gear" 13 "_13th_Gear" 12 "_12th_Gear" 11 "_11th_Gear" 10 "_10th_Gear" 9 "_9th_Gear" 8 "_8th_Gear" 7 "_7th_Gear" 6 "_6th_Gear" 5 "_5th_Gear" 4 "_4th_Gear" 3 "_3rd_Gear" 2 "_2nd_Gear" 1 "_1st_Gear" 0 "Neutral" ;
VAL_TABLE_ TerrMde_D_Actl 7 "Fail_Safe_Default" 6 "Dynamic_Mode" 5 "Rock_Crawl_Mode" 4 "Mud_Ruts_Mode" 3 "Sand_Mode" 2 "Undefined" 1 "Low_Mu_Mode" 0 "Special_Operating_Mode_Off" ;
VAL_TABLE_ TerrMdeChng_D_Rdy 7 "Fault" 6 "Undefined_2" 5 "Undefined_1" 4 "ModeUnavailDrInputRqd" 3 "SpOpModes_NotSupported" 2 "ModeUnavailDynamicCond" 1 "Module_In_Initialization" 0 "Mode_Change_Available" ;
VAL_TABLE_ Unknown_Fault_FFFE_FFFF 65535 "Fault" 65534 "Unknown" ;
VAL_TABLE_ Invalid_FFFFFF 16777215 "Invalid" ;
VAL_TABLE_ AutoParkSpdExitCond 1 "SpeedLimitExceededEAROn" 0 "ExternalSigContentOKforEAC" ;
VAL_TABLE_ EngOilLvlDsply_D_Rq 15 "EngOil_LevelSys_CheckFault" 14 "Reserved_2" 13 "Reserved_1" 12 "Conditions_Unsuitable" 11 "Dipstick_Below_Minimum" 10 "Dipstick_Above_Maximum" 9 "Dipstick_Minimum" 8 "Dipstick_12_5_MinMaxRange" 7 "Dipstick_25_MinMaxRange" 6 "Dipstick_37_5_MinMaxRange" 5 "Dipstick_50_MinMaxRange" 4 "Dipstick_62_5_MinMaxRange" 3 "Dipstick_75_MinMaxRange" 2 "Dipstick_87_5_MinMaxRange" 1 "Dipstick_Maximum_Displayed" 0 "No_Message" ;
VAL_TABLE_ HdcMde_D_Actl 7 "Fault" 6 "Temporarily_Unavailable" 5 "NotEnabled_WrongGearSel" 4 "NotEnabled_SpdLimitExceed" 3 "Active_Braking" 2 "Not_Active_Braking" 1 "Off" 0 "Undefined" ;
VAL_TABLE_ GearLvrPos_D_Actl 15 "Fault" 14 "Unknown_Position" 13 "Undefined_Treat_as__Fault" 12 "Undefined_Treat_as_Fault" 11 "sixth" 10 "fifth" 9 "fourth" 8 "third" 7 "second" 6 "first" 5 "Low" 4 "Sport_DriveSport" 3 "Drive" 2 "Neutral" 1 "Reverse" 0 "Park" ;
VAL_TABLE_ FcwMsgTxt_D_Rq 7 "Undefined_3" 6 "Undefined_2" 5 "Low_Visibility" 4 "Unavailable_DueTo_LowSpeed" 3 "Available" 2 "Unavailable" 1 "Off" 0 "No_Text" ;
VAL_TABLE_ FcwSens_B_Actl 3 "FCW_Sensitivity_3" 2 "FCW_Sensitivity_2" 1 "FCW_Sensitivity_1" 0 "Not_Used" ;
VAL_TABLE_ LastSettind_DefaultOn 1 "Default_On" 0 "Last_Setting" ;
VAL_TABLE_ EngTurboMde_D_Actl 3 "Fault" 2 "One_Turbo_Active" 1 "Two_Turbos_Active" 0 "Initializing" ;
VAL_TABLE_ EngPullUpPullDown 15 "Undefined_7" 14 "Undefined_6" 13 "Undefined_5" 12 "Undefined_4" 8 "Force_Pull_Down" 7 "Force_Pull_Up" 6 "PullDown_Inhibit_PullUp" 5 "Inhibit_Change" 4 "Inhibit_Pull_Up" 3 "Pull_Down" 2 "Inhibit_Pull_Down" 1 "Pull_Up" 0 "No_Request" 11 "Undefined_3" 10 "Undefined_2" 9 "Undefined_1" ;
VAL_TABLE_ EngMde_D_Rq 8 "VSC_Sets_Speed_Type_3" 7 "VSC_Sets_Speed_Type_2" 6 "VSC_Sets_Torque_Type_2" 5 "Dependability_Shutdown" 4 "Dependability_Follow" 3 "Start" 2 "VSC_Sets_Torque_Type_1" 1 "VSC_Sets_Speed_Type_1" 0 "Off" 15 "Undefined_7" 14 "Undefined_6" 13 "Undefined_5" 12 "Undefined_4" 11 "Undefined_3" 10 "Undefined_2" 9 "Undefined_1" ;
VAL_TABLE_ DrvHdcMsg_D_Rq 7 "Undefined" 6 "Speed_too_High" 5 "Temporarily_Unavailable" 4 "System_Fault" 3 "Select_Gear" 2 "Off" 1 "On" 0 "No_Message" ;
VAL_TABLE_ CmbbBrkPrchg_B_Rq 3 "Undefined" 2 "Level_2_PreCharge_Request" 1 "Level_1_PreCharge_Request" 0 "No_PreCharge_Request" ;
VAL_TABLE_ CmbbBaSens_D_Rq 3 "Level_3" 2 "Level_2" 1 "Level_1" 0 "Normal" ;
VAL_TABLE_ CcStat_D_Actl 7 "Undefined_2" 6 "Undefined_1" 5 "Active" 4 "Active_Que_Assist" 3 "Standby" 2 "Standby_Denied" 1 "Denied" 0 "Off" ;
VAL_TABLE_ CadsAudioMute_D_Rq 3 "Reserved" 2 "Partial_Audio_Mute" 1 "Full_Audio_Mute" 0 "No_Audio_Mute" ;
VAL_TABLE_ BpedDrvAppl_D_Actl 3 "_Not_Allowed" 2 "Driver_Braking" 1 "Driver_Not_Braking" 0 "Not_Allowed" ;
VAL_TABLE_ AslIconDsply_D_Rq 3 "On_Passive_Overridden" 2 "On_Active" 1 "On_Passive" 0 "Off" ;
VAL_TABLE_ Unknown_Fault_3E_3F 63 "Fault" 62 "Unknown" ;
VAL_TABLE_ AccWarn_D_Dsply 3 "BrakeReleaseWarn_In_StopMd" 2 "Brake_Capacity_Warning" 1 "Cancel_Warning" 0 "No_Warning" ;
VAL_TABLE_ AccTrgDist2_D_Dsply 15 "DIST_ACTIVE_13_Farthest" 14 "DIST_ACTIVE_12" 13 "DIST_ACTIVE_11" 12 "DIST_ACTIVE_10" 11 "DIST_ACTIVE_9" 10 "DIST_ACTIVE_8" 9 "DIST_ACTIVE_7" 8 "DIST_ACTIVE_6" 7 "DIST_ACTIVE_5" 6 "DIST_ACTIVE_4" 5 "DIST_ACTIVE_3" 4 "DIST_ACTIVE_2" 3 "DIST_ACTIVE_1_Closest" 2 "DIST_ACTIVE_No_Target" 1 "DIST_STANDBY" 0 "DIST_OFF" ;
VAL_TABLE_ AccTGap_D_Dsply 7 "Undefined_2" 6 "Undefined_1" 5 "Time_Gap_5" 4 "Time_Gap_4" 3 "Time_Gap_3" 2 "Time_Gap_2" 1 "Time_Gap_1" 0 "Not_Used" ;
VAL_TABLE_ AccEngStat_D_Actl 7 "Undefined_2" 6 "Undefined_1" 5 "ACCSoonCancel_due_Low_Spd" 4 "Shift_Down_Recommendation" 3 "Shift_Up_Recommendation" 2 "ACCNotAllowedToBeActivated" 1 "ACCStandby_due_Auto_Cancel" 0 "Normal_Operation" ;
VAL_TABLE_ NotPressed_Pressed 1 "Pressed" 0 "Not_Pressed" ;
VAL_TABLE_ TrnGear_D_RqDrv 31 "Fault" 30 "NotUsed_25" 29 "NotUsed_24" 28 "NotUsed_23" 27 "NotUsed_22" 26 "Return_to_Park" 25 "NotUsed_20" 24 "NotUsed_19" 23 "NotUsed_18" 22 "NotUsed_17" 21 "Return_To_Park" 20 "NotUsed_15" 19 "NotUsed_14" 18 "NotUsed_13" 17 "NotUsed_12" 16 "Manual" 15 "Not_Used11" 14 "Not_Used10" 13 "NotUsed_9" 12 "NotUsed_8" 11 "NotUsed_7" 10 "NotUsed_6" 9 "NotUsed_5" 8 "Drive" 7 "NotUsed_4" 6 "NotUsed_3" 5 "NotUsed_2" 4 "Neutral" 3 "NotUsed_1" 2 "Reverse" 1 "Park" 0 "No_Gear" ;
VAL_TABLE_ Open_Close 1 "Close" 0 "Open" ;
VAL_TABLE_ OpenCloseRetainUndef 3 "Undefined" 2 "Retain" 1 "Close" 0 "Open" ;
VAL_TABLE_ DasWarn 3 "Undefined" 2 "Warning_Level_2" 1 "Warning_Level_1" 0 "No_Warning" ;
VAL_TABLE_ DasAlert 5 "Alertness_Level_5" 4 "Alertness_Level_4" 3 "Alertness_Level_3" 2 "Alertness_Level_2" 1 "Alertness_Level_1" 0 "Undefined" ;
VAL_TABLE_ DasStat 3 "Available" 2 "Unavailable_Other" 1 "Feedback_due_to_Speed" 0 "Off" ;
VAL_TABLE_ No_Crank_Req 1 "Crank_Request" 0 "No_Crank_Request" ;
VAL_TABLE_ DrvSlipCtlMde_D_Rq 3 "App_Specific_Off_Mode_3" 2 "App_Specific_Off_Mode_2" 1 "App_Specific_Off_Mode_1" 0 "Default_Mode" ;
VAL_TABLE_ AwdOffRoadMode 3 "Invalid" 2 "Extreme_Off_Road" 1 "Off_Road" 0 "Normal_Mode" ;
VAL_TABLE_ NotQuiet_Quiet 1 "Quiet" 0 "Not_Quiet" ;
VAL_TABLE_ Normal_AdaptiveCruise 1 "Adaptive_Cruise" 0 "Normal_Cruise" ;
VAL_TABLE_ Remote_Device_Feedback 7 "Unused3" 6 "Unused2" 5 "Unused1" 4 "Shutdown" 3 "Running" 2 "Starting" 1 "Acknowledge" 0 "Null" ;
VAL_TABLE_ TrnManShif_D_IndDrv 7 "Undefined_3" 6 "Undefined_2" 5 "Shift_to_Neutral" 4 "Downshift_Recommendation" 3 "Upshift_Warning" 2 "Upshift_Performance" 1 "Upshift_Fuel_Economy" 0 "No_Indication" ;
VAL_TABLE_ Unlock_Lock 1 "Locked" 0 "Unlock" ;
VAL_TABLE_ DieslPrtc_D_RqDsply 7 "Unused_2" 6 "Unused_1" 5 "DPF_SOOT_Level3_Blocked" 4 "DPFSootLvl2_SevereOverload" 3 "DPFRegen_ExhFilterComplete" 2 "DPFRegen_CleanExhFilter" 1 "DPF_Soot_Level1_Overloaded" 0 "DPF_OK_Normal_Operation" ;
VAL_TABLE_ PE_BackupSlot_Status 3 "No_Valid_FOB_In_Slot" 2 "MyKey_FOB_In_Slot" 1 "Standard_FOB_In_Slot" 0 "Null" ;
VAL_TABLE_ Unknown_Fault_FFE_FFF 4095 "Fault" 4094 "Unknown" ;
VAL_TABLE_ Unknown_Fault_1FFE_1FFF 8191 "Fault" 8190 "Unknown" ;
VAL_TABLE_ TrnCnvtClu_D_Actl 3 "Transition_or_Micro_Slip" 2 "Lock_Up_Fixed" 1 "Lock_Up_Slip" 0 "No_Lock_Up" ;
VAL_TABLE_ InhibitNoinhibit 1 "Inhibit" 0 "No_Inibit" ;
VAL_TABLE_ DisableEnable 1 "Enable" 0 "Disable" ;
VAL_TABLE_ Unknown_Fault_7FFE_7FFF 32767 "Fault" 32766 "Unknown" ;
VAL_TABLE_ Side_Detect_Sn_State 3 "Second_Warning_Audio" 2 "System_Failure" 1 "Blocked" 0 "Clear" ;
VAL_TABLE_ Litval_values 255 "Invalid" 254 "Unknown" 5 "Day" 4 "Twilight_4" 3 "Twilight_3" 2 "Twilight_2" 1 "Twilight_1" 0 "Night" ;
VAL_TABLE_ Dimming_Lvl 255 "Invalid" 254 "Unknown" 18 "Day_6" 17 "Day_5" 16 "Day_4" 15 "Day_3" 14 "Day_2" 13 "Day_1" 12 "Night_12" 11 "Night_11" 10 "Night_10" 9 "Night_9" 8 "Night_8" 7 "Night_7" 6 "Night_6" 5 "Night_5" 4 "Night_4" 3 "Night_3" 2 "Night_2" 1 "Night_1" 0 "Off" ;
VAL_TABLE_ EngStrtStop_B_SrcChtLo 1 "Eng_StartStop_for_CHT_Low" 0 "Not_Requested" ;
VAL_TABLE_ EngStrtStop_B_SrcChtHi 1 "Eng_StartStop_for_CHT_Hi" 0 "Not_Requested" ;
VAL_TABLE_ EngDiag_D_RqHtrn 7 "NotUsed4" 6 "NotUsed3" 5 "NotUsed2" 4 "NoUsed1" 3 "Eng_Diag_Cstdn" 2 "Eng_Diag_Run" 1 "Eng_Diag_Crank" 0 "Eng_Diag_Normal" ;
VAL_TABLE_ NotOperating 1 "Operating" 0 "Not_Operating" ;
VAL_TABLE_ CamraStat 3 "FrtCam_TempUnavailOther" 2 "FrtCam_TempUnavailVisibile" 1 "Front_Camera_Service_Reqd" 0 "Front_Camera_OK" ;
VAL_TABLE_ EngPtoMde_D_Actl 7 "Undefined" 6 "Split_Shaft_Stationary" 5 "Not_Used_2" 4 "PTO_Mobile" 3 "Not_Used_1" 2 "PTO_Stationary" 1 "BCP" 0 "Off" ;
VAL_TABLE_ ManRgen_D_Rq 3 "NotUsed2" 2 "NotUsed1" 1 "CustInitManExhFilterClean" 0 "No_Customer_Request" ;
VAL_TABLE_ Remote_Start_Status 3 "Invalid" 2 "Unknown" 1 "Remote" 0 "Null" ;
VAL_TABLE_ Lock_Subld 15 "Unused7" 14 "Unused6" 13 "Unused5" 12 "Unused4" 11 "Unused3" 10 "Unused2" 9 "Unused1" 8 "Customer_8" 7 "Customer_7" 6 "Customer_6" 5 "Customer_5" 4 "Customer_4" 3 "Customer_3" 2 "Customer_2" 1 "Customer_1" 0 "Null" ;
VAL_TABLE_ Brake_Fluid 3 "Invalid" 2 "Unknown" 1 "Low" 0 "OK" ;
VAL_TABLE_ Unknown_Invalid_FE_FF 255 "Invalid" 254 "Unknown" ;
VAL_TABLE_ Invalid_FF 255 "Invalid" ;
VAL_TABLE_ NotLow_Low 1 "Low" 0 "Not_Low" ;
VAL_TABLE_ Disabled_Enabled_Status 2 "Status" 3 "NotUsed" 1 "Enabled" 0 "Disabled" ;
VAL_TABLE_ Key_In_Ignition_Status 1 "In" 0 "Out" ;
VAL_TABLE_ Ignition_Status 0 "Unknown" 1 "Off" 15 "Invalid" 8 "Start" 4 "Run" 2 "Accessory" ;
VAL_TABLE_ Disabled_Enabled_Faulted 3 "Faulted" 2 "Unused" 1 "Enabled" 0 "Disabled" ;
VAL_TABLE_ Disabled_Enabled_NoSupport 2 "Unused" 3 "Not_Supported" 1 "Enabled" 0 "Disabled" ;
VAL_TABLE_ Unknown_Fault_FE_FF 255 "Fault" 254 "Unknown" ;
VAL_TABLE_ Null_Unlock 1 "Unlock" 0 "Null" ;
VAL_TABLE_ Null_Active 1 "Active" 0 "Null" ;
VAL_TABLE_ HsaStat_D_Actl 7 "Faulty" 6 "FaultyWithDriverIndication" 5 "SlowRelease" 4 "FastRelease" 3 "ActiveBrakePedalReleased" 2 "ActiveBrakePedalPressed" 1 "FindingGradient" 0 "Inactive" ;
VAL_TABLE_ Off_Auto_Manual 3 "Undefined" 2 "Manual" 1 "Automatic" 0 "Off" ;
VAL_TABLE_ HsaStat_D_Dsply 7 "NotUsed3" 6 "NotUsed2" 5 "NotUsed1" 4 "NotAvailable" 3 "SlowReleaseWithChime" 2 "SlowReleaseWithoutChime" 1 "Active" 0 "Inactive" ;
VAL_TABLE_ EngMsgTxt_D_Rq 3 "Undefined_2" 2 "Undefined_1" 1 "Power_Reduced_to_LowerTemp" 0 "No_Message" ;
VAL_TABLE_ PassRstrnInd_Req 3 "ABOnNotIllum_OffNotIllum" 2 "AirbagOnNot_Illum_OffIllum" 1 "AirbagOn_Illum_OffNotIllum" 0 "AirbagOn_Illum_Off_Illum" ;
VAL_TABLE_ RearDiffLckMsg_D_Rq 7 "Locker_Disabled" 6 "Locker_Enabled" 5 "Locker_Accel_Pedal" 4 "Speed4" 3 "Speed3" 2 "Spee2" 1 "Speed1" 0 "Normal__No_Message " ;
VAL_TABLE_ GPS_Compass_dirctn 7 "NorthWest" 6 "West" 5 "SouthWest" 4 "South" 3 "SouthEast" 2 "East" 1 "NorthEast" 0 "North" ;
VAL_TABLE_ GPS_Actual_Infer 1 "Inferred_Position" 0 "Actual_Postition" ;
VAL_TABLE_ DrvHdcWarnInfo_D_Rq 3 "Undefined" 2 "Lamp_On_Continuously" 1 "Lamp_Flashing" 0 "Lamp_Off_Continuously" ;
VAL_TABLE_ DieslPrtcRgen_D_Actl 3 "Undefined" 2 "Regen_Level_2" 1 "Regen_Level_1" 0 "No_regen" ;
VAL_TABLE_ Off_On 1 "On" 0 "Off" ;
VAL_TABLE_ CcMde_D_Actl 7 "TapDownWaiting" 6 "TapUpWaiting" 5 "Resuming_Low" 4 "Resuming_High" 3 "Decelerating" 2 "Accelerating" 1 "Keeping_Speed" 0 "Not_Active" ;
VAL_TABLE_ InactiveActive 1 "Active" 0 "Inactive" ;
VAL_TABLE_ ManRgenTxt_D_RqDsply 7 "NotUsed3" 6 "NotUsed2" 5 "NotUsed1" 4 "Cleaning_Aborted_Stopped" 3 "Cleaning_Completed" 2 "Cleaning_In_Progress" 1 "Cleaning_Allowed" 0 "Cleaning_Not_Allowed" ;
VAL_TABLE_ Fault_FFFF 65535 "Fault" ;
VAL_TABLE_ Fault_7F 127 "Fault" ;
VAL_TABLE_ EngOilLvlWarn_D_Rq 7 "Undefined_3" 6 "Undefined_2" 5 "Engine_Oil_Monitor_Fault" 3 "Engine_Oil_High" 2 "Engine_Oil_Critical_Low" 1 "Engine_Oil_Low" 0 "No_Message" 4 "Engine_Oil_Critical_High" ;
VAL_TABLE_ UreaQltySys_D_RqDsply 7 "Undefined" 6 "ZZ_Overrides" 5 "EngineIdled" 4 "Engine_Idle_Upon_Refuel" 3 "SPEED_LIMITED_to_YY_mph" 2 "YY_MPH_MAX_UPON_Restart" 1 "CONTAMINATED_ExhFluid" 0 "NoQualityProblem" ;
VAL_TABLE_ Unknown_Invalid_1E_1F 31 "Invalid" 30 "Unknown" ;
VAL_TABLE_ Unknown_Invalid_3FFE_3FFF 16383 "Invalid" 16382 "Unknown" ;
VAL_TABLE_ NoYes 1 "Yes" 0 "No" ;
VAL_TABLE_ AwdRnge_D_Actl 7 "Unknown" 6 "High_Range_2wd" 5 "High_Range_Auto" 4 "High_Range_Locked" 3 "Neutral" 2 "Low_Range_2wd" 1 "Low_Range_Auto" 0 "Low_Range_Locked" ;
VAL_TABLE_ AwdLck_D_Stat 9 "Undefined" 8 "Under_External_Torque_Ctrl" 7 "Torque_Limited_by_Cmd" 6 "Fully_Locked_by_Cmd" 5 "Disabled" 4 "Warning" 3 "Fault" 2 "Inactive" 1 "Completely_Opened_by_Cmd" 0 "OK" ;
VAL_TABLE_ Unknown_Fault_3FE_3FF 1023 "Fault" 1022 "Unknown" ;
VAL_TABLE_ LockSwStat 3 "Invalid" 2 "Unlock" 1 "Lock" 0 "Null" ;
VAL_TABLE_ Null_Override 1 "Override" 0 "Null" ;
VAL_TABLE_ Off_On_Flash 3 "Not_Used" 2 "Flash" 1 "On" 0 "Off" ;
VAL_TABLE_ immoTargetStatCoding 7 "Unused4" 6 "Unused3" 5 "Unused2" 4 "Unused1" 3 "DISABLED_RESET   " 2 "ENABLED_NONMOTIVE_START" 1 "ENABLED_MOTIVE_START" 0 "DISABLED" ;
VAL_TABLE_ BeltBuckle 3 "Unknown" 2 "Unbelted" 1 "Belted" 0 "Faulty" ;
VAL_TABLE_ RILReqCoding 3 "Not_Used" 2 "Plant_Mode" 1 "On" 0 "Off" ;
VAL_TABLE_ Update_Bit 1 "Fresh_data" 0 "Unchanged_data" ;
VAL_TABLE_ Running_Board 3 "Unused" 2 "Manually_Deployed" 1 "All_Enabled" 0 "All_Disabled" ;
VAL_TABLE_ HudFlashRate 3 "Unused" 2 "Flash_4Hz_50Prct_DutyCycle" 1 "On" 0 "Off" ;
VAL_TABLE_ Turn_Seq 3 "Seq" 2 "On" 1 "Off" 0 "Null" ;
VAL_TABLE_ immoTargetCmdCoding 7 "Unused4" 6 "Unused3" 5 "Unused2" 4 "Unused1" 3 "TARGET1_IDBLOCK2" 2 "TARGET1_IDBLOCK1" 1 "CHALLENGE" 0 "IDLE" ;
VAL_TABLE_ immoSubTargetCmdCoding 7 "Unused3" 6 "Unused2" 5 "ECHO_TARGET1_IDBLOCK2" 4 "Unused1" 3 "RQST_TARGET1_IDBLOCK2" 2 "RQST_TARGET1_IDBLOCK1" 1 "RESPONSE" 0 "IDLE" ;
VAL_TABLE_ immoCtrlCmdCoding 0 "IDLE" 1 "MOTIVE_START_RQST" 2 "NONMOTIVE_START_RQST" 3 "RQST_TARGET1_IDBLOCK1" 4 "RQST_TARGET1_IDBLOCK2" 5 "Unused" 6 "ECHO_TARGET1_IDBLOCK2" 7 "SHUTDOWN" ;
VAL_TABLE_ Rvc_Zoom 7 "Unknown" 6 "Invalid" 5 "Zoom_Level_V" 4 "Zoom_Level_IV" 3 "Zoom_Level_III" 2 "Zoom_Level_II" 1 "Zoom_Level_I" 0 "Off" ;
VAL_TABLE_ NotPark 1 "Park" 0 "Not_Park" ;
VAL_TABLE_ Electric_EOH 1 "Electric_Over_Hydraulic" 0 "Electric" ;
VAL_TABLE_ PersOptIn 1 "OPTED_IN" 0 "NOT_OPTED_IN" ;
VAL_TABLE_ PersonalSetUp 3 "Non_Moveable_Person" 2 "Moveable_Person" 1 "Vehicle" 0 "Factory" ;
VAL_TABLE_ Full_Limited 1 "Limited" 0 "Full" ;
VAL_TABLE_ NoConflict_Conflict 1 "Conflict" 0 "No_Conflict" ;
VAL_TABLE_ Assoc_Confirm 0 "None" 7 "Associate" 6 "Keycode_Rejected" 5 "Keycode_Accepted" 4 "In_Progress" 3 "Erase" 2 "Duplicate" 1 "Disassociate" ;
VAL_TABLE_ Pers1_4 7 "Unused_3" 6 "Unused_2" 5 "Unused_1" 4 "Vehicle" 3 "PERS_4" 2 "PERS_3" 1 "PERS_2" 0 "PERS_1" ;
VAL_TABLE_ Null_Query 7 "Unused_2" 6 "Unused_1" 5 "Copy" 4 "Restore" 3 "Upload" 2 "Set" 1 "Query" 0 "Null" ;
VAL_TABLE_ EngExhBrkMde_D_Actl 6 "ExhBrkDisable_NoError" 5 "ExhBrkActive_AUTO" 4 "ExhBrkActive_ON" 3 "ExhBrkRequest_AUTO" 2 "ExhBrkRequest_ON" 1 "ExhBrkNoRequest_OFF" 0 "ExhBrkUnavailable_Error" ;
VAL_TABLE_ UreaLvlTxt_D_RqDsply 15 "NotUsed_4" 14 "NotUsed_3" 13 "NotUsed_2" 12 "NotUsed_1" 11 "System_Error" 10 "Engine_Idled_See_Manual" 9 "Engine_Idled_Upon_Refuel" 8 "Speed_Limited_To_XX_mph" 7 "XXmph_Max_Upon_Restart" 6 "Speed_Limited_To_YY_mph" 5 "YYmph_Max_Upon_Restart" 4 "SpdLimtd_YYmph_In_XXmiles" 3 "ExFlRange_XXMiles_ScndWarn" 2 "Exh_Fluid_Range_XX_Miles" 1 "Exh_Fluid_Under_Half_Full" 0 "Exh_Fluid_Over_Half_Full" ;
VAL_TABLE_ RearDiffFalt_D_Stat 3 "Diff_Failed_Closed" 2 "Diff_Failed_Open" 1 "Fault_Non_Specific" 0 "No_Fault" ;
VAL_TABLE_ CCOverridden 1 "Cruise_Overridden" 0 "Cruise_Req_Not_Overridden" ;
VAL_TABLE_ Ign_Key_Device_Type 15 "Invalid" 14 "Unknown" 3 "Key_Not_Prgrm_Read_Failure" 2 "Key_In_Ign_My_Key" 1 "Key_In_Ign_Standard_Key" 0 "Key_Read_In_Progress" ;
VAL_TABLE_ Off_No_Eff_Unknown_Invalid 3 "Invalid" 2 "Unknown" 1 "No_Effect" 0 "Off" ;
VAL_TABLE_ Null_Out 1 "Out" 0 "Null" ;
VAL_TABLE_ FUEL_SENSORS 1 "Dual_Sensors" 0 "Single_Sensor" ;

BO_ 140 CruiseCtrl_StrgData2_FD1: 8 GWM
 SG_ DcacPwResetBttn_D_Stat : 36|2@0+ (1,0) [0|3] "SED"  PCM_HEV,PCM

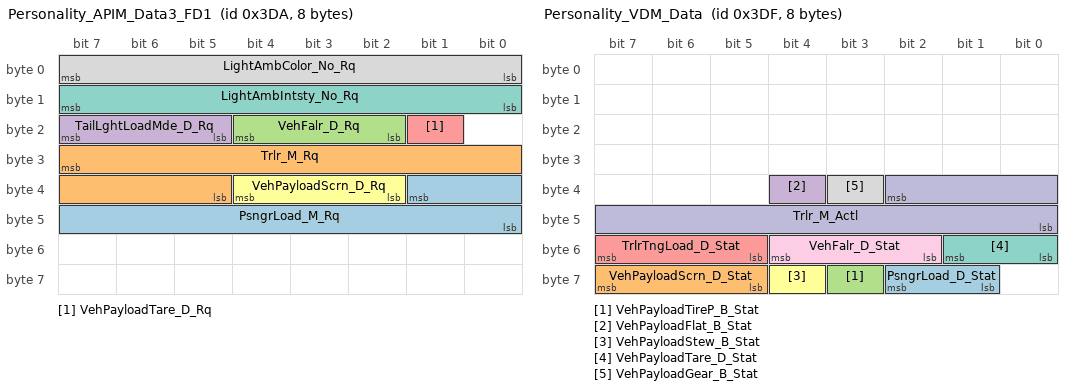
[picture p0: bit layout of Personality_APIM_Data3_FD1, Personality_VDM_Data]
BO_ 986 Personality_APIM_Data3_FD1: 8 GWM
 SG_ PsngrLoad_M_Rq : 33|10@0+ (1,0) [0|1021] "kilogram"  VDM
 SG_ Trlr_M_Rq : 31|11@0+ (10,0) [0|20450] "kilogram"  VDM
 SG_ VehFalr_D_Rq : 20|3@0+ (1,0) [0|7] "SED"  VDM
 SG_ TailLghtLoadMde_D_Rq : 23|3@0+ (1,0) [0|7] "SED" Vector__XXX
 SG_ VehPayloadTare_D_Rq : 17|1@0+ (1,0) [0|1] "SED"  VDM
 SG_ VehPayloadScrn_D_Rq : 36|3@0+ (1,0) [0|7] "SED"  VDM
 SG_ LightAmbIntsty_No_Rq : 15|8@0+ (1,0) [0|255] "unitless" Vector__XXX
 SG_ LightAmbColor_No_Rq : 7|8@0+ (1,0) [0|255] "Discrete" Vector__XXX

BO_ 991 Personality_VDM_Data: 8 VDM
 SG_ PsngrLoad_D_Stat : 58|2@0+ (1,0) [0|3] "SED"  GWM
 SG_ VehPayloadScrn_D_Stat : 63|3@0+ (1,0) [0|7] "SED"  GWM
 SG_ VehPayloadTireP_B_Stat : 59|1@0+ (1,0) [0|1] "SED"  GWM
 SG_ VehPayloadFlat_B_Stat : 36|1@0+ (1,0) [0|1] "SED"  GWM
 SG_ TrlrTngLoad_D_Stat : 55|3@0+ (1,0) [0|7] "SED"  GWM
 SG_ VehPayloadStew_B_Stat : 60|1@0+ (1,0) [0|1] "SED"  GWM
 SG_ VehPayloadTare_D_Stat : 49|2@0+ (1,0) [0|3] "SED"  GWM
 SG_ VehPayloadGear_B_Stat : 35|1@0+ (1,0) [0|1] "SED"  GWM
 SG_ VehFalr_D_Stat : 52|3@0+ (1,0) [0|7] "SED"  GWM
 SG_ Trlr_M_Actl : 34|11@0+ (10,0) [0|20450] "kilogram"  GWM

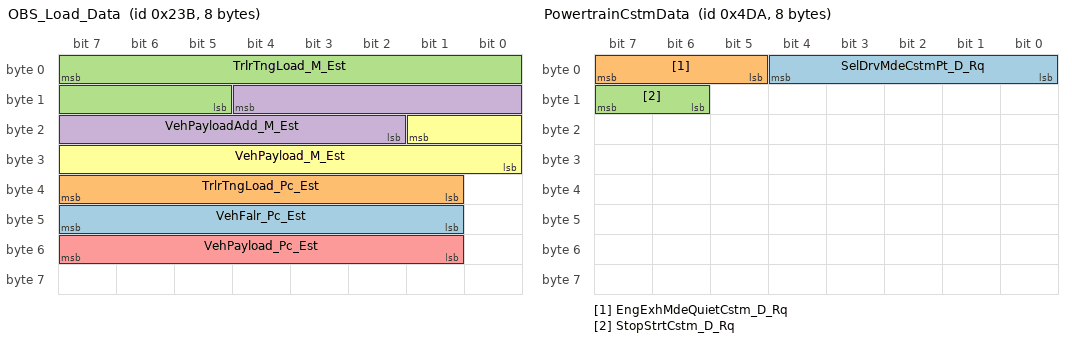
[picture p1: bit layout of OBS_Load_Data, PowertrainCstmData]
BO_ 571 OBS_Load_Data: 8 VDM
 SG_ VehFalr_Pc_Est : 47|7@0+ (1,0) [0|125] "percent"  GWM
 SG_ TrlrTngLoad_Pc_Est : 39|7@0+ (1,0) [0|125] "percent"  GWM
 SG_ TrlrTngLoad_M_Est : 7|11@0+ (10,-10240) [-10240|10210] "kilogram"  GWM
 SG_ VehPayloadAdd_M_Est : 12|11@0+ (5,-5115) [-5115|5110] "kilogram"  GWM
 SG_ VehPayload_Pc_Est : 55|7@0+ (1,0) [0|125] "percent"  GWM
 SG_ VehPayload_M_Est : 17|10@0+ (5,0) [0|5105] "kilogram"  GWM

BO_ 2612224032 PARSEDPushVDMtoGWM_ECG: 8 VDM
 SG_ PARSEDPushVDMtoGWM_ECG : 7|29@0+ (1,0) [0|536870911] "unitless"  GWM

BO_ 2612035800 PARSEDPushFcGWM_ECGtoVDM: 8 GWM
 SG_ PARSEDPushFcGWM_ECGtoVDM : 7|29@0+ (1,0) [0|536870911] "unitless"  VDM

BO_ 2611175456 PARSEDPhysVDMtoGWM_ECG: 64 VDM
 SG_ PARSEDPhysVDMtoGWM_ECG : 7|29@0+ (1,0) [0|536870911] "unitless"  GWM

BO_ 2610987224 PARSEDPhysGWM_ECGtoVDM: 64 GWM
 SG_ PARSEDPhysGWM_ECGtoVDM : 7|29@0+ (1,0) [0|536870911] "unitless"  VDM

BO_ 2610126880 OTAPhysVDMtoGWM_ECG: 64 VDM
 SG_ OTAPhysVDMtoGWM_ECG : 7|29@0+ (1,0) [0|536870911] "unitless"  GWM

BO_ 2609938648 OTAPhysGWM_ECGtoVDM: 64 GWM
 SG_ OTAPhysGWM_ECGtoVDM : 7|29@0+ (1,0) [0|536870911] "unitless"  VDM

BO_ 1242 PowertrainCstmData: 8 GWM
 SG_ SelDrvMdeCstmPt_D_Rq : 4|5@0+ (1,0) [0|31] "SED"  PCM
 SG_ EngExhMdeQuietCstm_D_Rq : 7|3@0+ (1,0) [0|7] "SED"  PCM
 SG_ StopStrtCstm_D_Rq : 15|2@0+ (1,0) [0|3] "SED"  PCM

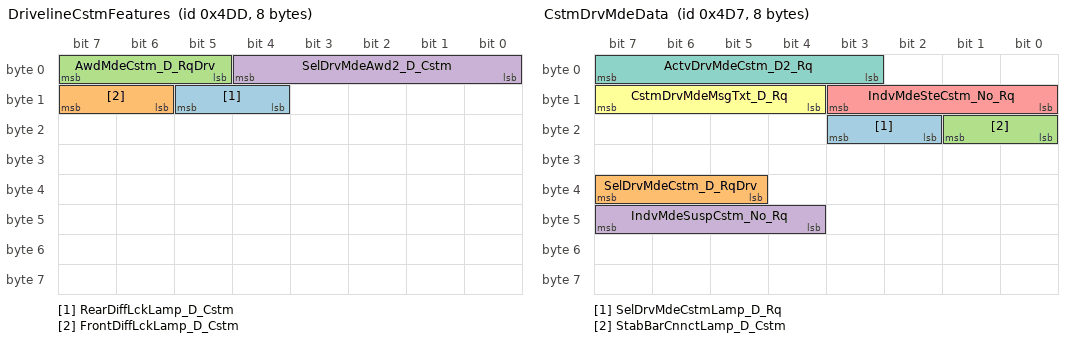
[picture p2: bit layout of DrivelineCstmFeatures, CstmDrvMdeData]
BO_ 1245 DrivelineCstmFeatures: 8 GWM
 SG_ RearDiffLckLamp_D_Cstm : 13|2@0+ (1,0) [0|3] "SED"  TCCM
 SG_ FrontDiffLckLamp_D_Cstm : 15|2@0+ (1,0) [0|3] "SED" Vector__XXX
 SG_ AwdMdeCstm_D_RqDrv : 7|3@0+ (1,0) [0|7] "SED"  TCCM
 SG_ SelDrvMdeAwd2_D_Cstm : 4|5@0+ (1,0) [0|31] "SED"  TCCM

BO_ 1239 CstmDrvMdeData: 8 GWM
 SG_ SelDrvMdeCstmLamp_D_Rq : 19|2@0+ (1,0) [0|3] "SED" Vector__XXX
 SG_ SelDrvMdeCstm_D_RqDrv : 39|3@0+ (1,0) [0|7] "SED"  ABS_ESC,TCCM,PCM
 SG_ StabBarCnnctLamp_D_Cstm : 17|2@0+ (1,0) [0|3] "SED"  ABS_ESC
 SG_ IndvMdeSuspCstm_No_Rq : 47|4@0+ (1,0) [0|15] "unitless"  ABS_ESC
 SG_ IndvMdeSteCstm_No_Rq : 11|4@0+ (1,0) [0|15] "unitless"  ABS_ESC
 SG_ CstmDrvMdeMsgTxt_D_Rq : 15|4@0+ (1,0) [0|15] "SED" Vector__XXX
 SG_ ActvDrvMdeCstm_D2_Rq : 7|5@0+ (1,0) [0|31] "SED"  ABS_ESC

BO_ 1049 APIMSDMsignals_FD1: 8 GWM
 SG_ Fba_D_Rq : 57|2@0+ (1,0) [0|3] "SED" Vector__XXX
 SG_ TurnAsstSwtch_D_Stat : 14|2@0+ (1,0) [0|3] "SED"  ABS_ESC

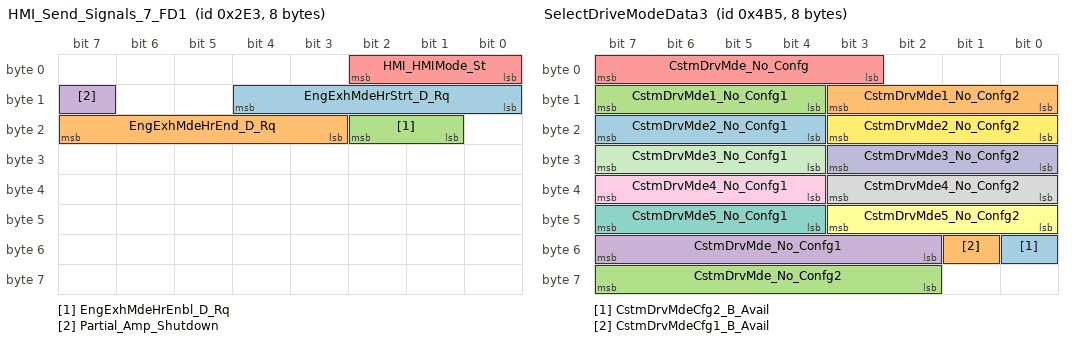
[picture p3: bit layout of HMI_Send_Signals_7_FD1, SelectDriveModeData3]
BO_ 739 HMI_Send_Signals_7_FD1: 8 GWM
 SG_ EngExhMdeHrStrt_D_Rq : 12|5@0+ (1,0) [0|31] "SED"  PCM
 SG_ EngExhMdeHrEnd_D_Rq : 23|5@0+ (1,0) [0|31] "SED"  PCM
 SG_ EngExhMdeHrEnbl_D_Rq : 18|2@0+ (1,0) [0|3] "SED"  PCM
 SG_ Partial_Amp_Shutdown : 15|1@0+ (1,0) [0|1] "SED" Vector__XXX
 SG_ HMI_HMIMode_St : 2|3@0+ (1,0) [0|7] "SED" Vector__XXX

BO_ 1205 SelectDriveModeData3: 8 ABS_ESC
 SG_ CstmDrvMdeCfg2_B_Avail : 48|1@0+ (1,0) [0|1] "SED"  GWM
 SG_ CstmDrvMdeCfg1_B_Avail : 49|1@0+ (1,0) [0|1] "SED"  GWM
 SG_ CstmDrvMde_No_Confg2 : 63|6@0+ (1,0) [0|63] "unitless"  GWM
 SG_ CstmDrvMde_No_Confg1 : 55|6@0+ (1,0) [0|63] "unitless"  GWM
 SG_ CstmDrvMde_No_Confg : 7|5@0+ (1,0) [0|31] "unitless"  GWM
 SG_ CstmDrvMde5_No_Confg2 : 43|4@0+ (1,0) [0|15] "unitless"  GWM
 SG_ CstmDrvMde5_No_Confg1 : 47|4@0+ (1,0) [0|15] "unitless"  GWM
 SG_ CstmDrvMde4_No_Confg2 : 35|4@0+ (1,0) [0|15] "unitless"  GWM
 SG_ CstmDrvMde4_No_Confg1 : 39|4@0+ (1,0) [0|15] "unitless"  GWM
 SG_ CstmDrvMde3_No_Confg2 : 27|4@0+ (1,0) [0|15] "unitless"  GWM
 SG_ CstmDrvMde3_No_Confg1 : 31|4@0+ (1,0) [0|15] "unitless"  GWM
 SG_ CstmDrvMde2_No_Confg2 : 19|4@0+ (1,0) [0|15] "unitless"  GWM
 SG_ CstmDrvMde2_No_Confg1 : 23|4@0+ (1,0) [0|15] "unitless"  GWM
 SG_ CstmDrvMde1_No_Confg2 : 11|4@0+ (1,0) [0|15] "unitless"  GWM
 SG_ CstmDrvMde1_No_Confg1 : 15|4@0+ (1,0) [0|15] "unitless"  GWM

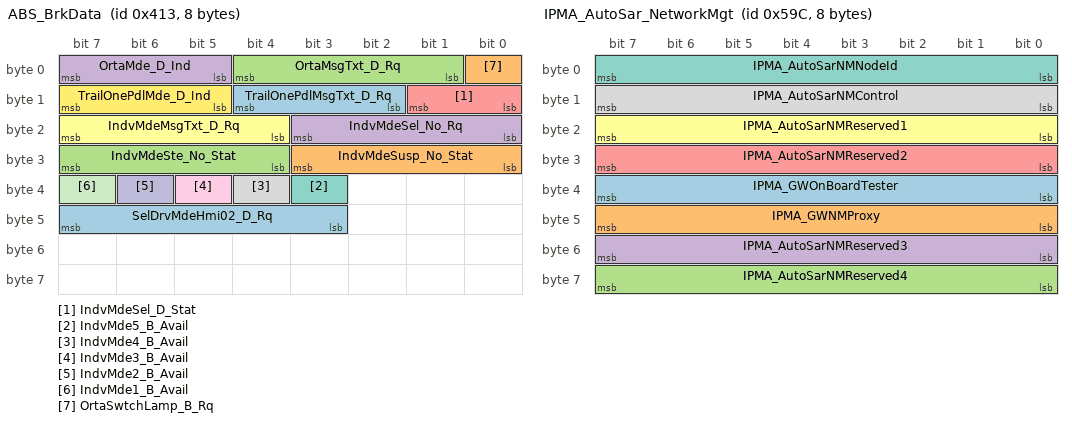
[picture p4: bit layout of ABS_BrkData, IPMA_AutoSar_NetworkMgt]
BO_ 1043 ABS_BrkData: 8 ABS_ESC
 SG_ SelDrvMdeHmi02_D_Rq : 47|5@0+ (1,0) [0|31] "SED"  GWM
 SG_ IndvMdeSusp_No_Stat : 27|4@0+ (1,0) [0|15] "unitless"  GWM
 SG_ IndvMdeSte_No_Stat : 31|4@0+ (1,0) [0|15] "unitless"  GWM
 SG_ IndvMdeSel_No_Rq : 19|4@0+ (1,0) [0|15] "unitless"  GWM
 SG_ IndvMdeSel_D_Stat : 9|2@0+ (1,0) [0|3] "SED"  GWM
 SG_ IndvMdeMsgTxt_D_Rq : 23|4@0+ (1,0) [0|15] "SED"  GWM
 SG_ IndvMde5_B_Avail : 35|1@0+ (1,0) [0|1] "SED"  GWM
 SG_ IndvMde4_B_Avail : 36|1@0+ (1,0) [0|1] "SED"  GWM
 SG_ IndvMde3_B_Avail : 37|1@0+ (1,0) [0|1] "SED"  GWM
 SG_ IndvMde2_B_Avail : 38|1@0+ (1,0) [0|1] "SED"  GWM
 SG_ IndvMde1_B_Avail : 39|1@0+ (1,0) [0|1] "SED"  GWM
 SG_ TrailOnePdlMde_D_Ind : 15|3@0+ (1,0) [0|7] "SED"  GWM
 SG_ TrailOnePdlMsgTxt_D_Rq : 12|3@0+ (1,0) [0|7] "SED"  GWM
 SG_ OrtaSwtchLamp_B_Rq : 0|1@0+ (1,0) [0|1] "SED"  GWM
 SG_ OrtaMsgTxt_D_Rq : 4|4@0+ (1,0) [0|15] "SED"  GWM
 SG_ OrtaMde_D_Ind : 7|3@0+ (1,0) [0|7] "SED"  GWM

BO_ 1436 IPMA_AutoSar_NetworkMgt: 8 IPMA_ADAS
 SG_ IPMA_GWOnBoardTester : 39|8@0+ (1,0) [0|255] "unitless" Vector__XXX
 SG_ IPMA_GWNMProxy : 47|8@0+ (1,0) [0|255] "unitless" Vector__XXX
 SG_ IPMA_AutoSarNMReserved4 : 63|8@0+ (1,0) [0|255] "unitless" Vector__XXX
 SG_ IPMA_AutoSarNMReserved3 : 55|8@0+ (1,0) [0|255] "unitless" Vector__XXX
 SG_ IPMA_AutoSarNMReserved2 : 31|8@0+ (1,0) [0|255] "unitless" Vector__XXX
 SG_ IPMA_AutoSarNMReserved1 : 23|8@0+ (1,0) [0|255] "unitless" Vector__XXX
 SG_ IPMA_AutoSarNMNodeId : 7|8@0+ (1,0) [0|255] "unitless" Vector__XXX
 SG_ IPMA_AutoSarNMControl : 15|8@0+ (1,0) [0|255] "unitless" Vector__XXX

BO_ 2612224099 PARSEDPushSODRtoGWM_ECG: 8 IPMA_ADAS
 SG_ PARSEDPushSODRtoGWM_ECG : 7|29@0+ (1,0) [0|536870911] "unitless"  GWM

BO_ 2612224098 PARSEDPushSODLtoGWM_ECG: 8 IPMA_ADAS
 SG_ PARSEDPushSODLtoGWM_ECG : 7|29@0+ (1,0) [0|536870911] "unitless"  GWM

BO_ 2612224070 PARSEDPushSODCMDtoGWM: 8 IPMA_ADAS
 SG_ PARSEDPushSODCMDtoGWM : 7|29@0+ (1,0) [0|536870911] "unitless"  GWM

BO_ 2612224069 PARSEDPushSODCMCtoGWM: 8 IPMA_ADAS
 SG_ PARSEDPushSODCMCtoGWM : 7|29@0+ (1,0) [0|536870911] "unitless"  GWM

BO_ 2612224033 PARSEDPushIPMAtoGWM_ECG: 8 IPMA_ADAS
 SG_ PARSEDPushIPMAtoGWM_ECG : 7|29@0+ (1,0) [0|536870911] "unitless"  GWM

BO_ 2612224021 PARSEDPushCCMtoGWM_ECG: 8 IPMA_ADAS
 SG_ PARSEDPushCCMtoGWM_ECG : 7|29@0+ (1,0) [0|536870911] "unitless"  GWM

BO_ 2612104408 PARSEDPushFcGWMtoSODR: 8 GWM
 SG_ PARSEDPushFcGWM_ECGtoSODR : 7|29@0+ (1,0) [0|536870911] "unitless"  IPMA_ADAS

BO_ 2612103384 PARSEDPushFcGWMtoSODL: 8 GWM
 SG_ PARSEDPushFcGWM_ECGtoSODL : 7|29@0+ (1,0) [0|536870911] "unitless"  IPMA_ADAS

BO_ 2612074712 PARSEDPushFcGWMtoSODCMD: 8 GWM
 SG_ PARSEDPushFcGWMtoSODCMD : 7|29@0+ (1,0) [0|536870911] "unitless"  IPMA_ADAS

BO_ 2612073688 PARSEDPushFcGWMtoSODCMC: 8 GWM
 SG_ PARSEDPushFcGWMtoSODCMC : 7|29@0+ (1,0) [0|536870911] "unitless"  IPMA_ADAS

BO_ 2612036824 PARSEDPushFcGWM_ECGtoIPMA: 8 GWM
 SG_ PARSEDPushFcGWM_ECGtoIPMA : 7|29@0+ (1,0) [0|536870911] "unitless"  IPMA_ADAS

BO_ 2612024536 PARSEDPushFcGWM_ECGtoCCM: 8 GWM
 SG_ PARSEDPushFcGWM_ECGtoCCM : 7|29@0+ (1,0) [0|536870911] "unitless"  IPMA_ADAS

BO_ 785 Cluster_HEV_Dat7: 8 PCM_HEV
 SG_ EcoIdl_D_Stat : 26|2@0+ (1,0) [0|3] "SED"  GWM

BO_ 1149 Battery_Traction_10_FD1: 8 GWM
 SG_ BattTracPerf_Pc_Actl : 7|8@0+ (1,0) [0|253] "percent"  PCM_HEV

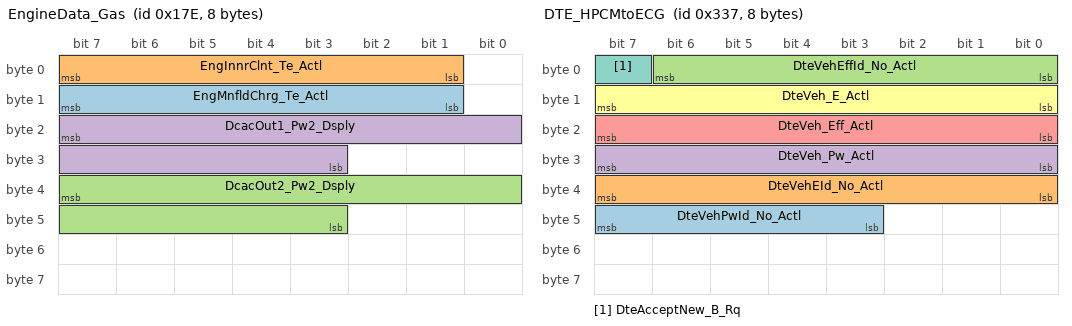
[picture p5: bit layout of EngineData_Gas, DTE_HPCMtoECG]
BO_ 382 EngineData_Gas: 8 PCM_HEV
 SG_ EngMnfldChrg_Te_Actl : 15|7@0+ (1,-20) [-20|105] "degC"  GWM
 SG_ EngInnrClnt_Te_Actl : 7|7@0+ (1,50) [50|175] "degC"  GWM
 SG_ DcacOut2_Pw2_Dsply : 39|13@0+ (1,0) [0|8189] "watts"  GWM
 SG_ DcacOut1_Pw2_Dsply : 23|13@0+ (1,0) [0|8189] "watts"  GWM

BO_ 2612194520 PARSEDPushFcGWM_ECGtoCMR: 8 GWM
 SG_ PARSEDPushFcGWM_ECGtoCMR : 7|29@0+ (1,0) [0|536870911] "unitless"  CMR_DSMC

BO_ 2611145944 PARSEDPhyGWM_ECGtoCMR: 64 GWM
 SG_ PARSEDPhysGWM_ECGtoCMR : 7|29@0+ (1,0) [0|536870911] "unitless"  CMR_DSMC

BO_ 2610097368 OTAPhysGWM_ECGtoCMR: 64 GWM
 SG_ OTAPhysGWM_ECGtoCMR : 7|29@0+ (1,0) [0|536870911] "unitless"  CMR_DSMC

BO_ 2612224187 PARSEDPushFc_CMRtoGWM_ECG: 8 CMR_DSMC
 SG_ PARSEDPushFcCMRtoGWM_ECG : 7|29@0+ (1,0) [0|536870911] "unitless"  GWM

BO_ 2611175611 PARSEDPhysCMRtoGWM_ECG: 64 CMR_DSMC
 SG_ PARSEDPhysCMRtoGWM_ECG : 7|29@0+ (1,0) [0|536870911] "unitless"  GWM

BO_ 2610127035 OTAPhysCMRtoGWM_ECG: 64 CMR_DSMC
 SG_ OTAPhysCMRtoGWM_ECG : 7|29@0+ (1,0) [0|536870911] "unitless"  GWM

BO_ 823 DTE_HPCMtoECG: 8 Vector__XXX
 SG_ DteVehPwId_No_Actl : 47|5@0+ (1,0) [0|31] "unitless"  GWM
 SG_ DteVehEId_No_Actl : 39|8@0+ (1,0) [0|255] "unitless"  GWM
 SG_ DteVehEffId_No_Actl : 6|7@0+ (1,0) [0|127] "unitless"  GWM
 SG_ DteVeh_Pw_Actl : 31|8@0+ (50,0) [0|12750] "watts"  GWM
 SG_ DteVeh_Eff_Actl : 23|8@0+ (10,-1000) [-1000|1550] "watt*hour/km"  GWM
 SG_ DteVeh_E_Actl : 15|8@0+ (100,0) [0|25500] "watt*hour"  GWM
 SG_ DteAcceptNew_B_Rq : 7|1@0+ (1,0) [0|1] "SED"  GWM

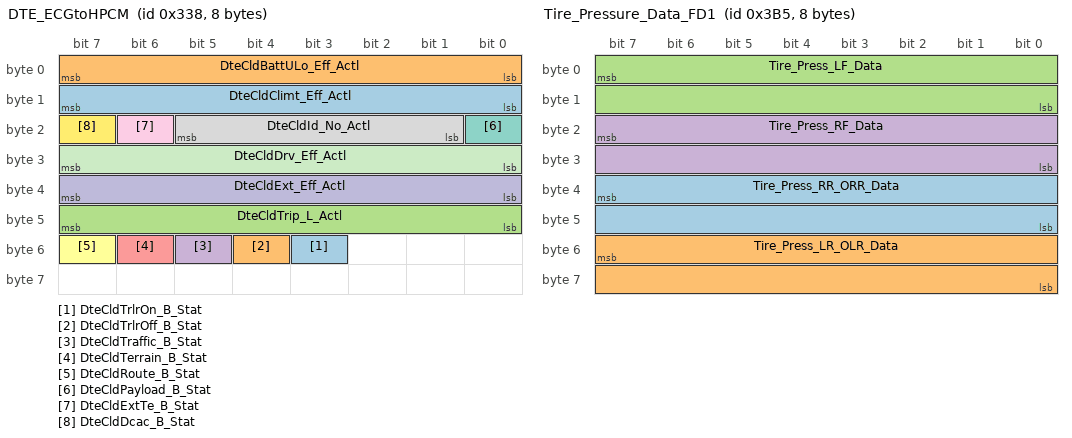
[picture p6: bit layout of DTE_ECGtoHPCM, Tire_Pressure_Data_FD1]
BO_ 824 DTE_ECGtoHPCM: 8 GWM
 SG_ DteCldTrlrOn_B_Stat : 51|1@0+ (1,0) [0|1] "SED" Vector__XXX
 SG_ DteCldTrlrOff_B_Stat : 52|1@0+ (1,0) [0|1] "SED" Vector__XXX
 SG_ DteCldTrip_L_Actl : 47|8@0+ (10,-1000) [-1000|1550] "watt*hour/km" Vector__XXX
 SG_ DteCldTraffic_B_Stat : 53|1@0+ (1,0) [0|1] "SED" Vector__XXX
 SG_ DteCldTerrain_B_Stat : 54|1@0+ (1,0) [0|1] "SED" Vector__XXX
 SG_ DteCldRoute_B_Stat : 55|1@0+ (1,0) [0|1] "SED" Vector__XXX
 SG_ DteCldPayload_B_Stat : 16|1@0+ (1,0) [0|1] "SED" Vector__XXX
 SG_ DteCldId_No_Actl : 21|5@0+ (1,0) [0|31] "unitless" Vector__XXX
 SG_ DteCldExtTe_B_Stat : 22|1@0+ (1,0) [0|1] "SED" Vector__XXX
 SG_ DteCldExt_Eff_Actl : 39|8@0+ (10,-1000) [-1000|1550] "watt*hour/km" Vector__XXX
 SG_ DteCldDrv_Eff_Actl : 31|8@0+ (10,-1000) [-1000|1550] "watt*hour/km" Vector__XXX
 SG_ DteCldDcac_B_Stat : 23|1@0+ (1,0) [0|1] "SED" Vector__XXX
 SG_ DteCldClimt_Eff_Actl : 15|8@0+ (10,-1000) [-1000|1550] "watt*hour/km" Vector__XXX
 SG_ DteCldBattULo_Eff_Actl : 7|8@0+ (10,-1000) [-1000|1550] "watt*hour/km" Vector__XXX

BO_ 949 Tire_Pressure_Data_FD1: 8 GWM
 SG_ Tire_Press_RR_ORR_Data : 39|16@0+ (1,0) [0|65533] "kilopascal"  VDM
 SG_ Tire_Press_LR_OLR_Data : 55|16@0+ (1,0) [0|65533] "kilopascal"  VDM
 SG_ Tire_Press_LF_Data : 7|16@0+ (1,0) [0|65533] "kilopascal"  VDM
 SG_ Tire_Press_RF_Data : 23|16@0+ (1,0) [0|65533] "kilopascal"  VDM

BO_ 1825 TesterPhysicalReqVDM_FD1: 64 GWM
 SG_ TesterPhysicalReqVDM : 7|64@0+ (1,0) [0|1.84467E+019] "unitless"  VDM

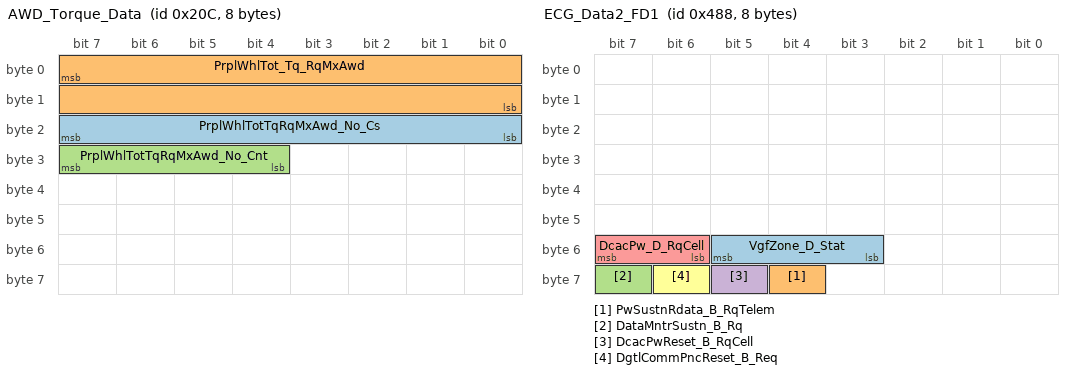
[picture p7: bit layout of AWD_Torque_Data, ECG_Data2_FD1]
BO_ 524 AWD_Torque_Data: 8 TCCM
 SG_ PrplWhlTotTqRqMxAwd_No_Cs : 23|8@0+ (1,0) [0|255] "Unitless"  PCM_HEV,PCM,ECM_Diesel
 SG_ PrplWhlTot_Tq_RqMxAwd : 7|16@0+ (4,-131072) [-131072|131068] "Nm"  PCM_HEV,PCM,ECM_Diesel
 SG_ PrplWhlTotTqRqMxAwd_No_Cnt : 31|4@0+ (1,0) [0|15] "Unitless"  PCM_HEV,PCM,ECM_Diesel

BO_ 740 PHEV_Battery_Data1_FD1: 8 GWM
 SG_ BattAuxCnnct_B_Cmd : 53|1@0+ (1,0) [0|1] "SED"  SOBDMC_HPCM_FD1

BO_ 1160 ECG_Data2_FD1: 8 GWM
 SG_ VgfZone_D_Stat : 53|3@0+ (1,0) [0|7] "SED"  PCM,PCM_HEV
 SG_ PwSustnRdata_B_RqTelem : 60|1@0+ (1,0) [0|1] "SED" Vector__XXX
 SG_ DataMntrSustn_B_Rq : 63|1@0+ (1,0) [0|1] "SED" Vector__XXX
 SG_ DcacPwReset_B_RqCell : 61|1@0+ (1,0) [0|1] "SED"  PCM_HEV,PCM
 SG_ DcacPw_D_RqCell : 55|2@0+ (1,0) [0|3] "SED"  PCM_HEV,PCM
 SG_ DgtlCommPncReset_B_Req : 62|1@0+ (1,0) [0|1] "SED" Vector__XXX

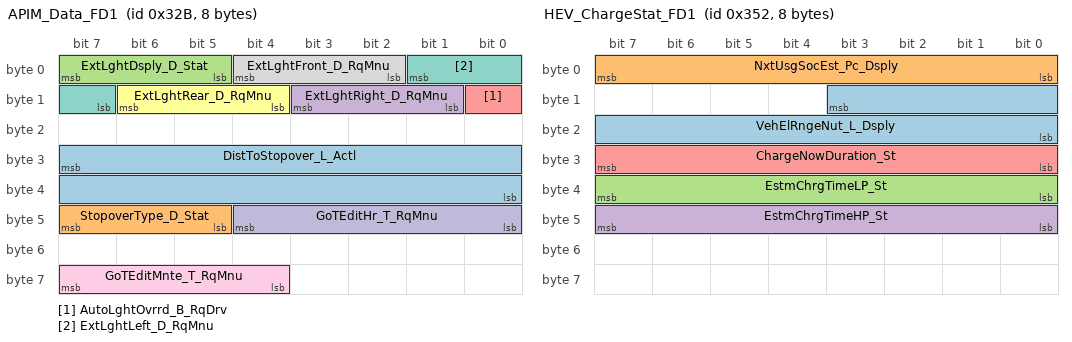
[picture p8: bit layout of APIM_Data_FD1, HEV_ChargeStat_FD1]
BO_ 811 APIM_Data_FD1: 8 GWM
 SG_ DistToStopover_L_Actl : 31|16@0+ (0.1,0) [0|6553.4] "kilometer" Vector__XXX
 SG_ StopoverType_D_Stat : 47|3@0+ (1,0) [0|0] "SED" Vector__XXX
 SG_ ExtLghtDsply_D_Stat : 7|3@0+ (1,0) [0|7] "SED" Vector__XXX
 SG_ ExtLghtRight_D_RqMnu : 11|3@0+ (1,0) [0|7] "SED" Vector__XXX
 SG_ AutoLghtOvrrd_B_RqDrv : 8|1@0+ (1,0) [0|1] "SED" Vector__XXX
 SG_ ExtLghtRear_D_RqMnu : 14|3@0+ (1,0) [0|7] "SED" Vector__XXX
 SG_ ExtLghtLeft_D_RqMnu : 1|3@0+ (1,0) [0|7] "SED" Vector__XXX
 SG_ ExtLghtFront_D_RqMnu : 4|3@0+ (1,0) [0|7] "SED" Vector__XXX
 SG_ GoTEditMnte_T_RqMnu : 63|4@0+ (1,0) [0|15] "SED" Vector__XXX
 SG_ GoTEditHr_T_RqMnu : 44|5@0+ (1,0) [0|29] "SED" Vector__XXX

BO_ 850 HEV_ChargeStat_FD1: 8 SOBDMC_HPCM_FD1
 SG_ VehElRngeNut_L_Dsply : 11|12@0+ (0.1,0) [0|409.3] "km"  GWM
 SG_ NxtUsgSocEst_Pc_Dsply : 7|8@0+ (0.5,0) [0|126.5] "unitless"  GWM
 SG_ EstmChrgTimeLP_St : 39|8@0+ (0.1,0) [0|25.4] "hour"  GWM
 SG_ EstmChrgTimeHP_St : 47|8@0+ (0.1,0) [0|25.4] "hour"  GWM
 SG_ ChargeNowDuration_St : 31|8@0+ (0.1,0) [0|25.4] "hour"  GWM

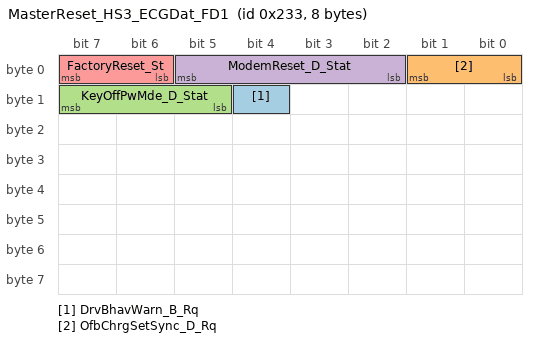
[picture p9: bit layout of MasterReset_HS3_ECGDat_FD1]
BO_ 563 MasterReset_HS3_ECGDat_FD1: 8 GWM
 SG_ DrvBhavWarn_B_Rq : 12|1@0+ (1,0) [0|1] "SED" Vector__XXX
 SG_ OfbChrgSetSync_D_Rq : 1|2@0+ (1,0) [0|3] "SED" Vector__XXX
 SG_ KeyOffPwMde_D_Stat : 15|3@0+ (1,0) [0|7] "SED" Vector__XXX
 SG_ ModemReset_D_Stat : 5|4@0+ (1,0) [0|15] "SED" Vector__XXX
 SG_ FactoryReset_St : 7|2@0+ (1,0) [0|3] "SED" Vector__XXX

BO_ 1833 TesterPhysicalResVDM: 64 VDM
 SG_ TesterPhysicalResVDM : 7|64@0+ (1,0) [0|1.84467E+019] "unitless"  TSTR

BO_TX_BU_ 382 : PCM,PCM_HEV;

CM_ "New CAN FD network";
CM_ BU_ CMR_DSMC "Driver Status Monitor Camera";
CM_ BU_ IPMA_ADAS "Assist Driving Alert System";
CM_ BU_ PSCM "Passenger Front Climate Control Seat Module";
CM_ BU_ ABS_ESC "Anti-lock Brake / Traction Control Module";
CM_ BU_ TCCM "Transfer Case Control Module, 4x4 Control Module";
CM_ BU_ TCM_DSL "Transmission Control Module";
CM_ BU_ PCM "Powertrain Control Module";
CM_ BU_ ECM_Diesel "Diesel";
CM_ BU_ GWM "Gateway Module CGEA1.3(Star Architecture)";
CM_ BU_ TSTR "Diagnostic Tester";
CM_ BO_ 986 "APIM Tx";
CM_ BO_ 739 "FCDIM Tx";
CM_ SG_ 739 Partial_Amp_Shutdown "Method Partial_Amp_Shutdown";
CM_ SG_ 739 HMI_HMIMode_St "Object ACU System Master.HMIMode
OR
Object NAV System Master.HMIMode

Refer Method HMIAudioMode in the SPSS";
CM_ BO_ 382 "ECM, PCM Gas Only msg";
CM_ BO_ 949 "For 2010MY and beyond, use for SCT (non-CGEA) and CGEA modules";
CM_ BO_ 524 "Requires b/w evaluation on each program for faster rate, requires Core Netcom and Netcom App. for approval.";
CM_ SG_ 524 PrplWhlTotTqRqMxAwd_No_Cs "Signal not transmitted on gas variants.";
CM_ SG_ 524 PrplWhlTotTqRqMxAwd_No_Cnt "Signal not transmitted on gas variants.";
BA_DEF_ SG_  "U_CD542_MY2021_Rx" ENUM  "No","Yes";
BA_DEF_ SG_  "U_CD542_MY2021_Tx" ENUM  "No","Yes";
BA_DEF_ SG_  "U_U55X_MY2022_Tx" ENUM  "No","Yes";
BA_DEF_ BO_  "OvtpPushApplication" ENUM  "FALSE","TRUE";
BA_DEF_ BU_  "OvtpOperationMode" ENUM  "SERVER","CLIENT";
BA_DEF_ BU_  "OvtpEcuAddress" INT 0 1022;
BA_DEF_ SG_  "ECGUsedRxSignal" ENUM  "No","Yes";
BA_DEF_ SG_  "ECGUsedTxSignal" ENUM  "No","Yes";
BA_DEF_ BO_  "VFrameFormat" ENUM  "StandardCAN","ExtendedCAN","reserved","reserved","reserved","reserved","reserved","reserved","reserved","reserved","reserved","reserved","reserved","reserved","StandardCAN_FD","ExtendedCAN_FD";
BA_DEF_  "BusType" STRING ;
BA_DEF_ BO_  "FrameRouting" STRING ;
BA_DEF_ BO_  "FrameGatewayNetwork" STRING ;
BA_DEF_ BO_  "NetworkInitialization" ENUM  "No","Yes";
BA_DEF_ BO_  "FrameGatewayId" HEX 0 1407;
BA_DEF_ BO_  "EventRateOfChange" INT 10 10000;
BA_DEF_ BO_  "GenMsgStartDelayTime" INT 0 10000;
BA_DEF_ BO_  "GenMsgNrOfRepetition" INT 0 100;
BA_DEF_ BO_  "GenMsgDelayTime" INT 0 1000;
BA_DEF_ BO_  "GenMsgCycleTime" INT 0 100000;
BA_DEF_ BO_  "GenMsgSendType" ENUM  "FixedPeriodic","Event","EnabledPeriodic","NotUsed","NotUsed","EventPeriodic","NotUsed","NotUsed","NoMsgSendType";
BA_DEF_ SG_  "U_T6_MCA_MY2020_Tx" ENUM  "No","Yes";
BA_DEF_ SG_  "U_P702_MY2021_Tx" ENUM  "No","Yes";
BA_DEF_ SG_  "U_CX727_MY2021_Tx" ENUM  "No","Yes";
BA_DEF_ SG_  "U_T6_MCA_MY2020_Rx" ENUM  "No","Yes";
BA_DEF_ SG_  "U_P702_MY2021_Rx" ENUM  "No","Yes";
BA_DEF_ SG_  "U_CX727_MY2021_Rx" ENUM  "No","Yes";
BA_DEF_ SG_  "GenSigStartValue" HEX 0 268435455;
BA_DEF_ SG_  "MetaData" ENUM  "No","Yes";
BA_DEF_ SG_  "ContentDependant" ENUM  "No","Yes";
BA_DEF_ SG_  "GenSigStartValueInteger" INT 0 1000000000;
BA_DEF_ SG_  "UsedOnPgmDBC" ENUM  "No","Yes";
BA_DEF_ SG_  "CrossOver_InfoCAN" ENUM  "No","Yes";
BA_DEF_ SG_  "WakeupSignal" ENUM  "No","Yes";
BA_DEF_ SG_  "GenSigInactiveValue" INT 0 100000;
BA_DEF_ SG_  "GenSigSendType" ENUM  "Cyclic","OnWrite","vector_leerstring","OnChange","vector_leerstring","IfActive","vector_leerstring","NoSigSendType";
BA_DEF_ BO_  "SCP_FreshnessValueLength" INT 0 512;
BA_DEF_ BO_  "AuthFreshnessCounterSyncAttempt" INT 0 512;
BA_DEF_ BO_  "SCP_FreshnessValueTxLength" INT 0 512;
BA_DEF_ BO_  "SCP_AuthInfoTxLength" INT 0 512;
BA_DEF_ BO_  "ProgBWConditional" STRING ;
BA_DEF_ BO_  "NmAsrMessage" ENUM  "No","Yes";
BA_DEF_ BO_  "TpApplType" STRING ;
BA_DEF_ BO_  "DiagState" ENUM  "No","Yes";
BA_DEF_ BO_  "TpTxIndex" INT 0 536870911;
BA_DEF_ BO_  "DiagRequest" ENUM  "No","Yes";
BA_DEF_ BO_  "DiagResponse" ENUM  "No","Yes";
BA_DEF_ BO_  "GenMsgILSupport" ENUM  "No","Yes";
BA_DEF_ BU_  "Terminator" ENUM  "No","Yes";
BA_DEF_ BU_  "NodeWakeUpTime" INT 0 10000;
BA_DEF_ BU_  "NodeStartUpTime" INT 0 10000;
BA_DEF_ BU_  "NmAsrNodeIdentifier" HEX 128 255;
BA_DEF_ BU_  "NmAsrNode" ENUM  "No","Yes";
BA_DEF_ BU_  "PowerType" ENUM  "Switched","Latched","Sleep","vector_leerstring","vector_leerstring";
BA_DEF_ BU_  "DiagNode" ENUM  "GGDS","GDS","NONE";
BA_DEF_ BU_  "EOL_SB_Flash" ENUM  "GGDS","GDS","NONE","vector_leerstring";
BA_DEF_ BU_  "NmStationAddress" INT 0 255;
BA_DEF_ BU_  "ILUsed" ENUM  "No","Yes";
BA_DEF_ BU_  "NosPackage" ENUM  "None","I3_1","I3_2","1.0.1","RP","EuCD","Volcano","I3_3","FNOS_Autosar";
BA_DEF_ BU_  "PackageID" STRING ;
BA_DEF_ BU_  "GatewayECU" ENUM  "No","Yes";
BA_DEF_  "NetworkSpeed" ENUM  "500kBits/s","125kBit/s";
BA_DEF_  "VersionNumber" INT 0 10000;
BA_DEF_  "StarNetworkGwType" ENUM  "0=NotDefined","1=HS1","2=HS2","3=HS3","4=HS4","5=HS5","6=MS1","7=HS6","8=HS7","9=MS2","10=FD1","11=FD2","12=FD3","13=FD4","14=FD5","15=FD6","16=FD7","17=FD8";
BA_DEF_  "CMDB_Version" STRING ;
BA_DEF_  "NmType" STRING ;
BA_DEF_  "NmAsrMessageCount" INT 128 128;
BA_DEF_  "NmAsrBaseAddress" HEX 1408 1408;
BA_DEF_  "DBName" STRING ;
BA_DEF_  "VersionDay" INT 1 31;
BA_DEF_  "Manufacturer" STRING ;
BA_DEF_  "VersionMonth" INT 1 12;
BA_DEF_  "VersionYear" INT 2000 3000;
BA_DEF_  "NmBaseAddress" HEX 1280 1280;
BA_DEF_  "NmMessageCount" INT 0 128;
BA_DEF_DEF_  "U_CD542_MY2021_Rx" "No";
BA_DEF_DEF_  "U_CD542_MY2021_Tx" "No";
BA_DEF_DEF_  "U_U55X_MY2022_Tx" "No";
BA_DEF_DEF_  "OvtpPushApplication" "FALSE";
BA_DEF_DEF_  "OvtpOperationMode" "SERVER";
BA_DEF_DEF_  "OvtpEcuAddress" 0;
BA_DEF_DEF_  "ECGUsedRxSignal" "No";
BA_DEF_DEF_  "ECGUsedTxSignal" "No";
BA_DEF_DEF_  "VFrameFormat" "ExtendedCAN_FD";
BA_DEF_DEF_  "BusType" "";
BA_DEF_DEF_  "FrameRouting" "NONE";
BA_DEF_DEF_  "FrameGatewayNetwork" "NONE";
BA_DEF_DEF_  "NetworkInitialization" "Yes";
BA_DEF_DEF_  "FrameGatewayId" 0;
BA_DEF_DEF_  "EventRateOfChange" 10000;
BA_DEF_DEF_  "GenMsgStartDelayTime" 0;
BA_DEF_DEF_  "GenMsgNrOfRepetition" 1;
BA_DEF_DEF_  "GenMsgDelayTime" 20;
BA_DEF_DEF_  "GenMsgCycleTime" 0;
BA_DEF_DEF_  "GenMsgSendType" "NoMsgSendType";
BA_DEF_DEF_  "U_T6_MCA_MY2020_Tx" "No";
BA_DEF_DEF_  "U_P702_MY2021_Tx" "No";
BA_DEF_DEF_  "U_CX727_MY2021_Tx" "No";
BA_DEF_DEF_  "U_T6_MCA_MY2020_Rx" "No";
BA_DEF_DEF_  "U_P702_MY2021_Rx" "No";
BA_DEF_DEF_  "U_CX727_MY2021_Rx" "No";
BA_DEF_DEF_  "GenSigStartValue" 0;
BA_DEF_DEF_  "MetaData" "No";
BA_DEF_DEF_  "ContentDependant" "No";
BA_DEF_DEF_  "GenSigStartValueInteger" 0;
BA_DEF_DEF_  "UsedOnPgmDBC" "Yes";
BA_DEF_DEF_  "CrossOver_InfoCAN" "No";
BA_DEF_DEF_  "WakeupSignal" "No";
BA_DEF_DEF_  "GenSigInactiveValue" 0;
BA_DEF_DEF_  "GenSigSendType" "NoSigSendType";
BA_DEF_DEF_  "SCP_FreshnessValueLength" 64;
BA_DEF_DEF_  "AuthFreshnessCounterSyncAttempt" 2;
BA_DEF_DEF_  "SCP_FreshnessValueTxLength" 11;
BA_DEF_DEF_  "SCP_AuthInfoTxLength" 53;
BA_DEF_DEF_  "ProgBWConditional" "NONE";
BA_DEF_DEF_  "NmAsrMessage" "No";
BA_DEF_DEF_  "TpApplType" "";
BA_DEF_DEF_  "DiagState" "No";
BA_DEF_DEF_  "TpTxIndex" 0;
BA_DEF_DEF_  "DiagRequest" "No";
BA_DEF_DEF_  "DiagResponse" "No";
BA_DEF_DEF_  "GenMsgILSupport" "Yes";
BA_DEF_DEF_  "Terminator" "No";
BA_DEF_DEF_  "NodeWakeUpTime" 10;
BA_DEF_DEF_  "NodeStartUpTime" 250;
BA_DEF_DEF_  "NmAsrNodeIdentifier" 128;
BA_DEF_DEF_  "NmAsrNode" "No";
BA_DEF_DEF_  "PowerType" "Switched";
BA_DEF_DEF_  "DiagNode" "GGDS";
BA_DEF_DEF_  "EOL_SB_Flash" "GGDS";
BA_DEF_DEF_  "NmStationAddress" 0;
BA_DEF_DEF_  "ILUsed" "Yes";
BA_DEF_DEF_  "NosPackage" "I3_3";
BA_DEF_DEF_  "PackageID" "08.05.00.00.71.xx.xx.rr.00.00";
BA_DEF_DEF_  "GatewayECU" "No";
BA_DEF_DEF_  "NetworkSpeed" "500kBits/s";
BA_DEF_DEF_  "VersionNumber" 1;
BA_DEF_DEF_  "StarNetworkGwType" "0=NotDefined";
BA_DEF_DEF_  "CMDB_Version" "v11.01";
BA_DEF_DEF_  "NmType" "Ford-OSEK";
BA_DEF_DEF_  "NmAsrMessageCount" 128;
BA_DEF_DEF_  "NmAsrBaseAddress" 1408;
BA_DEF_DEF_  "DBName" "";
BA_DEF_DEF_  "VersionDay" 1;
BA_DEF_DEF_  "Manufacturer" "Ford";
BA_DEF_DEF_  "VersionMonth" 1;
BA_DEF_DEF_  "VersionYear" 2011;
BA_DEF_DEF_  "NmBaseAddress" 1280;
BA_DEF_DEF_  "NmMessageCount" 128;
BA_ "VersionMonth" 8;
BA_ "VersionDay" 31;
BA_ "VersionNumber" 26;
BA_ "StarNetworkGwType" 10;
BA_ "CMDB_Version" "FNV2_v18.07";
BA_ "VersionYear" 2021;
BA_ "BusType" "CAN FD";
BA_ "DBName" "FD1_CAN";
BA_ "OvtpEcuAddress" BU_ VDM 32;
BA_ "NmStationAddress" BU_ VDM 48;
BA_ "NmAsrNodeIdentifier" BU_ CMR_DSMC 223;
BA_ "NmAsrNode" BU_ CMR_DSMC 1;
BA_ "PowerType" BU_ CMR_DSMC 2;
BA_ "NmStationAddress" BU_ CMR_DSMC 95;
BA_ "OvtpEcuAddress" BU_ CMR_DSMC 187;
BA_ "NmStationAddress" BU_ SOBDMC_HPCM_FD1 37;
BA_ "OvtpEcuAddress" BU_ SOBDMC_HPCM_FD1 17;
BA_ "NodeStartUpTime" BU_ IPMA_ADAS 300;
BA_ "NmStationAddress" BU_ IPMA_ADAS 28;
BA_ "OvtpEcuAddress" BU_ IPMA_ADAS 33;
BA_ "Terminator" BU_ PSCM 1;
BA_ "NmAsrNodeIdentifier" BU_ PSCM 181;
BA_ "NmAsrNode" BU_ PSCM 1;
BA_ "PowerType" BU_ PSCM 1;
BA_ "NmStationAddress" BU_ PSCM 53;
BA_ "OvtpEcuAddress" BU_ PSCM 48;
BA_ "NodeWakeUpTime" BU_ ABS_ESC 300;
BA_ "NodeStartUpTime" BU_ ABS_ESC 1000;
BA_ "NmAsrNodeIdentifier" BU_ ABS_ESC 150;
BA_ "NmAsrNode" BU_ ABS_ESC 1;
BA_ "PowerType" BU_ ABS_ESC 2;
BA_ "NmStationAddress" BU_ ABS_ESC 22;
BA_ "OvtpEcuAddress" BU_ ABS_ESC 40;
BA_ "NodeWakeUpTime" BU_ TCCM 25;
BA_ "NodeStartUpTime" BU_ TCCM 1000;
BA_ "NmAsrNodeIdentifier" BU_ TCCM 161;
BA_ "NmAsrNode" BU_ TCCM 1;
BA_ "NmStationAddress" BU_ TCCM 33;
BA_ "OvtpEcuAddress" BU_ TCCM 25;
BA_ "NosPackage" BU_ TCM_DSL 4;
BA_ "NodeWakeUpTime" BU_ TCM_DSL 200;
BA_ "NmAsrNodeIdentifier" BU_ TCM_DSL 160;
BA_ "NmAsrNode" BU_ TCM_DSL 1;
BA_ "PowerType" BU_ TCM_DSL 1;
BA_ "NmStationAddress" BU_ TCM_DSL 32;
BA_ "OvtpEcuAddress" BU_ TCM_DSL 24;
BA_ "NodeStartUpTime" BU_ PCM_HEV 350;
BA_ "NmAsrNodeIdentifier" BU_ PCM_HEV 149;
BA_ "NmAsrNode" BU_ PCM_HEV 1;
BA_ "PowerType" BU_ PCM_HEV 1;
BA_ "NmStationAddress" BU_ PCM_HEV 21;
BA_ "OvtpEcuAddress" BU_ PCM_HEV 16;
BA_ "NodeStartUpTime" BU_ PCM 350;
BA_ "NmAsrNodeIdentifier" BU_ PCM 149;
BA_ "NmAsrNode" BU_ PCM 1;
BA_ "PowerType" BU_ PCM 1;
BA_ "NmStationAddress" BU_ PCM 21;
BA_ "OvtpEcuAddress" BU_ PCM 16;
BA_ "NmAsrNodeIdentifier" BU_ ECM_Diesel 149;
BA_ "NmAsrNode" BU_ ECM_Diesel 1;
BA_ "PowerType" BU_ ECM_Diesel 1;
BA_ "NmStationAddress" BU_ ECM_Diesel 21;
BA_ "OvtpEcuAddress" BU_ ECM_Diesel 16;
BA_ "NodeWakeUpTime" BU_ GWM 100;
BA_ "PackageID" BU_ GWM "08.05.00.00.71.00.00.00.00.00";
BA_ "NosPackage" BU_ GWM 4;
BA_ "GatewayECU" BU_ GWM 1;
BA_ "Terminator" BU_ GWM 1;
BA_ "NodeStartUpTime" BU_ GWM 100;
BA_ "NmAsrNodeIdentifier" BU_ GWM 158;
BA_ "NmAsrNode" BU_ GWM 1;
BA_ "PowerType" BU_ GWM 2;
BA_ "NmStationAddress" BU_ GWM 30;
BA_ "OvtpOperationMode" BU_ GWM 1;
BA_ "OvtpEcuAddress" BU_ GWM 216;
BA_ "FrameRouting" BO_ 140 "";
BA_ "FrameGatewayNetwork" BO_ 140 "HS3_CAN";
BA_ "FrameGatewayId" BO_ 140 140;
BA_ "VFrameFormat" BO_ 140 14;
BA_ "FrameRouting" BO_ 986 "";
BA_ "FrameGatewayNetwork" BO_ 986 "HS3_CAN";
BA_ "FrameGatewayId" BO_ 986 986;
BA_ "VFrameFormat" BO_ 986 14;
BA_ "GenMsgCycleTime" BO_ 991 1000;
BA_ "GenMsgSendType" BO_ 991 5;
BA_ "VFrameFormat" BO_ 991 14;
BA_ "GenMsgCycleTime" BO_ 571 150;
BA_ "GenMsgSendType" BO_ 571 0;
BA_ "VFrameFormat" BO_ 571 14;
BA_ "NetworkInitialization" BO_ 2612224032 0;
BA_ "GenMsgDelayTime" BO_ 2612224032 0;
BA_ "GenMsgSendType" BO_ 2612224032 1;
BA_ "OvtpPushApplication" BO_ 2612224032 1;
BA_ "TpTxIndex" BO_ 2612224032 464552152;
BA_ "NetworkInitialization" BO_ 2612035800 0;
BA_ "GenMsgDelayTime" BO_ 2612035800 0;
BA_ "GenMsgSendType" BO_ 2612035800 1;
BA_ "OvtpPushApplication" BO_ 2612035800 1;
BA_ "TpTxIndex" BO_ 2612035800 464552152;
BA_ "NetworkInitialization" BO_ 2611175456 0;
BA_ "GenMsgDelayTime" BO_ 2611175456 0;
BA_ "GenMsgSendType" BO_ 2611175456 1;
BA_ "TpTxIndex" BO_ 2611175456 463503576;
BA_ "NetworkInitialization" BO_ 2610987224 0;
BA_ "GenMsgDelayTime" BO_ 2610987224 0;
BA_ "GenMsgSendType" BO_ 2610987224 1;
BA_ "TpTxIndex" BO_ 2610987224 463503576;
BA_ "NetworkInitialization" BO_ 2610126880 0;
BA_ "GenMsgDelayTime" BO_ 2610126880 0;
BA_ "GenMsgSendType" BO_ 2610126880 1;
BA_ "TpTxIndex" BO_ 2610126880 462455000;
BA_ "NetworkInitialization" BO_ 2609938648 0;
BA_ "GenMsgDelayTime" BO_ 2609938648 0;
BA_ "GenMsgSendType" BO_ 2609938648 1;
BA_ "TpTxIndex" BO_ 2609938648 462455000;
BA_ "GenMsgCycleTime" BO_ 1242 1000;
BA_ "GenMsgSendType" BO_ 1242 5;
BA_ "VFrameFormat" BO_ 1242 14;
BA_ "GenMsgCycleTime" BO_ 1245 1000;
BA_ "GenMsgSendType" BO_ 1245 5;
BA_ "VFrameFormat" BO_ 1245 14;
BA_ "GenMsgCycleTime" BO_ 1239 1000;
BA_ "GenMsgSendType" BO_ 1239 5;
BA_ "VFrameFormat" BO_ 1239 14;
BA_ "FrameGatewayId" BO_ 1049 1049;
BA_ "FrameGatewayNetwork" BO_ 1049 "HS3_CAN";
BA_ "FrameRouting" BO_ 1049 "";
BA_ "VFrameFormat" BO_ 1049 14;
BA_ "FrameGatewayId" BO_ 739 739;
BA_ "FrameGatewayNetwork" BO_ 739 "HS3_CAN";
BA_ "FrameRouting" BO_ 739 "";
BA_ "VFrameFormat" BO_ 739 14;
BA_ "GenMsgStartDelayTime" BO_ 1205 1130;
BA_ "GenMsgCycleTime" BO_ 1205 100000;
BA_ "GenMsgSendType" BO_ 1205 5;
BA_ "VFrameFormat" BO_ 1205 14;
BA_ "GenMsgCycleTime" BO_ 1043 1000;
BA_ "GenMsgSendType" BO_ 1043 5;
BA_ "VFrameFormat" BO_ 1043 14;
BA_ "GenMsgILSupport" BO_ 1436 0;
BA_ "NmAsrMessage" BO_ 1436 1;
BA_ "GenMsgSendType" BO_ 1436 0;
BA_ "GenMsgCycleTime" BO_ 1436 1000;
BA_ "VFrameFormat" BO_ 1436 14;
BA_ "TpTxIndex" BO_ 2612224099 464620760;
BA_ "OvtpPushApplication" BO_ 2612224099 1;
BA_ "GenMsgSendType" BO_ 2612224099 1;
BA_ "GenMsgDelayTime" BO_ 2612224099 0;
BA_ "NetworkInitialization" BO_ 2612224099 0;
BA_ "TpTxIndex" BO_ 2612224098 464619736;
BA_ "OvtpPushApplication" BO_ 2612224098 1;
BA_ "GenMsgSendType" BO_ 2612224098 1;
BA_ "GenMsgDelayTime" BO_ 2612224098 0;
BA_ "NetworkInitialization" BO_ 2612224098 0;
BA_ "TpTxIndex" BO_ 2612224070 464591064;
BA_ "OvtpPushApplication" BO_ 2612224070 1;
BA_ "GenMsgSendType" BO_ 2612224070 1;
BA_ "GenMsgDelayTime" BO_ 2612224070 0;
BA_ "NetworkInitialization" BO_ 2612224070 0;
BA_ "TpTxIndex" BO_ 2612224069 464590040;
BA_ "OvtpPushApplication" BO_ 2612224069 1;
BA_ "GenMsgSendType" BO_ 2612224069 1;
BA_ "GenMsgDelayTime" BO_ 2612224069 0;
BA_ "NetworkInitialization" BO_ 2612224069 0;
BA_ "TpTxIndex" BO_ 2612224033 464553176;
BA_ "OvtpPushApplication" BO_ 2612224033 1;
BA_ "GenMsgSendType" BO_ 2612224033 1;
BA_ "GenMsgDelayTime" BO_ 2612224033 0;
BA_ "NetworkInitialization" BO_ 2612224033 0;
BA_ "TpTxIndex" BO_ 2612224021 464540888;
BA_ "OvtpPushApplication" BO_ 2612224021 1;
BA_ "GenMsgSendType" BO_ 2612224021 1;
BA_ "GenMsgDelayTime" BO_ 2612224021 0;
BA_ "NetworkInitialization" BO_ 2612224021 0;
BA_ "TpTxIndex" BO_ 2612104408 464620760;
BA_ "OvtpPushApplication" BO_ 2612104408 1;
BA_ "GenMsgSendType" BO_ 2612104408 1;
BA_ "GenMsgDelayTime" BO_ 2612104408 0;
BA_ "NetworkInitialization" BO_ 2612104408 0;
BA_ "TpTxIndex" BO_ 2612103384 464619736;
BA_ "OvtpPushApplication" BO_ 2612103384 1;
BA_ "GenMsgSendType" BO_ 2612103384 1;
BA_ "GenMsgDelayTime" BO_ 2612103384 0;
BA_ "NetworkInitialization" BO_ 2612103384 0;
BA_ "TpTxIndex" BO_ 2612074712 464591064;
BA_ "OvtpPushApplication" BO_ 2612074712 1;
BA_ "GenMsgSendType" BO_ 2612074712 1;
BA_ "GenMsgDelayTime" BO_ 2612074712 0;
BA_ "NetworkInitialization" BO_ 2612074712 0;
BA_ "TpTxIndex" BO_ 2612073688 464590040;
BA_ "OvtpPushApplication" BO_ 2612073688 1;
BA_ "GenMsgSendType" BO_ 2612073688 1;
BA_ "GenMsgDelayTime" BO_ 2612073688 0;
BA_ "NetworkInitialization" BO_ 2612073688 0;
BA_ "TpTxIndex" BO_ 2612036824 464553176;
BA_ "OvtpPushApplication" BO_ 2612036824 1;
BA_ "GenMsgSendType" BO_ 2612036824 1;
BA_ "GenMsgDelayTime" BO_ 2612036824 0;
BA_ "NetworkInitialization" BO_ 2612036824 0;
BA_ "TpTxIndex" BO_ 2612024536 464540888;
BA_ "OvtpPushApplication" BO_ 2612024536 1;
BA_ "GenMsgSendType" BO_ 2612024536 1;
BA_ "GenMsgDelayTime" BO_ 2612024536 0;
BA_ "NetworkInitialization" BO_ 2612024536 0;
BA_ "GenMsgCycleTime" BO_ 785 1000;
BA_ "GenMsgSendType" BO_ 785 5;
BA_ "VFrameFormat" BO_ 785 14;
BA_ "FrameGatewayId" BO_ 1149 1149;
BA_ "FrameGatewayNetwork" BO_ 1149 "HS1_CAN";
BA_ "FrameRouting" BO_ 1149 "";
BA_ "VFrameFormat" BO_ 1149 14;
BA_ "GenMsgCycleTime" BO_ 382 1000;
BA_ "GenMsgSendType" BO_ 382 0;
BA_ "VFrameFormat" BO_ 382 14;
BA_ "NetworkInitialization" BO_ 2612194520 0;
BA_ "GenMsgDelayTime" BO_ 2612194520 0;
BA_ "GenMsgSendType" BO_ 2612194520 1;
BA_ "OvtpPushApplication" BO_ 2612194520 1;
BA_ "TpTxIndex" BO_ 2612194520 464710872;
BA_ "NetworkInitialization" BO_ 2611145944 0;
BA_ "GenMsgDelayTime" BO_ 2611145944 0;
BA_ "GenMsgSendType" BO_ 2611145944 1;
BA_ "TpTxIndex" BO_ 2611145944 463662296;
BA_ "NetworkInitialization" BO_ 2610097368 0;
BA_ "GenMsgDelayTime" BO_ 2610097368 0;
BA_ "GenMsgSendType" BO_ 2610097368 1;
BA_ "TpTxIndex" BO_ 2610097368 462613720;
BA_ "NetworkInitialization" BO_ 2612224187 0;
BA_ "GenMsgDelayTime" BO_ 2612224187 0;
BA_ "GenMsgSendType" BO_ 2612224187 1;
BA_ "TpTxIndex" BO_ 2612224187 464710872;
BA_ "NetworkInitialization" BO_ 2611175611 0;
BA_ "GenMsgDelayTime" BO_ 2611175611 0;
BA_ "GenMsgSendType" BO_ 2611175611 1;
BA_ "TpTxIndex" BO_ 2611175611 463662296;
BA_ "NetworkInitialization" BO_ 2610127035 0;
BA_ "GenMsgDelayTime" BO_ 2610127035 0;
BA_ "GenMsgSendType" BO_ 2610127035 1;
BA_ "TpTxIndex" BO_ 2610127035 462613720;
BA_ "GenMsgCycleTime" BO_ 823 1000;
BA_ "GenMsgSendType" BO_ 823 5;
BA_ "VFrameFormat" BO_ 823 14;
BA_ "GenMsgCycleTime" BO_ 824 1000;
BA_ "GenMsgSendType" BO_ 824 5;
BA_ "VFrameFormat" BO_ 824 14;
BA_ "FrameRouting" BO_ 949 "";
BA_ "FrameGatewayNetwork" BO_ 949 "HS1_CAN";
BA_ "FrameGatewayId" BO_ 949 949;
BA_ "VFrameFormat" BO_ 949 14;
BA_ "NetworkInitialization" BO_ 1825 0;
BA_ "GenMsgDelayTime" BO_ 1825 0;
BA_ "GenMsgSendType" BO_ 1825 1;
BA_ "DiagRequest" BO_ 1825 1;
BA_ "GenMsgILSupport" BO_ 1825 0;
BA_ "VFrameFormat" BO_ 1825 14;
BA_ "ProgBWConditional" BO_ 524 "MSGDCR1008_CX48X_V03_HS1D_56.84_mHEV_54.89";
BA_ "GenMsgSendType" BO_ 524 0;
BA_ "GenMsgCycleTime" BO_ 524 10;
BA_ "GenMsgDelayTime" BO_ 524 0;
BA_ "VFrameFormat" BO_ 524 14;
BA_ "FrameGatewayId" BO_ 740 740;
BA_ "FrameGatewayNetwork" BO_ 740 "HS1_CAN";
BA_ "FrameRouting" BO_ 740 "";
BA_ "VFrameFormat" BO_ 740 14;
BA_ "GenMsgSendType" BO_ 1160 5;
BA_ "GenMsgCycleTime" BO_ 1160 1000;
BA_ "VFrameFormat" BO_ 1160 14;
BA_ "FrameRouting" BO_ 811 "";
BA_ "FrameGatewayNetwork" BO_ 811 "HS3_CAN";
BA_ "FrameGatewayId" BO_ 811 811;
BA_ "VFrameFormat" BO_ 811 14;
BA_ "GenMsgCycleTime" BO_ 850 150;
BA_ "GenMsgSendType" BO_ 850 0;
BA_ "VFrameFormat" BO_ 850 14;
BA_ "GenMsgSendType" BO_ 563 5;
BA_ "GenMsgCycleTime" BO_ 563 1000;
BA_ "VFrameFormat" BO_ 563 14;
BA_ "NetworkInitialization" BO_ 1833 0;
BA_ "GenMsgDelayTime" BO_ 1833 0;
BA_ "GenMsgSendType" BO_ 1833 1;
BA_ "DiagResponse" BO_ 1833 1;
BA_ "GenMsgILSupport" BO_ 1833 0;
BA_ "VFrameFormat" BO_ 1833 14;
BA_ "GenSigStartValue" SG_ 986 PsngrLoad_M_Rq 1022;
BA_ "GenSigStartValue" SG_ 986 Trlr_M_Rq 2046;
BA_ "GenSigSendType" SG_ 991 PsngrLoad_D_Stat 3;
BA_ "GenSigSendType" SG_ 991 VehPayloadScrn_D_Stat 3;
BA_ "GenSigSendType" SG_ 991 VehPayloadTireP_B_Stat 3;
BA_ "GenSigSendType" SG_ 991 VehPayloadFlat_B_Stat 3;
BA_ "GenSigStartValue" SG_ 991 TrlrTngLoad_D_Stat 6;
BA_ "GenSigSendType" SG_ 991 TrlrTngLoad_D_Stat 3;
BA_ "GenSigSendType" SG_ 991 VehPayloadStew_B_Stat 3;
BA_ "GenSigSendType" SG_ 991 VehPayloadTare_D_Stat 3;
BA_ "GenSigSendType" SG_ 991 VehPayloadGear_B_Stat 3;
BA_ "GenSigSendType" SG_ 991 VehFalr_D_Stat 3;
BA_ "GenSigStartValue" SG_ 991 Trlr_M_Actl 2046;
BA_ "GenSigSendType" SG_ 991 Trlr_M_Actl 3;
BA_ "GenSigStartValue" SG_ 571 VehFalr_Pc_Est 126;
BA_ "GenSigStartValue" SG_ 571 TrlrTngLoad_Pc_Est 126;
BA_ "GenSigStartValue" SG_ 571 TrlrTngLoad_M_Est 2046;
BA_ "GenSigStartValue" SG_ 571 VehPayloadAdd_M_Est 2046;
BA_ "GenSigStartValue" SG_ 571 VehPayload_Pc_Est 126;
BA_ "GenSigStartValue" SG_ 571 VehPayload_M_Est 1022;
BA_ "U_T6_MCA_MY2020_Tx" SG_ 2612224032 PARSEDPushVDMtoGWM_ECG 1;
BA_ "U_CD542_MY2021_Rx" SG_ 2612224032 PARSEDPushVDMtoGWM_ECG 1;
BA_ "ECGUsedRxSignal" SG_ 2612224032 PARSEDPushVDMtoGWM_ECG 1;
BA_ "GenSigSendType" SG_ 2612224032 PARSEDPushVDMtoGWM_ECG 3;
BA_ "U_CD542_MY2021_Tx" SG_ 2612035800 PARSEDPushFcGWM_ECGtoVDM 1;
BA_ "ECGUsedTxSignal" SG_ 2612035800 PARSEDPushFcGWM_ECGtoVDM 1;
BA_ "U_T6_MCA_MY2020_Rx" SG_ 2612035800 PARSEDPushFcGWM_ECGtoVDM 1;
BA_ "GenSigSendType" SG_ 2612035800 PARSEDPushFcGWM_ECGtoVDM 3;
BA_ "U_T6_MCA_MY2020_Tx" SG_ 2611175456 PARSEDPhysVDMtoGWM_ECG 1;
BA_ "U_CD542_MY2021_Rx" SG_ 2611175456 PARSEDPhysVDMtoGWM_ECG 1;
BA_ "ECGUsedRxSignal" SG_ 2611175456 PARSEDPhysVDMtoGWM_ECG 1;
BA_ "GenSigSendType" SG_ 2611175456 PARSEDPhysVDMtoGWM_ECG 3;
BA_ "U_CD542_MY2021_Tx" SG_ 2610987224 PARSEDPhysGWM_ECGtoVDM 1;
BA_ "ECGUsedTxSignal" SG_ 2610987224 PARSEDPhysGWM_ECGtoVDM 1;
BA_ "U_T6_MCA_MY2020_Rx" SG_ 2610987224 PARSEDPhysGWM_ECGtoVDM 1;
BA_ "GenSigSendType" SG_ 2610987224 PARSEDPhysGWM_ECGtoVDM 3;
BA_ "U_T6_MCA_MY2020_Tx" SG_ 2610126880 OTAPhysVDMtoGWM_ECG 1;
BA_ "U_CD542_MY2021_Rx" SG_ 2610126880 OTAPhysVDMtoGWM_ECG 1;
BA_ "ECGUsedRxSignal" SG_ 2610126880 OTAPhysVDMtoGWM_ECG 1;
BA_ "GenSigSendType" SG_ 2610126880 OTAPhysVDMtoGWM_ECG 3;
BA_ "U_CD542_MY2021_Tx" SG_ 2609938648 OTAPhysGWM_ECGtoVDM 1;
BA_ "ECGUsedTxSignal" SG_ 2609938648 OTAPhysGWM_ECGtoVDM 1;
BA_ "U_T6_MCA_MY2020_Rx" SG_ 2609938648 OTAPhysGWM_ECGtoVDM 1;
BA_ "GenSigSendType" SG_ 2609938648 OTAPhysGWM_ECGtoVDM 3;
BA_ "ECGUsedTxSignal" SG_ 1242 SelDrvMdeCstmPt_D_Rq 1;
BA_ "GenSigSendType" SG_ 1242 SelDrvMdeCstmPt_D_Rq 3;
BA_ "ECGUsedTxSignal" SG_ 1242 EngExhMdeQuietCstm_D_Rq 1;
BA_ "GenSigSendType" SG_ 1242 EngExhMdeQuietCstm_D_Rq 3;
BA_ "ECGUsedTxSignal" SG_ 1242 StopStrtCstm_D_Rq 1;
BA_ "GenSigSendType" SG_ 1242 StopStrtCstm_D_Rq 3;
BA_ "ECGUsedTxSignal" SG_ 1245 RearDiffLckLamp_D_Cstm 1;
BA_ "GenSigSendType" SG_ 1245 RearDiffLckLamp_D_Cstm 3;
BA_ "ECGUsedTxSignal" SG_ 1245 FrontDiffLckLamp_D_Cstm 1;
BA_ "GenSigSendType" SG_ 1245 FrontDiffLckLamp_D_Cstm 3;
BA_ "ECGUsedTxSignal" SG_ 1245 AwdMdeCstm_D_RqDrv 1;
BA_ "GenSigStartValueInteger" SG_ 1245 AwdMdeCstm_D_RqDrv 5;
BA_ "GenSigSendType" SG_ 1245 AwdMdeCstm_D_RqDrv 3;
BA_ "ECGUsedTxSignal" SG_ 1245 SelDrvMdeAwd2_D_Cstm 1;
BA_ "GenSigStartValue" SG_ 1245 SelDrvMdeAwd2_D_Cstm 31;
BA_ "GenSigStartValueInteger" SG_ 1245 SelDrvMdeAwd2_D_Cstm 31;
BA_ "GenSigSendType" SG_ 1245 SelDrvMdeAwd2_D_Cstm 3;
BA_ "U_CD542_MY2021_Tx" SG_ 1239 SelDrvMdeCstmLamp_D_Rq 1;
BA_ "ECGUsedTxSignal" SG_ 1239 SelDrvMdeCstmLamp_D_Rq 1;
BA_ "GenSigSendType" SG_ 1239 SelDrvMdeCstmLamp_D_Rq 3;
BA_ "U_CD542_MY2021_Tx" SG_ 1239 SelDrvMdeCstm_D_RqDrv 1;
BA_ "ECGUsedTxSignal" SG_ 1239 SelDrvMdeCstm_D_RqDrv 1;
BA_ "GenSigSendType" SG_ 1239 SelDrvMdeCstm_D_RqDrv 3;
BA_ "U_CD542_MY2021_Tx" SG_ 1239 StabBarCnnctLamp_D_Cstm 1;
BA_ "ECGUsedTxSignal" SG_ 1239 StabBarCnnctLamp_D_Cstm 1;
BA_ "GenSigSendType" SG_ 1239 StabBarCnnctLamp_D_Cstm 3;
BA_ "U_CD542_MY2021_Tx" SG_ 1239 IndvMdeSuspCstm_No_Rq 1;
BA_ "ECGUsedTxSignal" SG_ 1239 IndvMdeSuspCstm_No_Rq 1;
BA_ "GenSigStartValue" SG_ 1239 IndvMdeSuspCstm_No_Rq 15;
BA_ "GenSigSendType" SG_ 1239 IndvMdeSuspCstm_No_Rq 3;
BA_ "U_CD542_MY2021_Tx" SG_ 1239 IndvMdeSteCstm_No_Rq 1;
BA_ "ECGUsedTxSignal" SG_ 1239 IndvMdeSteCstm_No_Rq 1;
BA_ "GenSigStartValue" SG_ 1239 IndvMdeSteCstm_No_Rq 15;
BA_ "GenSigSendType" SG_ 1239 IndvMdeSteCstm_No_Rq 3;
BA_ "U_CD542_MY2021_Tx" SG_ 1239 CstmDrvMdeMsgTxt_D_Rq 1;
BA_ "ECGUsedTxSignal" SG_ 1239 CstmDrvMdeMsgTxt_D_Rq 1;
BA_ "GenSigSendType" SG_ 1239 CstmDrvMdeMsgTxt_D_Rq 3;
BA_ "U_CD542_MY2021_Tx" SG_ 1239 ActvDrvMdeCstm_D2_Rq 1;
BA_ "ECGUsedTxSignal" SG_ 1239 ActvDrvMdeCstm_D2_Rq 1;
BA_ "GenSigStartValue" SG_ 1239 ActvDrvMdeCstm_D2_Rq 31;
BA_ "GenSigSendType" SG_ 1239 ActvDrvMdeCstm_D2_Rq 3;
BA_ "WakeupSignal" SG_ 739 HMI_HMIMode_St 1;
BA_ "GenSigSendType" SG_ 1205 CstmDrvMdeCfg2_B_Avail 3;
BA_ "GenSigSendType" SG_ 1205 CstmDrvMdeCfg1_B_Avail 3;
BA_ "GenSigStartValue" SG_ 1205 CstmDrvMde_No_Confg2 63;
BA_ "GenSigSendType" SG_ 1205 CstmDrvMde_No_Confg2 3;
BA_ "GenSigStartValue" SG_ 1205 CstmDrvMde_No_Confg1 63;
BA_ "GenSigSendType" SG_ 1205 CstmDrvMde_No_Confg1 3;
BA_ "GenSigSendType" SG_ 1205 CstmDrvMde_No_Confg 3;
BA_ "GenSigStartValue" SG_ 1205 CstmDrvMde5_No_Confg2 15;
BA_ "GenSigSendType" SG_ 1205 CstmDrvMde5_No_Confg2 3;
BA_ "GenSigStartValue" SG_ 1205 CstmDrvMde5_No_Confg1 15;
BA_ "GenSigSendType" SG_ 1205 CstmDrvMde5_No_Confg1 3;
BA_ "GenSigStartValue" SG_ 1205 CstmDrvMde4_No_Confg2 15;
BA_ "GenSigSendType" SG_ 1205 CstmDrvMde4_No_Confg2 3;
BA_ "GenSigStartValue" SG_ 1205 CstmDrvMde4_No_Confg1 15;
BA_ "GenSigSendType" SG_ 1205 CstmDrvMde4_No_Confg1 3;
BA_ "GenSigStartValue" SG_ 1205 CstmDrvMde3_No_Confg2 15;
BA_ "GenSigSendType" SG_ 1205 CstmDrvMde3_No_Confg2 3;
BA_ "GenSigStartValue" SG_ 1205 CstmDrvMde3_No_Confg1 15;
BA_ "GenSigSendType" SG_ 1205 CstmDrvMde3_No_Confg1 3;
BA_ "GenSigStartValue" SG_ 1205 CstmDrvMde2_No_Confg2 15;
BA_ "GenSigSendType" SG_ 1205 CstmDrvMde2_No_Confg2 3;
BA_ "GenSigStartValue" SG_ 1205 CstmDrvMde2_No_Confg1 15;
BA_ "GenSigSendType" SG_ 1205 CstmDrvMde2_No_Confg1 3;
BA_ "GenSigStartValue" SG_ 1205 CstmDrvMde1_No_Confg2 15;
BA_ "GenSigSendType" SG_ 1205 CstmDrvMde1_No_Confg2 3;
BA_ "GenSigStartValue" SG_ 1205 CstmDrvMde1_No_Confg1 15;
BA_ "GenSigSendType" SG_ 1205 CstmDrvMde1_No_Confg1 3;
BA_ "GenSigSendType" SG_ 1043 SelDrvMdeHmi02_D_Rq 3;
BA_ "GenSigStartValue" SG_ 1043 IndvMdeSusp_No_Stat 15;
BA_ "GenSigSendType" SG_ 1043 IndvMdeSusp_No_Stat 3;
BA_ "GenSigStartValue" SG_ 1043 IndvMdeSte_No_Stat 15;
BA_ "GenSigSendType" SG_ 1043 IndvMdeSte_No_Stat 3;
BA_ "GenSigStartValue" SG_ 1043 IndvMdeSel_No_Rq 15;
BA_ "GenSigSendType" SG_ 1043 IndvMdeSel_No_Rq 3;
BA_ "GenSigSendType" SG_ 1043 IndvMdeSel_D_Stat 3;
BA_ "GenSigSendType" SG_ 1043 IndvMdeMsgTxt_D_Rq 3;
BA_ "GenSigSendType" SG_ 1043 IndvMde5_B_Avail 3;
BA_ "GenSigSendType" SG_ 1043 IndvMde4_B_Avail 3;
BA_ "GenSigSendType" SG_ 1043 IndvMde3_B_Avail 3;
BA_ "GenSigSendType" SG_ 1043 IndvMde2_B_Avail 3;
BA_ "GenSigSendType" SG_ 1043 IndvMde1_B_Avail 3;
BA_ "U_T6_MCA_MY2020_Tx" SG_ 1043 TrailOnePdlMde_D_Ind 1;
BA_ "GenSigSendType" SG_ 1043 TrailOnePdlMde_D_Ind 3;
BA_ "U_T6_MCA_MY2020_Tx" SG_ 1043 TrailOnePdlMsgTxt_D_Rq 1;
BA_ "GenSigSendType" SG_ 1043 TrailOnePdlMsgTxt_D_Rq 3;
BA_ "U_U55X_MY2022_Tx" SG_ 1043 OrtaSwtchLamp_B_Rq 1;
BA_ "U_T6_MCA_MY2020_Tx" SG_ 1043 OrtaSwtchLamp_B_Rq 1;
BA_ "U_T6_MCA_MY2020_Rx" SG_ 1043 OrtaSwtchLamp_B_Rq 1;
BA_ "GenSigSendType" SG_ 1043 OrtaSwtchLamp_B_Rq 3;
BA_ "U_U55X_MY2022_Tx" SG_ 1043 OrtaMsgTxt_D_Rq 1;
BA_ "U_T6_MCA_MY2020_Tx" SG_ 1043 OrtaMsgTxt_D_Rq 1;
BA_ "GenSigSendType" SG_ 1043 OrtaMsgTxt_D_Rq 3;
BA_ "U_U55X_MY2022_Tx" SG_ 1043 OrtaMde_D_Ind 1;
BA_ "U_T6_MCA_MY2020_Tx" SG_ 1043 OrtaMde_D_Ind 1;
BA_ "GenSigSendType" SG_ 1043 OrtaMde_D_Ind 3;
BA_ "GenSigStartValueInteger" SG_ 1436 IPMA_GWOnBoardTester 255;
BA_ "ContentDependant" SG_ 1436 IPMA_GWOnBoardTester 1;
BA_ "GenSigStartValue" SG_ 1436 IPMA_GWOnBoardTester 255;
BA_ "GenSigStartValueInteger" SG_ 1436 IPMA_GWNMProxy 255;
BA_ "ContentDependant" SG_ 1436 IPMA_GWNMProxy 1;
BA_ "GenSigStartValue" SG_ 1436 IPMA_GWNMProxy 255;
BA_ "GenSigStartValueInteger" SG_ 1436 IPMA_AutoSarNMReserved4 255;
BA_ "ContentDependant" SG_ 1436 IPMA_AutoSarNMReserved4 1;
BA_ "GenSigStartValue" SG_ 1436 IPMA_AutoSarNMReserved4 255;
BA_ "GenSigStartValueInteger" SG_ 1436 IPMA_AutoSarNMReserved3 255;
BA_ "ContentDependant" SG_ 1436 IPMA_AutoSarNMReserved3 1;
BA_ "GenSigStartValue" SG_ 1436 IPMA_AutoSarNMReserved3 255;
BA_ "GenSigStartValueInteger" SG_ 1436 IPMA_AutoSarNMReserved2 255;
BA_ "ContentDependant" SG_ 1436 IPMA_AutoSarNMReserved2 1;
BA_ "GenSigStartValue" SG_ 1436 IPMA_AutoSarNMReserved2 255;
BA_ "GenSigStartValueInteger" SG_ 1436 IPMA_AutoSarNMReserved1 255;
BA_ "ContentDependant" SG_ 1436 IPMA_AutoSarNMReserved1 1;
BA_ "GenSigStartValue" SG_ 1436 IPMA_AutoSarNMReserved1 255;
BA_ "GenSigStartValueInteger" SG_ 1436 IPMA_AutoSarNMNodeId 145;
BA_ "ContentDependant" SG_ 1436 IPMA_AutoSarNMNodeId 1;
BA_ "GenSigStartValue" SG_ 1436 IPMA_AutoSarNMNodeId 156;
BA_ "ContentDependant" SG_ 1436 IPMA_AutoSarNMControl 1;
BA_ "GenSigSendType" SG_ 2612224099 PARSEDPushSODRtoGWM_ECG 3;
BA_ "ECGUsedRxSignal" SG_ 2612224099 PARSEDPushSODRtoGWM_ECG 1;
BA_ "U_T6_MCA_MY2020_Tx" SG_ 2612224099 PARSEDPushSODRtoGWM_ECG 1;
BA_ "U_CD542_MY2021_Tx" SG_ 2612224099 PARSEDPushSODRtoGWM_ECG 1;
BA_ "GenSigSendType" SG_ 2612224098 PARSEDPushSODLtoGWM_ECG 3;
BA_ "U_T6_MCA_MY2020_Rx" SG_ 2612224098 PARSEDPushSODLtoGWM_ECG 1;
BA_ "ECGUsedRxSignal" SG_ 2612224098 PARSEDPushSODLtoGWM_ECG 1;
BA_ "U_T6_MCA_MY2020_Tx" SG_ 2612224098 PARSEDPushSODLtoGWM_ECG 1;
BA_ "U_CD542_MY2021_Tx" SG_ 2612224098 PARSEDPushSODLtoGWM_ECG 1;
BA_ "GenSigSendType" SG_ 2612224070 PARSEDPushSODCMDtoGWM 3;
BA_ "U_T6_MCA_MY2020_Rx" SG_ 2612224070 PARSEDPushSODCMDtoGWM 1;
BA_ "ECGUsedRxSignal" SG_ 2612224070 PARSEDPushSODCMDtoGWM 1;
BA_ "U_T6_MCA_MY2020_Tx" SG_ 2612224070 PARSEDPushSODCMDtoGWM 1;
BA_ "U_CD542_MY2021_Tx" SG_ 2612224070 PARSEDPushSODCMDtoGWM 1;
BA_ "GenSigSendType" SG_ 2612224069 PARSEDPushSODCMCtoGWM 3;
BA_ "ECGUsedRxSignal" SG_ 2612224069 PARSEDPushSODCMCtoGWM 1;
BA_ "U_T6_MCA_MY2020_Tx" SG_ 2612224069 PARSEDPushSODCMCtoGWM 1;
BA_ "U_CD542_MY2021_Tx" SG_ 2612224069 PARSEDPushSODCMCtoGWM 1;
BA_ "GenSigSendType" SG_ 2612224033 PARSEDPushIPMAtoGWM_ECG 3;
BA_ "U_T6_MCA_MY2020_Rx" SG_ 2612224033 PARSEDPushIPMAtoGWM_ECG 1;
BA_ "ECGUsedRxSignal" SG_ 2612224033 PARSEDPushIPMAtoGWM_ECG 1;
BA_ "U_T6_MCA_MY2020_Tx" SG_ 2612224033 PARSEDPushIPMAtoGWM_ECG 1;
BA_ "U_CD542_MY2021_Tx" SG_ 2612224033 PARSEDPushIPMAtoGWM_ECG 1;
BA_ "GenSigSendType" SG_ 2612224021 PARSEDPushCCMtoGWM_ECG 3;
BA_ "U_T6_MCA_MY2020_Rx" SG_ 2612224021 PARSEDPushCCMtoGWM_ECG 1;
BA_ "ECGUsedRxSignal" SG_ 2612224021 PARSEDPushCCMtoGWM_ECG 1;
BA_ "U_T6_MCA_MY2020_Tx" SG_ 2612224021 PARSEDPushCCMtoGWM_ECG 1;
BA_ "U_CD542_MY2021_Tx" SG_ 2612224021 PARSEDPushCCMtoGWM_ECG 1;
BA_ "GenSigSendType" SG_ 2612104408 PARSEDPushFcGWM_ECGtoSODR 3;
BA_ "U_T6_MCA_MY2020_Rx" SG_ 2612104408 PARSEDPushFcGWM_ECGtoSODR 1;
BA_ "ECGUsedTxSignal" SG_ 2612104408 PARSEDPushFcGWM_ECGtoSODR 1;
BA_ "GenSigSendType" SG_ 2612103384 PARSEDPushFcGWM_ECGtoSODL 3;
BA_ "U_T6_MCA_MY2020_Rx" SG_ 2612103384 PARSEDPushFcGWM_ECGtoSODL 1;
BA_ "ECGUsedTxSignal" SG_ 2612103384 PARSEDPushFcGWM_ECGtoSODL 1;
BA_ "GenSigSendType" SG_ 2612074712 PARSEDPushFcGWMtoSODCMD 3;
BA_ "U_T6_MCA_MY2020_Rx" SG_ 2612074712 PARSEDPushFcGWMtoSODCMD 1;
BA_ "ECGUsedTxSignal" SG_ 2612074712 PARSEDPushFcGWMtoSODCMD 1;
BA_ "GenSigSendType" SG_ 2612073688 PARSEDPushFcGWMtoSODCMC 3;
BA_ "U_T6_MCA_MY2020_Rx" SG_ 2612073688 PARSEDPushFcGWMtoSODCMC 1;
BA_ "ECGUsedTxSignal" SG_ 2612073688 PARSEDPushFcGWMtoSODCMC 1;
BA_ "GenSigSendType" SG_ 2612036824 PARSEDPushFcGWM_ECGtoIPMA 3;
BA_ "U_T6_MCA_MY2020_Rx" SG_ 2612036824 PARSEDPushFcGWM_ECGtoIPMA 1;
BA_ "ECGUsedTxSignal" SG_ 2612036824 PARSEDPushFcGWM_ECGtoIPMA 1;
BA_ "GenSigSendType" SG_ 2612024536 PARSEDPushFcGWM_ECGtoCCM 3;
BA_ "U_T6_MCA_MY2020_Rx" SG_ 2612024536 PARSEDPushFcGWM_ECGtoCCM 1;
BA_ "ECGUsedTxSignal" SG_ 2612024536 PARSEDPushFcGWM_ECGtoCCM 1;
BA_ "GenSigSendType" SG_ 785 EcoIdl_D_Stat 3;
BA_ "GenSigStartValue" SG_ 1149 BattTracPerf_Pc_Actl 254;
BA_ "GenSigStartValueInteger" SG_ 382 EngMnfldChrg_Te_Actl 126;
BA_ "GenSigStartValue" SG_ 382 EngMnfldChrg_Te_Actl 126;
BA_ "GenSigStartValueInteger" SG_ 382 EngInnrClnt_Te_Actl 56;
BA_ "GenSigStartValue" SG_ 382 EngInnrClnt_Te_Actl 126;
BA_ "ECGUsedTxSignal" SG_ 2612194520 PARSEDPushFcGWM_ECGtoCMR 1;
BA_ "GenSigSendType" SG_ 2612194520 PARSEDPushFcGWM_ECGtoCMR 3;
BA_ "ECGUsedTxSignal" SG_ 2611145944 PARSEDPhysGWM_ECGtoCMR 1;
BA_ "GenSigSendType" SG_ 2611145944 PARSEDPhysGWM_ECGtoCMR 3;
BA_ "ECGUsedTxSignal" SG_ 2610097368 OTAPhysGWM_ECGtoCMR 1;
BA_ "GenSigSendType" SG_ 2610097368 OTAPhysGWM_ECGtoCMR 3;
BA_ "ECGUsedRxSignal" SG_ 2612224187 PARSEDPushFcCMRtoGWM_ECG 1;
BA_ "GenSigSendType" SG_ 2612224187 PARSEDPushFcCMRtoGWM_ECG 3;
BA_ "ECGUsedRxSignal" SG_ 2611175611 PARSEDPhysCMRtoGWM_ECG 1;
BA_ "GenSigSendType" SG_ 2611175611 PARSEDPhysCMRtoGWM_ECG 3;
BA_ "ECGUsedRxSignal" SG_ 2610127035 OTAPhysCMRtoGWM_ECG 1;
BA_ "GenSigSendType" SG_ 2610127035 OTAPhysCMRtoGWM_ECG 3;
BA_ "ECGUsedRxSignal" SG_ 823 DteVehPwId_No_Actl 1;
BA_ "GenSigSendType" SG_ 823 DteVehPwId_No_Actl 3;
BA_ "ECGUsedRxSignal" SG_ 823 DteVehEId_No_Actl 1;
BA_ "ECGUsedRxSignal" SG_ 823 DteVehEffId_No_Actl 1;
BA_ "ECGUsedRxSignal" SG_ 823 DteVeh_Pw_Actl 1;
BA_ "ECGUsedRxSignal" SG_ 823 DteVeh_Eff_Actl 1;
BA_ "GenSigStartValue" SG_ 823 DteVeh_Eff_Actl 100;
BA_ "ECGUsedRxSignal" SG_ 823 DteVeh_E_Actl 1;
BA_ "ECGUsedRxSignal" SG_ 823 DteAcceptNew_B_Rq 1;
BA_ "GenSigSendType" SG_ 823 DteAcceptNew_B_Rq 3;
BA_ "ECGUsedTxSignal" SG_ 824 DteCldTrlrOn_B_Stat 1;
BA_ "GenSigSendType" SG_ 824 DteCldTrlrOn_B_Stat 3;
BA_ "ECGUsedTxSignal" SG_ 824 DteCldTrlrOff_B_Stat 1;
BA_ "GenSigSendType" SG_ 824 DteCldTrlrOff_B_Stat 3;
BA_ "ECGUsedTxSignal" SG_ 824 DteCldTrip_L_Actl 1;
BA_ "GenSigStartValue" SG_ 824 DteCldTrip_L_Actl 100;
BA_ "ECGUsedTxSignal" SG_ 824 DteCldTraffic_B_Stat 1;
BA_ "GenSigSendType" SG_ 824 DteCldTraffic_B_Stat 3;
BA_ "ECGUsedTxSignal" SG_ 824 DteCldTerrain_B_Stat 1;
BA_ "GenSigSendType" SG_ 824 DteCldTerrain_B_Stat 3;
BA_ "ECGUsedTxSignal" SG_ 824 DteCldRoute_B_Stat 1;
BA_ "GenSigSendType" SG_ 824 DteCldRoute_B_Stat 3;
BA_ "ECGUsedTxSignal" SG_ 824 DteCldPayload_B_Stat 1;
BA_ "GenSigSendType" SG_ 824 DteCldPayload_B_Stat 3;
BA_ "ECGUsedTxSignal" SG_ 824 DteCldId_No_Actl 1;
BA_ "GenSigSendType" SG_ 824 DteCldId_No_Actl 3;
BA_ "ECGUsedTxSignal" SG_ 824 DteCldExtTe_B_Stat 1;
BA_ "GenSigSendType" SG_ 824 DteCldExtTe_B_Stat 3;
BA_ "ECGUsedTxSignal" SG_ 824 DteCldExt_Eff_Actl 1;
BA_ "GenSigStartValue" SG_ 824 DteCldExt_Eff_Actl 100;
BA_ "ECGUsedTxSignal" SG_ 824 DteCldDrv_Eff_Actl 1;
BA_ "GenSigStartValue" SG_ 824 DteCldDrv_Eff_Actl 100;
BA_ "ECGUsedTxSignal" SG_ 824 DteCldDcac_B_Stat 1;
BA_ "GenSigSendType" SG_ 824 DteCldDcac_B_Stat 3;
BA_ "ECGUsedTxSignal" SG_ 824 DteCldClimt_Eff_Actl 1;
BA_ "GenSigStartValue" SG_ 824 DteCldClimt_Eff_Actl 100;
BA_ "ECGUsedTxSignal" SG_ 824 DteCldBattULo_Eff_Actl 1;
BA_ "GenSigStartValue" SG_ 824 DteCldBattULo_Eff_Actl 100;
BA_ "GenSigStartValue" SG_ 949 Tire_Press_RR_ORR_Data 65533;
BA_ "GenSigStartValueInteger" SG_ 949 Tire_Press_RR_ORR_Data 65533;
BA_ "GenSigStartValue" SG_ 949 Tire_Press_LR_OLR_Data 65533;
BA_ "GenSigStartValueInteger" SG_ 949 Tire_Press_LR_OLR_Data 65533;
BA_ "GenSigStartValue" SG_ 949 Tire_Press_LF_Data 65533;
BA_ "GenSigStartValueInteger" SG_ 949 Tire_Press_LF_Data 65533;
BA_ "GenSigStartValue" SG_ 949 Tire_Press_RF_Data 65533;
BA_ "GenSigStartValueInteger" SG_ 949 Tire_Press_RF_Data 65533;
BA_ "GenSigSendType" SG_ 1825 TesterPhysicalReqVDM 3;
BA_ "ContentDependant" SG_ 524 PrplWhlTotTqRqMxAwd_No_Cs 1;
BA_ "MetaData" SG_ 524 PrplWhlTotTqRqMxAwd_No_Cs 1;
BA_ "U_T6_MCA_MY2020_Rx" SG_ 524 PrplWhlTotTqRqMxAwd_No_Cs 1;
BA_ "U_T6_MCA_MY2020_Tx" SG_ 524 PrplWhlTotTqRqMxAwd_No_Cs 1;
BA_ "GenSigStartValueInteger" SG_ 524 PrplWhlTot_Tq_RqMxAwd 65535;
BA_ "GenSigStartValue" SG_ 524 PrplWhlTot_Tq_RqMxAwd 65535;
BA_ "U_T6_MCA_MY2020_Rx" SG_ 524 PrplWhlTot_Tq_RqMxAwd 1;
BA_ "U_T6_MCA_MY2020_Tx" SG_ 524 PrplWhlTot_Tq_RqMxAwd 1;
BA_ "ContentDependant" SG_ 524 PrplWhlTotTqRqMxAwd_No_Cnt 1;
BA_ "MetaData" SG_ 524 PrplWhlTotTqRqMxAwd_No_Cnt 1;
BA_ "U_T6_MCA_MY2020_Rx" SG_ 524 PrplWhlTotTqRqMxAwd_No_Cnt 1;
BA_ "U_T6_MCA_MY2020_Tx" SG_ 524 PrplWhlTotTqRqMxAwd_No_Cnt 1;
BA_ "U_CX727_MY2021_Rx" SG_ 740 BattAuxCnnct_B_Cmd 1;
BA_ "ECGUsedTxSignal" SG_ 1160 VgfZone_D_Stat 1;
BA_ "GenSigSendType" SG_ 1160 VgfZone_D_Stat 3;
BA_ "GenSigSendType" SG_ 1160 PwSustnRdata_B_RqTelem 3;
BA_ "ECGUsedTxSignal" SG_ 1160 PwSustnRdata_B_RqTelem 1;
BA_ "GenSigSendType" SG_ 1160 DataMntrSustn_B_Rq 3;
BA_ "ECGUsedTxSignal" SG_ 1160 DataMntrSustn_B_Rq 1;
BA_ "GenSigSendType" SG_ 1160 DcacPwReset_B_RqCell 3;
BA_ "ECGUsedTxSignal" SG_ 1160 DcacPwReset_B_RqCell 1;
BA_ "U_U55X_MY2022_Tx" SG_ 1160 DcacPwReset_B_RqCell 1;
BA_ "GenSigSendType" SG_ 1160 DcacPw_D_RqCell 3;
BA_ "ECGUsedTxSignal" SG_ 1160 DcacPw_D_RqCell 1;
BA_ "U_U55X_MY2022_Tx" SG_ 1160 DcacPw_D_RqCell 1;
BA_ "ECGUsedTxSignal" SG_ 1160 DgtlCommPncReset_B_Req 1;
BA_ "GenSigSendType" SG_ 1160 DgtlCommPncReset_B_Req 3;
BA_ "GenSigStartValue" SG_ 811 DistToStopover_L_Actl 65535;
BA_ "WakeupSignal" SG_ 811 ExtLghtRight_D_RqMnu 1;
BA_ "WakeupSignal" SG_ 811 AutoLghtOvrrd_B_RqDrv 1;
BA_ "WakeupSignal" SG_ 811 ExtLghtRear_D_RqMnu 1;
BA_ "WakeupSignal" SG_ 811 ExtLghtLeft_D_RqMnu 1;
BA_ "WakeupSignal" SG_ 811 ExtLghtFront_D_RqMnu 1;
BA_ "GenSigStartValue" SG_ 811 GoTEditMnte_T_RqMnu 14;
BA_ "GenSigStartValue" SG_ 811 GoTEditHr_T_RqMnu 30;
BA_ "U_CX727_MY2021_Tx" SG_ 850 VehElRngeNut_L_Dsply 1;
BA_ "U_CX727_MY2021_Tx" SG_ 850 NxtUsgSocEst_Pc_Dsply 1;
BA_ "U_CX727_MY2021_Tx" SG_ 850 EstmChrgTimeLP_St 1;
BA_ "ECGUsedRxSignal" SG_ 850 EstmChrgTimeLP_St 1;
BA_ "U_CX727_MY2021_Tx" SG_ 850 EstmChrgTimeHP_St 1;
BA_ "ECGUsedRxSignal" SG_ 850 EstmChrgTimeHP_St 1;
BA_ "U_CX727_MY2021_Tx" SG_ 850 ChargeNowDuration_St 1;
BA_ "ECGUsedRxSignal" SG_ 850 ChargeNowDuration_St 1;
BA_ "GenSigSendType" SG_ 563 DrvBhavWarn_B_Rq 3;
BA_ "ECGUsedTxSignal" SG_ 563 DrvBhavWarn_B_Rq 1;
BA_ "ECGUsedTxSignal" SG_ 563 OfbChrgSetSync_D_Rq 1;
BA_ "GenSigSendType" SG_ 563 KeyOffPwMde_D_Stat 3;
BA_ "ECGUsedTxSignal" SG_ 563 KeyOffPwMde_D_Stat 1;
BA_ "GenSigSendType" SG_ 563 ModemReset_D_Stat 3;
BA_ "ECGUsedTxSignal" SG_ 563 ModemReset_D_Stat 1;
BA_ "GenSigSendType" SG_ 563 FactoryReset_St 3;
BA_ "ECGUsedTxSignal" SG_ 563 FactoryReset_St 1;
BA_ "GenSigSendType" SG_ 1833 TesterPhysicalResVDM 3;
VAL_ 140 DcacPwResetBttn_D_Stat 3 "NotUsed" 2 "Stuck" 1 "Pressed" 0 "Not_Pressed" ;
VAL_ 986 PsngrLoad_M_Rq 1023 "Faulty" 1022 "NoDataExists" ;
VAL_ 986 Trlr_M_Rq 2047 "Faulty" 2046 "NoDataExists" ;
VAL_ 986 VehFalr_D_Rq 7 "NotUsed_3" 6 "NotUsed_2" 5 "NotUsed_1" 4 "NotComplete" 3 "Complete" 2 "RequestSecondMeasurement" 1 "RequestFirstMeasurement" 0 "NoRequest" ;
VAL_ 986 TailLghtLoadMde_D_Rq 7 "NotUsed_3" 6 "NotUsed_2" 5 "NotUsed_1" 4 "DeactivateAll" 3 "ActivateFalrMode" 2 "ActivateHitchLoadMode" 1 "ActivatePayloadMode" 0 "NoCommand" ;
VAL_ 986 VehPayloadTare_D_Rq 1 "Request" 0 "NoRequest" ;
VAL_ 986 VehPayloadScrn_D_Rq 7 "CheckLoadScreenActive" 6 "WeightCarryScreenActive" 5 "GooseneckScreenActive" 4 "FifthWheelScreenActive" 3 "WeightDistScreenActive" 2 "AddMassEstScreenActive" 1 "PayloadEstScreenActive" 0 "ScaleScreenNotActive" ;
VAL_ 986 LightAmbIntsty_No_Rq 0 "Off" ;
VAL_ 991 PsngrLoad_D_Stat 3 "NotUsed_1" 2 "Accepted" 1 "NotAccepted" 0 "Inactive" ;
VAL_ 991 VehPayloadScrn_D_Stat 7 "CheckLoadScreenActive" 6 "WeightCarryScreenActive" 5 "GooseneckScreenActive" 4 "FifthWheelScreenActive" 3 "WeightDistScreenActive" 2 "AddMassEstScreenActive" 1 "PayloadEstScreenActive" 0 "ScaleScreenNotActive" ;
VAL_ 991 VehPayloadTireP_B_Stat 1 "Yes" 0 "No" ;
VAL_ 991 VehPayloadFlat_B_Stat 1 "Yes" 0 "No" ;
VAL_ 991 TrlrTngLoad_D_Stat 7 "Faulty" 6 "NoDataExists" 5 "NotUsed_3" 4 "NotUsed_2" 3 "NotUsed_1" 2 "AboveRange" 1 "InRange" 0 "BelowRange" ;
VAL_ 991 VehPayloadStew_B_Stat 1 "Yes" 0 "No" ;
VAL_ 991 VehPayloadTare_D_Stat 3 "Faulty" 2 "NotUsed" 1 "Request" 0 "NoRequest" ;
VAL_ 991 VehPayloadGear_B_Stat 1 "Yes" 0 "No" ;
VAL_ 991 VehFalr_D_Stat 7 "Faulty" 6 "NotUsed_3" 5 "NotUsed_2" 4 "NotUsed_1" 3 "HeightCorrectionCompleted" 2 "SecondMeasurementCollected" 1 "FirstMeasurementCollected" 0 "NotActive" ;
VAL_ 991 Trlr_M_Actl 2047 "Faulty" 2046 "NoDataExists" ;
VAL_ 571 VehFalr_Pc_Est 127 "Faulty" 126 "NoDataExists" ;
VAL_ 571 TrlrTngLoad_Pc_Est 127 "Faulty" 126 "NoDataExists" ;
VAL_ 571 TrlrTngLoad_M_Est 2047 "Faulty" 2046 "NoDataExists" ;
VAL_ 571 VehPayloadAdd_M_Est 2047 "Faulty" 2046 "NoDataExists" ;
VAL_ 571 VehPayload_Pc_Est 127 "Faulty" 126 "NoDataExists" ;
VAL_ 571 VehPayload_M_Est 1023 "Faulty" 1022 "NoDataExists" ;
VAL_ 1242 SelDrvMdeCstmPt_D_Rq 31 "Faulty" 30 "NotUsed15" 29 "NotUsed14" 28 "NotUsed13" 27 "NotUsed12" 26 "NotUsed11" 25 "NotUsed10" 24 "NotUsed9" 23 "NotUsed8" 22 "NotUsed7" 21 "CustomMode" 20 "TrackMode" 19 "OnePedalDrive" 18 "EvLaterChargerMode" 17 "EvNowMode" 16 "DragMode" 15 "HighSpeedDesertMode_Baja" 14 "SportAdaptiveMode" 13 "NotAvailable_13" 12 "NotAvailable_12" 11 "NotAvailable_11" 10 "NotAvailable_10" 9 "RockCrawlMode" 8 "MudRutsMode" 7 "SandMode" 6 "EconomyMode" 5 "GrassGravelSnow" 4 "NotAvailable_04" 3 "TowHaulMode" 2 "NotAvailable_02" 1 "SportMode" 0 "NormalMode" ;
VAL_ 1242 EngExhMdeQuietCstm_D_Rq 7 "Faulty" 6 "NotUsed_2" 5 "NotUsed_1" 4 "Track" 3 "Sport" 2 "Normal" 1 "Stealth" 0 "Null" ;
VAL_ 1242 StopStrtCstm_D_Rq 3 "Faulty" 2 "On" 1 "Off" 0 "NotAvailable" ;
VAL_ 1245 RearDiffLckLamp_D_Cstm 3 "Not_Used" 2 "Flash" 1 "On" 0 "Off" ;
VAL_ 1245 FrontDiffLckLamp_D_Cstm 3 "Fast_Flash" 2 "Slow_Flash" 1 "On" 0 "Off" ;
VAL_ 1245 AwdMdeCstm_D_RqDrv 7 "Faulty" 6 "NotUsed_3" 5 "NotUsed_2" 4 "NotUsed_1" 3 "FourByFourLow" 2 "FourByFourHigh" 1 "FourByFourAuto" 0 "FourByTwo" ;
VAL_ 1245 SelDrvMdeAwd2_D_Cstm 31 "Faulty" 30 "NotUsed_17" 29 "NotUsed_16" 28 "NotUsed_15" 27 "NotUsed_14" 26 "NotUsed_13" 25 "NotUsed_12" 24 "NotUsed_11" 23 "NotUsed_10" 22 "NotUsed_9" 21 "NotUsed_8" 20 "CustomMode" 19 "OnePedalDrive" 18 "DragMode" 17 "EvLaterChargeMode" 16 "EvNowMode" 15 "TrackMode" 14 "RoughRoadMode" 13 "NotAvailable" 12 "HighSpeedDesertMode_Baja" 11 "SportAdaptiveMode" 10 "RockCrawlMode" 9 "MudRutsMode" 8 "SandMode" 7 "EconomyMode" 6 "GrassGravelSnow" 5 "TowHaulMode" 4 "SportMode" 3 "Normal_4L" 2 "Normal_4A" 1 "Normal_2H" 0 "NormalMode" ;
VAL_ 1239 SelDrvMdeCstmLamp_D_Rq 3 "NotUsed2" 2 "NotUsed1" 1 "On" 0 "Off" ;
VAL_ 1239 SelDrvMdeCstm_D_RqDrv 7 "Faulty" 6 "NotUsed_3" 5 "NotUsed_2" 4 "NotUsed_1" 3 "Recall" 2 "Save" 1 "Activate" 0 "Null" ;
VAL_ 1239 StabBarCnnctLamp_D_Cstm 3 "Fast_Flash" 2 "Slow_Flash" 1 "On" 0 "Off" ;
VAL_ 1239 CstmDrvMdeMsgTxt_D_Rq 15 "Message15" 14 "Message14" 13 "Message13" 12 "Message12" 11 "Message11" 10 "Message10" 9 "Message9" 8 "Message8" 7 "Message7" 6 "Message6" 5 "Message5" 4 "Message4" 3 "Message3" 2 "Message2" 1 "Message1" 0 "NoMessage" ;
VAL_ 1239 ActvDrvMdeCstm_D2_Rq 31 "Faulty" 30 "SelDrvMde31" 29 "SelDrvMde30" 28 "SelDrvMde29" 27 "SelDrvMde28" 26 "SelDrvMde27" 25 "SelDrvMde26" 24 "SelDrvMde25" 23 "SelDrvMde24" 22 "SelDrvMde23" 21 "SelDrvMde22" 20 "SelDrvMde21" 19 "SelDrvMde20" 18 "SelDrvMde19" 17 "SelDrvMde18" 16 "SelDrvMde17" 15 "SelDrvMde16" 14 "SelDrvMde15" 13 "SelDrvMde14" 12 "SelDrvMde13" 11 "SelDrvMde12" 10 "SelDrvMde11" 9 "SelDrvMde10" 8 "SelDrvMde09" 7 "SelDrvMde08" 6 "SelDrvMde07" 5 "SelDrvMde06" 4 "SelDrvMde05" 3 "SelDrvMde04" 2 "SelDrvMde03" 1 "SelDrvMde02" 0 "SelDrvMde01" ;
VAL_ 1049 Fba_D_Rq 3 "NotUsed" 2 "On" 1 "Off" 0 "Null" ;
VAL_ 1049 TurnAsstSwtch_D_Stat 3 "Faulty" 2 "NotUsed" 1 "Pressed" 0 "Not_Pressed" ;
VAL_ 739 EngExhMdeHrStrt_D_Rq 31 "NotUsed_7" 30 "NotUsed_6" 29 "NotUsed_5" 28 "NotUsed_4" 27 "NotUsed_3" 26 "NotUsed_2" 25 "NotUsed_1" 24 "Hour23_11pm" 23 "Hour22_10pm" 22 "Hour21_9pm" 21 "Hour20_8pm" 20 "Hour19_7pm" 19 "Hour18_6pm" 18 "Hour17_5pm" 17 "Hour16_4pm" 16 "Hour15_3pm" 15 "Hour14_2pm" 14 "Hour13_1pm" 13 "Hour12_12pm" 12 "Hour11_11am" 11 "Hour10_10am" 10 "Hour9_9am" 9 "Hour8_8am" 8 "Hour7_7am" 7 "Hour6_6am" 6 "Hour5_5am" 5 "Hour4_4am" 4 "Hour3_3am" 3 "Hour2_2am" 2 "Hour1_1am" 1 "Hour0_12am" 0 "Null" ;
VAL_ 739 EngExhMdeHrEnd_D_Rq 31 "NotUsed_7" 30 "NotUsed_6" 29 "NotUsed_5" 28 "NotUsed_4" 27 "NotUsed_3" 26 "NotUsed_2" 25 "NotUsed_1" 24 "Hour23_11pm" 23 "Hour22_10pm" 22 "Hour21_9pm" 21 "Hour20_8pm" 20 "Hour19_7pm" 19 "Hour18_6pm" 18 "Hour17_5pm" 17 "Hour16_4pm" 16 "Hour15_3pm" 15 "Hour14_2pm" 14 "Hour13_1pm" 13 "Hour12_12pm" 12 "Hour11_11am" 11 "Hour10_10am" 10 "Hour9_9am" 9 "Hour8_8am" 8 "Hour7_7am" 7 "Hour6_6am" 6 "Hour5_5am" 5 "Hour4_4am" 4 "Hour3_3am" 3 "Hour2_2am" 2 "Hour1_1am" 1 "Hour0_12am" 0 "Null" ;
VAL_ 739 EngExhMdeHrEnbl_D_Rq 3 "NotConfigured" 2 "Enabled" 1 "Disabled" 0 "Null" ;
VAL_ 739 Partial_Amp_Shutdown 1 "Active" 0 "Inactive" ;
VAL_ 739 HMI_HMIMode_St 7 "NotUsed2" 6 "NotUsed1" 5 "Load_Shed_Active" 0 "Invalid" 1 "OffMode" 2 "On" 3 "Phone" 4 "Climate" ;
VAL_ 1205 CstmDrvMdeCfg2_B_Avail 1 "Available" 0 "NotAvailable" ;
VAL_ 1205 CstmDrvMdeCfg1_B_Avail 1 "Available" 0 "NotAvailable" ;
VAL_ 1043 SelDrvMdeHmi02_D_Rq 31 "Faulty" 30 "SelDrvMde31" 29 "SelDrvMde30" 28 "SelDrvMde29" 27 "SelDrvMde28" 26 "SelDrvMde27" 25 "SelDrvMde26" 24 "SelDrvMde25" 23 "SelDrvMde24" 22 "SelDrvMde23" 21 "SelDrvMde22" 20 "SelDrvMde21" 19 "SelDrvMde20" 18 "SelDrvMde19" 17 "SelDrvMde18" 16 "SelDrvMde17" 15 "SelDrvMde16" 14 "SelDrvMde15" 13 "SelDrvMde14" 12 "SelDrvMde13" 11 "SelDrvMde12" 10 "SelDrvMde11" 9 "SelDrvMde10" 8 "SelDrvMde09" 7 "SelDrvMde08" 6 "SelDrvMde07" 5 "SelDrvMde06" 4 "SelDrvMde05" 3 "SelDrvMde04" 2 "SelDrvMde03" 1 "SelDrvMde02" 0 "SelDrvMde01" ;
VAL_ 1043 IndvMdeSel_D_Stat 3 "NotUsed" 2 "DriveModeChangeRequest" 1 "DriveModeChangeSelection" 0 "NoDriveModeChangeRequest" ;
VAL_ 1043 IndvMdeMsgTxt_D_Rq 15 "Message15" 14 "Message14" 13 "Message13" 12 "Message12" 11 "Message11" 10 "Message10" 9 "Message9" 8 "Message8" 7 "Message7" 6 "Message6" 5 "Message5" 4 "Message4" 3 "Message3" 2 "Message2" 1 "Message1" 0 "NoMessage" ;
VAL_ 1043 IndvMde5_B_Avail 1 "Available" 0 "NotAvailable" ;
VAL_ 1043 IndvMde4_B_Avail 1 "Available" 0 "NotAvailable" ;
VAL_ 1043 IndvMde3_B_Avail 1 "Available" 0 "NotAvailable" ;
VAL_ 1043 IndvMde2_B_Avail 1 "Available" 0 "NotAvailable" ;
VAL_ 1043 IndvMde1_B_Avail 1 "Available" 0 "NotAvailable" ;
VAL_ 1043 TrailOnePdlMde_D_Ind 7 "NotUsed_4" 6 "NotUsed_3" 5 "NotUsed_2" 4 "NotUsed_1" 3 "Standby" 2 "Active" 1 "Fault" 0 "Off" ;
VAL_ 1043 TrailOnePdlMsgTxt_D_Rq 7 "Message7" 6 "Message6" 5 "Message5" 4 "Message4" 3 "Message3" 2 "Message2" 1 "Message1" 0 "NoMessage" ;
VAL_ 1043 OrtaSwtchLamp_B_Rq 1 "On" 0 "Off" ;
VAL_ 1043 OrtaMsgTxt_D_Rq 15 "Message15" 14 "Message14" 13 "Message13" 12 "Message12" 11 "Message11" 10 "Message10" 9 "Message9" 8 "Message8" 7 "Message7" 6 "Message6" 5 "Message5" 4 "Message4" 3 "Message3" 2 "Message2" 1 "Message1" 0 "NoMessage" ;
VAL_ 1043 OrtaMde_D_Ind 7 "Faulty" 6 "NotUsed_2" 5 "NotUsed_1" 4 "ActiveRight" 3 "ActiveLeft" 2 "StandbyRight" 1 "StandbyLeft" 0 "Off" ;
VAL_ 785 EcoIdl_D_Stat 3 "NotUsed" 2 "Enabled" 1 "Disabled" 0 "Null" ;
VAL_ 1149 BattTracPerf_Pc_Actl 255 "Faulty" 254 "NoDataExists" ;
VAL_ 382 EngMnfldChrg_Te_Actl 127 "Faulty" 126 "NoDataExists" ;
VAL_ 382 EngInnrClnt_Te_Actl 127 "Faulty" 126 "NoDataExists" ;
VAL_ 382 DcacOut2_Pw2_Dsply 8191 "Faulty" 8190 "NoDataExists" ;
VAL_ 382 DcacOut1_Pw2_Dsply 8191 "Faulty" 8190 "NoDataExists" ;
VAL_ 823 DteAcceptNew_B_Rq 1 "Yes" 0 "No" ;
VAL_ 824 DteCldTrlrOn_B_Stat 1 "Yes" 0 "No" ;
VAL_ 824 DteCldTrlrOff_B_Stat 1 "Yes" 0 "No" ;
VAL_ 824 DteCldTraffic_B_Stat 1 "Yes" 0 "No" ;
VAL_ 824 DteCldTerrain_B_Stat 1 "Yes" 0 "No" ;
VAL_ 824 DteCldRoute_B_Stat 1 "Yes" 0 "No" ;
VAL_ 824 DteCldPayload_B_Stat 1 "Yes" 0 "No" ;
VAL_ 824 DteCldExtTe_B_Stat 1 "Yes" 0 "No" ;
VAL_ 824 DteCldDcac_B_Stat 1 "Yes" 0 "No" ;
VAL_ 949 Tire_Press_RR_ORR_Data 65535 "Not_Supported" 65534 "Invalid" 65533 "Unknown" ;
VAL_ 949 Tire_Press_LR_OLR_Data 65535 "Not_Supported" 65534 "Invalid" 65533 "Unknown" ;
VAL_ 949 Tire_Press_LF_Data 65535 "Not_Supported" 65534 "Invalid" 65533 "Unknown" ;
VAL_ 949 Tire_Press_RF_Data 65535 "Not_Supported" 65534 "Invalid" 65533 "Unknown" ;
VAL_ 740 BattAuxCnnct_B_Cmd 1 "Close" 0 "Open" ;
VAL_ 1160 VgfZone_D_Stat 7 "Faulty" 6 "NotUsed_2" 5 "NotUsed_1" 4 "GPS_Unavailable" 3 "Restricted_Zone" 2 "Warning_Zone" 1 "Allowed_Zone" 0 "Off_Normal" ;
VAL_ 1160 PwSustnRdata_B_RqTelem 1 "Active" 0 "Inactive" ;
VAL_ 1160 DataMntrSustn_B_Rq 1 "Active" 0 "Inactive" ;
VAL_ 1160 DcacPwReset_B_RqCell 1 "Reset" 0 "Null" ;
VAL_ 1160 DcacPw_D_RqCell 3 "High" 2 "Low" 1 "Off" 0 "Null" ;
VAL_ 1160 DgtlCommPncReset_B_Req 1 "Yes" 0 "No" ;
VAL_ 811 DistToStopover_L_Actl 65535 "Faulty" ;
VAL_ 811 ExtLghtDsply_D_Stat 7 "NotUsed" 6 "PressToOn3" 5 "PressToOff3" 4 "PressToOn2" 3 "PressToOff2" 2 "PressToOn1" 1 "PressToOff1" 0 "Reset" ;
VAL_ 811 ExtLghtRight_D_RqMnu 7 "NotUsed" 6 "PressToOn3" 5 "PressToOff3" 4 "PressToOn2" 3 "PressToOff2" 2 "PressToOn1" 1 "PressToOff1" 0 "Reset" ;
VAL_ 811 AutoLghtOvrrd_B_RqDrv 1 "Allowed" 0 "NotAllowed" ;
VAL_ 811 ExtLghtRear_D_RqMnu 7 "NotUsed" 6 "PressToOn3" 5 "PressToOff3" 4 "PressToOn2" 3 "PressToOff2" 2 "PressToOn1" 1 "PressToOff1" 0 "Reset" ;
VAL_ 811 ExtLghtLeft_D_RqMnu 7 "NotUsed" 6 "PressToOn3" 5 "PressToOff3" 4 "PressToOn2" 3 "PressToOff2" 2 "PressToOn1" 1 "PressToOff1" 0 "Reset" ;
VAL_ 811 ExtLghtFront_D_RqMnu 7 "NotUsed" 6 "PressToOn3" 5 "PressToOff3" 4 "PressToOn2" 3 "PressToOff2" 2 "PressToOn1" 1 "PressToOff1" 0 "Reset" ;
VAL_ 811 GoTEditMnte_T_RqMnu 15 "Faulty" 14 "NoDataExists" 13 "NotUsed_2" 12 "NotUsed_1" 11 "Minute_55" 10 "Minute_50" 9 "Minute_45" 8 "Minute_40" 7 "Minute_35" 6 "Minute_30" 5 "Minute_25" 4 "Minute_20" 3 "Minute_15" 2 "Minute_10" 1 "Minute_5" 0 "Minute_0" ;
VAL_ 811 GoTEditHr_T_RqMnu 31 "Faulty" 30 "NoDataExists" ;
VAL_ 850 VehElRngeNut_L_Dsply 4095 "Faulty" 4094 "NoDataExists" ;
VAL_ 850 NxtUsgSocEst_Pc_Dsply 255 "Faulty" 254 "NoDataExists" ;
VAL_ 850 EstmChrgTimeLP_St 255 "Invalid" ;
VAL_ 850 EstmChrgTimeHP_St 255 "Invalid" ;
VAL_ 850 ChargeNowDuration_St 255 "Invalid" ;
VAL_ 563 DrvBhavWarn_B_Rq 1 "On" 0 "Off" ;
VAL_ 563 OfbChrgSetSync_D_Rq 3 "Fail" 2 "Success" 1 "InProgress" 0 "NoSyncInProgress" ;
VAL_ 563 KeyOffPwMde_D_Stat 7 "NotUsed_6" 6 "NotUsed_5" 5 "NotUsed_4" 4 "NotUsed_3" 0 "Inactive" 1 "On" 2 "NotUsed_1" 3 "NotUsed_2" ;
VAL_ 563 ModemReset_D_Stat 15 "NotUsed_10" 14 "NotUsed_9" 13 "NotUsed_8" 12 "NotUsed_7" 11 "NotUsed_6" 10 "NotUsed_5" 9 "NotUsed_4" 8 "NotUsed_3" 7 "NotUsed_2" 6 "NotUsed_1" 5 "WifiHotSpotResetComplete" 4 "CcsResetComplete" 3 "OnlineTrafficResetComplete" 2 "PaakResetComplete" 1 "ResetNotComplete" 0 "Null" ;
VAL_ 563 FactoryReset_St 3 "NotUsed_2" 2 "NotUsed_1" 1 "FactoryDefaultsRestored" 0 "Null" ;
